VERSION "FL_IC_CANFD"

NS_ :

BS_:

BU_: AVAS BBCM CMSM DVR EAMP EPC FLZCU ICC PCL PLG SBOX SCU

BO_ 1364 ICC_RISD_44: 64 ICC
 SG_ ICC_RISD_FrameCounter : 1|2@0+ (1,0) [0|3] ""  FLZCU
 SG_ ICC_RISD_RollingCounter : 3|2@0+ (1,0) [0|3] ""  FLZCU
 SG_ ICC_RISD_Pixel1_OnOff : 8|1@0+ (1,0) [0|1] ""  FLZCU
 SG_ ICC_RISD_Pixel2_OnOff : 9|1@0+ (1,0) [0|1] ""  FLZCU
 SG_ ICC_RISD_Pixel3_OnOff : 10|1@0+ (1,0) [0|1] ""  FLZCU
 SG_ ICC_RISD_Pixel4_OnOff : 11|1@0+ (1,0) [0|1] ""  FLZCU
 SG_ ICC_RISD_Pixel5_OnOff : 12|1@0+ (1,0) [0|1] ""  FLZCU
 SG_ ICC_RISD_Pixel6_OnOff : 13|1@0+ (1,0) [0|1] ""  FLZCU
 SG_ ICC_RISD_Pixel7_OnOff : 14|1@0+ (1,0) [0|1] ""  FLZCU
 SG_ ICC_RISD_Pixel8_OnOff : 15|1@0+ (1,0) [0|1] ""  FLZCU
 SG_ ICC_RISD_Pixel9_OnOff : 16|1@0+ (1,0) [0|1] ""  FLZCU
 SG_ ICC_RISD_Pixel10_OnOff : 17|1@0+ (1,0) [0|1] ""  FLZCU
 SG_ ICC_RISD_Pixel11_OnOff : 18|1@0+ (1,0) [0|1] ""  FLZCU
 SG_ ICC_RISD_Pixel12_OnOff : 19|1@0+ (1,0) [0|1] ""  FLZCU
 SG_ ICC_RISD_Pixel13_OnOff : 20|1@0+ (1,0) [0|1] ""  FLZCU
 SG_ ICC_RISD_Pixel14_OnOff : 21|1@0+ (1,0) [0|1] ""  FLZCU
 SG_ ICC_RISD_Pixel15_OnOff : 22|1@0+ (1,0) [0|1] ""  FLZCU
 SG_ ICC_RISD_Pixel16_OnOff : 23|1@0+ (1,0) [0|1] ""  FLZCU
 SG_ ICC_RISD_Pixel17_OnOff : 24|1@0+ (1,0) [0|1] ""  FLZCU
 SG_ ICC_RISD_Pixel18_OnOff : 25|1@0+ (1,0) [0|1] ""  FLZCU
 SG_ ICC_RISD_Pixel19_OnOff : 26|1@0+ (1,0) [0|1] ""  FLZCU
 SG_ ICC_RISD_Pixel20_OnOff : 27|1@0+ (1,0) [0|1] ""  FLZCU
 SG_ ICC_RISD_Pixel21_OnOff : 28|1@0+ (1,0) [0|1] ""  FLZCU
 SG_ ICC_RISD_Pixel22_OnOff : 29|1@0+ (1,0) [0|1] ""  FLZCU
 SG_ ICC_RISD_Pixel23_OnOff : 30|1@0+ (1,0) [0|1] ""  FLZCU
 SG_ ICC_RISD_Pixel24_OnOff : 31|1@0+ (1,0) [0|1] ""  FLZCU
 SG_ ICC_RISD_Pixel25_OnOff : 32|1@0+ (1,0) [0|1] ""  FLZCU
 SG_ ICC_RISD_Pixel26_OnOff : 33|1@0+ (1,0) [0|1] ""  FLZCU
 SG_ ICC_RISD_Pixel27_OnOff : 34|1@0+ (1,0) [0|1] ""  FLZCU
 SG_ ICC_RISD_Pixel28_OnOff : 35|1@0+ (1,0) [0|1] ""  FLZCU
 SG_ ICC_RISD_Pixel29_OnOff : 36|1@0+ (1,0) [0|1] ""  FLZCU
 SG_ ICC_RISD_Pixel30_OnOff : 37|1@0+ (1,0) [0|1] ""  FLZCU
 SG_ ICC_RISD_Pixel31_OnOff : 38|1@0+ (1,0) [0|1] ""  FLZCU
 SG_ ICC_RISD_Pixel32_OnOff : 39|1@0+ (1,0) [0|1] ""  FLZCU
 SG_ ICC_RISD_Pixel33_OnOff : 40|1@0+ (1,0) [0|1] ""  FLZCU
 SG_ ICC_RISD_Pixel34_OnOff : 41|1@0+ (1,0) [0|1] ""  FLZCU
 SG_ ICC_RISD_Pixel35_OnOff : 42|1@0+ (1,0) [0|1] ""  FLZCU
 SG_ ICC_RISD_Pixel36_OnOff : 43|1@0+ (1,0) [0|1] ""  FLZCU
 SG_ ICC_RISD_Pixel37_OnOff : 44|1@0+ (1,0) [0|1] ""  FLZCU
 SG_ ICC_RISD_Pixel38_OnOff : 45|1@0+ (1,0) [0|1] ""  FLZCU
 SG_ ICC_RISD_Pixel39_OnOff : 46|1@0+ (1,0) [0|1] ""  FLZCU
 SG_ ICC_RISD_Pixel40_OnOff : 47|1@0+ (1,0) [0|1] ""  FLZCU
 SG_ ICC_RISD_Pixel41_OnOff : 48|1@0+ (1,0) [0|1] ""  FLZCU
 SG_ ICC_RISD_Pixel42_OnOff : 49|1@0+ (1,0) [0|1] ""  FLZCU
 SG_ ICC_RISD_Pixel43_OnOff : 50|1@0+ (1,0) [0|1] ""  FLZCU
 SG_ ICC_RISD_Pixel44_OnOff : 51|1@0+ (1,0) [0|1] ""  FLZCU
 SG_ ICC_RISD_Pixel45_OnOff : 52|1@0+ (1,0) [0|1] ""  FLZCU
 SG_ ICC_RISD_Pixel46_OnOff : 53|1@0+ (1,0) [0|1] ""  FLZCU
 SG_ ICC_RISD_Pixel47_OnOff : 54|1@0+ (1,0) [0|1] ""  FLZCU
 SG_ ICC_RISD_Pixel48_OnOff : 55|1@0+ (1,0) [0|1] ""  FLZCU
 SG_ ICC_RISD_Pixel49_OnOff : 56|1@0+ (1,0) [0|1] ""  FLZCU
 SG_ ICC_RISD_Pixel50_OnOff : 57|1@0+ (1,0) [0|1] ""  FLZCU
 SG_ ICC_RISD_Pixel51_OnOff : 58|1@0+ (1,0) [0|1] ""  FLZCU
 SG_ ICC_RISD_Pixel52_OnOff : 59|1@0+ (1,0) [0|1] ""  FLZCU
 SG_ ICC_RISD_Pixel53_OnOff : 60|1@0+ (1,0) [0|1] ""  FLZCU
 SG_ ICC_RISD_Pixel54_OnOff : 61|1@0+ (1,0) [0|1] ""  FLZCU
 SG_ ICC_RISD_Pixel55_OnOff : 62|1@0+ (1,0) [0|1] ""  FLZCU
 SG_ ICC_RISD_Pixel56_OnOff : 63|1@0+ (1,0) [0|1] ""  FLZCU
 SG_ ICC_RISD_Pixel57_OnOff : 64|1@0+ (1,0) [0|1] ""  FLZCU
 SG_ ICC_RISD_Pixel58_OnOff : 65|1@0+ (1,0) [0|1] ""  FLZCU
 SG_ ICC_RISD_Pixel59_OnOff : 66|1@0+ (1,0) [0|1] ""  FLZCU
 SG_ ICC_RISD_Pixel60_OnOff : 67|1@0+ (1,0) [0|1] ""  FLZCU
 SG_ ICC_RISD_Pixel61_OnOff : 68|1@0+ (1,0) [0|1] ""  FLZCU
 SG_ ICC_RISD_Pixel62_OnOff : 69|1@0+ (1,0) [0|1] ""  FLZCU
 SG_ ICC_RISD_Pixel63_OnOff : 70|1@0+ (1,0) [0|1] ""  FLZCU
 SG_ ICC_RISD_Pixel64_OnOff : 71|1@0+ (1,0) [0|1] ""  FLZCU
 SG_ ICC_RISD_Pixel65_OnOff : 72|1@0+ (1,0) [0|1] ""  FLZCU
 SG_ ICC_RISD_Pixel66_OnOff : 73|1@0+ (1,0) [0|1] ""  FLZCU
 SG_ ICC_RISD_Pixel67_OnOff : 74|1@0+ (1,0) [0|1] ""  FLZCU
 SG_ ICC_RISD_Pixel68_OnOff : 75|1@0+ (1,0) [0|1] ""  FLZCU
 SG_ ICC_RISD_Pixel69_OnOff : 76|1@0+ (1,0) [0|1] ""  FLZCU
 SG_ ICC_RISD_Pixel70_OnOff : 77|1@0+ (1,0) [0|1] ""  FLZCU
 SG_ ICC_RISD_Pixel71_OnOff : 78|1@0+ (1,0) [0|1] ""  FLZCU
 SG_ ICC_RISD_Pixel72_OnOff : 79|1@0+ (1,0) [0|1] ""  FLZCU
 SG_ ICC_RISD_Pixel73_OnOff : 80|1@0+ (1,0) [0|1] ""  FLZCU
 SG_ ICC_RISD_Pixel74_OnOff : 81|1@0+ (1,0) [0|1] ""  FLZCU
 SG_ ICC_RISD_Pixel75_OnOff : 82|1@0+ (1,0) [0|1] ""  FLZCU
 SG_ ICC_RISD_Pixel76_OnOff : 83|1@0+ (1,0) [0|1] ""  FLZCU
 SG_ ICC_RISD_Pixel77_OnOff : 84|1@0+ (1,0) [0|1] ""  FLZCU
 SG_ ICC_RISD_Pixel78_OnOff : 85|1@0+ (1,0) [0|1] ""  FLZCU
 SG_ ICC_RISD_Pixel79_OnOff : 86|1@0+ (1,0) [0|1] ""  FLZCU
 SG_ ICC_RISD_Pixel80_OnOff : 87|1@0+ (1,0) [0|1] ""  FLZCU
 SG_ ICC_RISD_Pixel81_OnOff : 88|1@0+ (1,0) [0|1] ""  FLZCU
 SG_ ICC_RISD_Pixel82_OnOff : 89|1@0+ (1,0) [0|1] ""  FLZCU
 SG_ ICC_RISD_Pixel83_OnOff : 90|1@0+ (1,0) [0|1] ""  FLZCU
 SG_ ICC_RISD_Pixel84_OnOff : 91|1@0+ (1,0) [0|1] ""  FLZCU
 SG_ ICC_RISD_Pixel85_OnOff : 92|1@0+ (1,0) [0|1] ""  FLZCU
 SG_ ICC_RISD_Pixel86_OnOff : 93|1@0+ (1,0) [0|1] ""  FLZCU
 SG_ ICC_RISD_Pixel87_OnOff : 94|1@0+ (1,0) [0|1] ""  FLZCU
 SG_ ICC_RISD_Pixel88_OnOff : 95|1@0+ (1,0) [0|1] ""  FLZCU
 SG_ ICC_RISD_Pixel89_OnOff : 96|1@0+ (1,0) [0|1] ""  FLZCU
 SG_ ICC_RISD_Pixel90_OnOff : 97|1@0+ (1,0) [0|1] ""  FLZCU
 SG_ ICC_RISD_Pixel91_OnOff : 98|1@0+ (1,0) [0|1] ""  FLZCU
 SG_ ICC_RISD_Pixel92_OnOff : 99|1@0+ (1,0) [0|1] ""  FLZCU
 SG_ ICC_RISD_Pixel93_OnOff : 100|1@0+ (1,0) [0|1] ""  FLZCU
 SG_ ICC_RISD_Pixel94_OnOff : 101|1@0+ (1,0) [0|1] ""  FLZCU
 SG_ ICC_RISD_Pixel95_OnOff : 102|1@0+ (1,0) [0|1] ""  FLZCU
 SG_ ICC_RISD_Pixel96_OnOff : 103|1@0+ (1,0) [0|1] ""  FLZCU
 SG_ ICC_RISD_Pixel97_OnOff : 104|1@0+ (1,0) [0|1] ""  FLZCU
 SG_ ICC_RISD_Pixel98_OnOff : 105|1@0+ (1,0) [0|1] ""  FLZCU
 SG_ ICC_RISD_Pixel99_OnOff : 106|1@0+ (1,0) [0|1] ""  FLZCU
 SG_ ICC_RISD_Pixel100_OnOff : 107|1@0+ (1,0) [0|1] ""  FLZCU
 SG_ ICC_RISD_Pixel101_OnOff : 108|1@0+ (1,0) [0|1] ""  FLZCU
 SG_ ICC_RISD_Pixel102_OnOff : 109|1@0+ (1,0) [0|1] ""  FLZCU
 SG_ ICC_RISD_Pixel103_OnOff : 110|1@0+ (1,0) [0|1] ""  FLZCU
 SG_ ICC_RISD_Pixel104_OnOff : 111|1@0+ (1,0) [0|1] ""  FLZCU
 SG_ ICC_RISD_Pixel105_OnOff : 112|1@0+ (1,0) [0|1] ""  FLZCU
 SG_ ICC_RISD_Pixel106_OnOff : 113|1@0+ (1,0) [0|1] ""  FLZCU
 SG_ ICC_RISD_Pixel107_OnOff : 114|1@0+ (1,0) [0|1] ""  FLZCU
 SG_ ICC_RISD_Pixel108_OnOff : 115|1@0+ (1,0) [0|1] ""  FLZCU
 SG_ ICC_RISD_Pixel109_OnOff : 116|1@0+ (1,0) [0|1] ""  FLZCU
 SG_ ICC_RISD_Pixel110_OnOff : 117|1@0+ (1,0) [0|1] ""  FLZCU
 SG_ ICC_RISD_Pixel111_OnOff : 118|1@0+ (1,0) [0|1] ""  FLZCU
 SG_ ICC_RISD_Pixel112_OnOff : 119|1@0+ (1,0) [0|1] ""  FLZCU
 SG_ ICC_RISD_Pixel113_OnOff : 120|1@0+ (1,0) [0|1] ""  FLZCU
 SG_ ICC_RISD_Pixel114_OnOff : 121|1@0+ (1,0) [0|1] ""  FLZCU
 SG_ ICC_RISD_Pixel115_OnOff : 122|1@0+ (1,0) [0|1] ""  FLZCU
 SG_ ICC_RISD_Pixel116_OnOff : 123|1@0+ (1,0) [0|1] ""  FLZCU
 SG_ ICC_RISD_Pixel117_OnOff : 124|1@0+ (1,0) [0|1] ""  FLZCU
 SG_ ICC_RISD_Pixel118_OnOff : 125|1@0+ (1,0) [0|1] ""  FLZCU
 SG_ ICC_RISD_Pixel119_OnOff : 126|1@0+ (1,0) [0|1] ""  FLZCU
 SG_ ICC_RISD_Pixel120_OnOff : 127|1@0+ (1,0) [0|1] ""  FLZCU
 SG_ ICC_RISD_Pixel121_OnOff : 128|1@0+ (1,0) [0|1] ""  FLZCU
 SG_ ICC_RISD_Pixel122_OnOff : 129|1@0+ (1,0) [0|1] ""  FLZCU
 SG_ ICC_RISD_Pixel123_OnOff : 130|1@0+ (1,0) [0|1] ""  FLZCU
 SG_ ICC_RISD_Pixel124_OnOff : 131|1@0+ (1,0) [0|1] ""  FLZCU
 SG_ ICC_RISD_Pixel125_OnOff : 132|1@0+ (1,0) [0|1] ""  FLZCU
 SG_ ICC_RISD_Pixel126_OnOff : 133|1@0+ (1,0) [0|1] ""  FLZCU
 SG_ ICC_RISD_Pixel127_OnOff : 134|1@0+ (1,0) [0|1] ""  FLZCU
 SG_ ICC_RISD_Pixel128_OnOff : 135|1@0+ (1,0) [0|1] ""  FLZCU
 SG_ ICC_RISD_Pixel129_OnOff : 136|1@0+ (1,0) [0|1] ""  FLZCU
 SG_ ICC_RISD_Pixel130_OnOff : 137|1@0+ (1,0) [0|1] ""  FLZCU
 SG_ ICC_RISD_Pixel131_OnOff : 138|1@0+ (1,0) [0|1] ""  FLZCU
 SG_ ICC_RISD_Pixel132_OnOff : 139|1@0+ (1,0) [0|1] ""  FLZCU
 SG_ ICC_RISD_Pixel133_OnOff : 140|1@0+ (1,0) [0|1] ""  FLZCU
 SG_ ICC_RISD_Pixel134_OnOff : 141|1@0+ (1,0) [0|1] ""  FLZCU
 SG_ ICC_RISD_Pixel135_OnOff : 142|1@0+ (1,0) [0|1] ""  FLZCU
 SG_ ICC_RISD_Pixel136_OnOff : 143|1@0+ (1,0) [0|1] ""  FLZCU
 SG_ ICC_RISD_Pixel137_OnOff : 144|1@0+ (1,0) [0|1] ""  FLZCU
 SG_ ICC_RISD_Pixel138_OnOff : 145|1@0+ (1,0) [0|1] ""  FLZCU
 SG_ ICC_RISD_Pixel139_OnOff : 146|1@0+ (1,0) [0|1] ""  FLZCU
 SG_ ICC_RISD_Pixel140_OnOff : 147|1@0+ (1,0) [0|1] ""  FLZCU
 SG_ ICC_RISD_Pixel141_OnOff : 148|1@0+ (1,0) [0|1] ""  FLZCU
 SG_ ICC_RISD_Pixel142_OnOff : 149|1@0+ (1,0) [0|1] ""  FLZCU
 SG_ ICC_RISD_Pixel143_OnOff : 150|1@0+ (1,0) [0|1] ""  FLZCU
 SG_ ICC_RISD_Pixel144_OnOff : 151|1@0+ (1,0) [0|1] ""  FLZCU
 SG_ ICC_RISD_Pixel145_OnOff : 152|1@0+ (1,0) [0|1] ""  FLZCU
 SG_ ICC_RISD_Pixel146_OnOff : 153|1@0+ (1,0) [0|1] ""  FLZCU
 SG_ ICC_RISD_Pixel147_OnOff : 154|1@0+ (1,0) [0|1] ""  FLZCU
 SG_ ICC_RISD_Pixel148_OnOff : 155|1@0+ (1,0) [0|1] ""  FLZCU
 SG_ ICC_RISD_Pixel149_OnOff : 156|1@0+ (1,0) [0|1] ""  FLZCU
 SG_ ICC_RISD_Pixel150_OnOff : 157|1@0+ (1,0) [0|1] ""  FLZCU
 SG_ ICC_RISD_Pixel151_OnOff : 158|1@0+ (1,0) [0|1] ""  FLZCU
 SG_ ICC_RISD_Pixel152_OnOff : 159|1@0+ (1,0) [0|1] ""  FLZCU
 SG_ ICC_RISD_Pixel153_OnOff : 160|1@0+ (1,0) [0|1] ""  FLZCU
 SG_ ICC_RISD_Pixel154_OnOff : 161|1@0+ (1,0) [0|1] ""  FLZCU
 SG_ ICC_RISD_Pixel155_OnOff : 162|1@0+ (1,0) [0|1] ""  FLZCU
 SG_ ICC_RISD_Pixel156_OnOff : 163|1@0+ (1,0) [0|1] ""  FLZCU
 SG_ ICC_RISD_Pixel157_OnOff : 164|1@0+ (1,0) [0|1] ""  FLZCU
 SG_ ICC_RISD_Pixel158_OnOff : 165|1@0+ (1,0) [0|1] ""  FLZCU
 SG_ ICC_RISD_Pixel159_OnOff : 166|1@0+ (1,0) [0|1] ""  FLZCU
 SG_ ICC_RISD_Pixel160_OnOff : 167|1@0+ (1,0) [0|1] ""  FLZCU
 SG_ ICC_RISD_Pixel161_OnOff : 168|1@0+ (1,0) [0|1] ""  FLZCU
 SG_ ICC_RISD_Pixel162_OnOff : 169|1@0+ (1,0) [0|1] ""  FLZCU
 SG_ ICC_RISD_Pixel163_OnOff : 170|1@0+ (1,0) [0|1] ""  FLZCU
 SG_ ICC_RISD_Pixel164_OnOff : 171|1@0+ (1,0) [0|1] ""  FLZCU
 SG_ ICC_RISD_Pixel165_OnOff : 172|1@0+ (1,0) [0|1] ""  FLZCU
 SG_ ICC_RISD_Pixel166_OnOff : 173|1@0+ (1,0) [0|1] ""  FLZCU
 SG_ ICC_RISD_Pixel167_OnOff : 174|1@0+ (1,0) [0|1] ""  FLZCU
 SG_ ICC_RISD_Pixel168_OnOff : 175|1@0+ (1,0) [0|1] ""  FLZCU
 SG_ ICC_RISD_Pixel169_OnOff : 176|1@0+ (1,0) [0|1] ""  FLZCU
 SG_ ICC_RISD_Pixel170_OnOff : 177|1@0+ (1,0) [0|1] ""  FLZCU
 SG_ ICC_RISD_Pixel171_OnOff : 178|1@0+ (1,0) [0|1] ""  FLZCU
 SG_ ICC_RISD_Pixel172_OnOff : 179|1@0+ (1,0) [0|1] ""  FLZCU
 SG_ ICC_RISD_Pixel173_OnOff : 180|1@0+ (1,0) [0|1] ""  FLZCU
 SG_ ICC_RISD_Pixel174_OnOff : 181|1@0+ (1,0) [0|1] ""  FLZCU
 SG_ ICC_RISD_Pixel175_OnOff : 182|1@0+ (1,0) [0|1] ""  FLZCU
 SG_ ICC_RISD_Pixel176_OnOff : 183|1@0+ (1,0) [0|1] ""  FLZCU
 SG_ ICC_RISD_Pixel177_OnOff : 184|1@0+ (1,0) [0|1] ""  FLZCU
 SG_ ICC_RISD_Pixel178_OnOff : 185|1@0+ (1,0) [0|1] ""  FLZCU
 SG_ ICC_RISD_Pixel179_OnOff : 186|1@0+ (1,0) [0|1] ""  FLZCU
 SG_ ICC_RISD_Pixel180_OnOff : 187|1@0+ (1,0) [0|1] ""  FLZCU
 SG_ ICC_RISD_Pixel181_OnOff : 188|1@0+ (1,0) [0|1] ""  FLZCU
 SG_ ICC_RISD_Pixel182_OnOff : 189|1@0+ (1,0) [0|1] ""  FLZCU
 SG_ ICC_RISD_Pixel183_OnOff : 190|1@0+ (1,0) [0|1] ""  FLZCU
 SG_ ICC_RISD_Pixel184_OnOff : 191|1@0+ (1,0) [0|1] ""  FLZCU
 SG_ ICC_RISD_Pixel185_OnOff : 192|1@0+ (1,0) [0|1] ""  FLZCU
 SG_ ICC_RISD_Pixel186_OnOff : 193|1@0+ (1,0) [0|1] ""  FLZCU
 SG_ ICC_RISD_Pixel187_OnOff : 194|1@0+ (1,0) [0|1] ""  FLZCU
 SG_ ICC_RISD_Pixel188_OnOff : 195|1@0+ (1,0) [0|1] ""  FLZCU
 SG_ ICC_RISD_Pixel189_OnOff : 196|1@0+ (1,0) [0|1] ""  FLZCU
 SG_ ICC_RISD_Pixel190_OnOff : 197|1@0+ (1,0) [0|1] ""  FLZCU
 SG_ ICC_RISD_Pixel191_OnOff : 198|1@0+ (1,0) [0|1] ""  FLZCU
 SG_ ICC_RISD_Pixel192_OnOff : 199|1@0+ (1,0) [0|1] ""  FLZCU
 SG_ ICC_RISD_Pixel193_OnOff : 200|1@0+ (1,0) [0|1] ""  FLZCU
 SG_ ICC_RISD_Pixel194_OnOff : 201|1@0+ (1,0) [0|1] ""  FLZCU
 SG_ ICC_RISD_Pixel195_OnOff : 202|1@0+ (1,0) [0|1] ""  FLZCU
 SG_ ICC_RISD_Pixel196_OnOff : 203|1@0+ (1,0) [0|1] ""  FLZCU
 SG_ ICC_RISD_Pixel197_OnOff : 204|1@0+ (1,0) [0|1] ""  FLZCU
 SG_ ICC_RISD_Pixel198_OnOff : 205|1@0+ (1,0) [0|1] ""  FLZCU
 SG_ ICC_RISD_Pixel199_OnOff : 206|1@0+ (1,0) [0|1] ""  FLZCU
 SG_ ICC_RISD_Pixel200_OnOff : 207|1@0+ (1,0) [0|1] ""  FLZCU
 SG_ ICC_RISD_Pixel201_OnOff : 208|1@0+ (1,0) [0|1] ""  FLZCU
 SG_ ICC_RISD_Pixel202_OnOff : 209|1@0+ (1,0) [0|1] ""  FLZCU
 SG_ ICC_RISD_Pixel203_OnOff : 210|1@0+ (1,0) [0|1] ""  FLZCU
 SG_ ICC_RISD_Pixel204_OnOff : 211|1@0+ (1,0) [0|1] ""  FLZCU
 SG_ ICC_RISD_Pixel205_OnOff : 212|1@0+ (1,0) [0|1] ""  FLZCU
 SG_ ICC_RISD_Pixel206_OnOff : 213|1@0+ (1,0) [0|1] ""  FLZCU
 SG_ ICC_RISD_Pixel207_OnOff : 214|1@0+ (1,0) [0|1] ""  FLZCU
 SG_ ICC_RISD_Pixel208_OnOff : 215|1@0+ (1,0) [0|1] ""  FLZCU
 SG_ ICC_RISD_Pixel209_OnOff : 216|1@0+ (1,0) [0|1] ""  FLZCU
 SG_ ICC_RISD_Pixel210_OnOff : 217|1@0+ (1,0) [0|1] ""  FLZCU
 SG_ ICC_RISD_Pixel211_OnOff : 218|1@0+ (1,0) [0|1] ""  FLZCU
 SG_ ICC_RISD_Pixel212_OnOff : 219|1@0+ (1,0) [0|1] ""  FLZCU
 SG_ ICC_RISD_Pixel213_OnOff : 220|1@0+ (1,0) [0|1] ""  FLZCU
 SG_ ICC_RISD_Pixel214_OnOff : 221|1@0+ (1,0) [0|1] ""  FLZCU
 SG_ ICC_RISD_Pixel215_OnOff : 222|1@0+ (1,0) [0|1] ""  FLZCU
 SG_ ICC_RISD_Pixel216_OnOff : 223|1@0+ (1,0) [0|1] ""  FLZCU
 SG_ ICC_RISD_Pixel217_OnOff : 224|1@0+ (1,0) [0|1] ""  FLZCU
 SG_ ICC_RISD_Pixel218_OnOff : 225|1@0+ (1,0) [0|1] ""  FLZCU
 SG_ ICC_RISD_Pixel219_OnOff : 226|1@0+ (1,0) [0|1] ""  FLZCU
 SG_ ICC_RISD_Pixel220_OnOff : 227|1@0+ (1,0) [0|1] ""  FLZCU
 SG_ ICC_RISD_Pixel221_OnOff : 228|1@0+ (1,0) [0|1] ""  FLZCU
 SG_ ICC_RISD_Pixel222_OnOff : 229|1@0+ (1,0) [0|1] ""  FLZCU
 SG_ ICC_RISD_Pixel223_OnOff : 230|1@0+ (1,0) [0|1] ""  FLZCU
 SG_ ICC_RISD_Pixel224_OnOff : 231|1@0+ (1,0) [0|1] ""  FLZCU
 SG_ ICC_RISD_Pixel225_OnOff : 232|1@0+ (1,0) [0|1] ""  FLZCU
 SG_ ICC_RISD_Pixel226_OnOff : 233|1@0+ (1,0) [0|1] ""  FLZCU
 SG_ ICC_RISD_Pixel227_OnOff : 234|1@0+ (1,0) [0|1] ""  FLZCU
 SG_ ICC_RISD_Pixel228_OnOff : 235|1@0+ (1,0) [0|1] ""  FLZCU
 SG_ ICC_RISD_Pixel229_OnOff : 236|1@0+ (1,0) [0|1] ""  FLZCU
 SG_ ICC_RISD_Pixel230_OnOff : 237|1@0+ (1,0) [0|1] ""  FLZCU
 SG_ ICC_RISD_Pixel231_OnOff : 238|1@0+ (1,0) [0|1] ""  FLZCU
 SG_ ICC_RISD_Pixel232_OnOff : 239|1@0+ (1,0) [0|1] ""  FLZCU
 SG_ ICC_RISD_Pixel233_OnOff : 240|1@0+ (1,0) [0|1] ""  FLZCU
 SG_ ICC_RISD_Pixel234_OnOff : 241|1@0+ (1,0) [0|1] ""  FLZCU
 SG_ ICC_RISD_Pixel235_OnOff : 242|1@0+ (1,0) [0|1] ""  FLZCU
 SG_ ICC_RISD_Pixel236_OnOff : 243|1@0+ (1,0) [0|1] ""  FLZCU
 SG_ ICC_RISD_Pixel237_OnOff : 244|1@0+ (1,0) [0|1] ""  FLZCU
 SG_ ICC_RISD_Pixel238_OnOff : 245|1@0+ (1,0) [0|1] ""  FLZCU
 SG_ ICC_RISD_Pixel239_OnOff : 246|1@0+ (1,0) [0|1] ""  FLZCU
 SG_ ICC_RISD_Pixel240_OnOff : 247|1@0+ (1,0) [0|1] ""  FLZCU
 SG_ ICC_RISD_Pixel241_OnOff : 248|1@0+ (1,0) [0|1] ""  FLZCU
 SG_ ICC_RISD_Pixel242_OnOff : 249|1@0+ (1,0) [0|1] ""  FLZCU
 SG_ ICC_RISD_Pixel243_OnOff : 250|1@0+ (1,0) [0|1] ""  FLZCU
 SG_ ICC_RISD_Pixel244_OnOff : 251|1@0+ (1,0) [0|1] ""  FLZCU
 SG_ ICC_RISD_Pixel245_OnOff : 252|1@0+ (1,0) [0|1] ""  FLZCU
 SG_ ICC_RISD_Pixel246_OnOff : 253|1@0+ (1,0) [0|1] ""  FLZCU
 SG_ ICC_RISD_Pixel247_OnOff : 254|1@0+ (1,0) [0|1] ""  FLZCU
 SG_ ICC_RISD_Pixel248_OnOff : 255|1@0+ (1,0) [0|1] ""  FLZCU
 SG_ ICC_RISD_Pixel249_OnOff : 256|1@0+ (1,0) [0|1] ""  FLZCU
 SG_ ICC_RISD_Pixel250_OnOff : 257|1@0+ (1,0) [0|1] ""  FLZCU
 SG_ ICC_RISD_Pixel251_OnOff : 258|1@0+ (1,0) [0|1] ""  FLZCU
 SG_ ICC_RISD_Pixel252_OnOff : 259|1@0+ (1,0) [0|1] ""  FLZCU
 SG_ ICC_RISD_Pixel253_OnOff : 260|1@0+ (1,0) [0|1] ""  FLZCU
 SG_ ICC_RISD_Pixel254_OnOff : 261|1@0+ (1,0) [0|1] ""  FLZCU
 SG_ ICC_RISD_Pixel255_OnOff : 262|1@0+ (1,0) [0|1] ""  FLZCU
 SG_ ICC_RISD_Pixel256_OnOff : 263|1@0+ (1,0) [0|1] ""  FLZCU
 SG_ ICC_RISD_Pixel257_OnOff : 264|1@0+ (1,0) [0|1] ""  FLZCU
 SG_ ICC_RISD_Pixel258_OnOff : 265|1@0+ (1,0) [0|1] ""  FLZCU
 SG_ ICC_RISD_Pixel259_OnOff : 266|1@0+ (1,0) [0|1] ""  FLZCU
 SG_ ICC_RISD_Pixel260_OnOff : 267|1@0+ (1,0) [0|1] ""  FLZCU
 SG_ ICC_RISD_Pixel261_OnOff : 268|1@0+ (1,0) [0|1] ""  FLZCU
 SG_ ICC_RISD_Pixel262_OnOff : 269|1@0+ (1,0) [0|1] ""  FLZCU
 SG_ ICC_RISD_Pixel263_OnOff : 270|1@0+ (1,0) [0|1] ""  FLZCU
 SG_ ICC_RISD_Pixel264_OnOff : 271|1@0+ (1,0) [0|1] ""  FLZCU
 SG_ ICC_RISD_Pixel265_OnOff : 272|1@0+ (1,0) [0|1] ""  FLZCU
 SG_ ICC_RISD_Pixel266_OnOff : 273|1@0+ (1,0) [0|1] ""  FLZCU
 SG_ ICC_RISD_Pixel267_OnOff : 274|1@0+ (1,0) [0|1] ""  FLZCU
 SG_ ICC_RISD_Pixel268_OnOff : 275|1@0+ (1,0) [0|1] ""  FLZCU
 SG_ ICC_RISD_Pixel269_OnOff : 276|1@0+ (1,0) [0|1] ""  FLZCU
 SG_ ICC_RISD_Pixel270_OnOff : 277|1@0+ (1,0) [0|1] ""  FLZCU
 SG_ ICC_RISD_Pixel271_OnOff : 278|1@0+ (1,0) [0|1] ""  FLZCU
 SG_ ICC_RISD_Pixel272_OnOff : 279|1@0+ (1,0) [0|1] ""  FLZCU
 SG_ ICC_RISD_Pixel273_OnOff : 280|1@0+ (1,0) [0|1] ""  FLZCU
 SG_ ICC_RISD_Pixel274_OnOff : 281|1@0+ (1,0) [0|1] ""  FLZCU
 SG_ ICC_RISD_Pixel275_OnOff : 282|1@0+ (1,0) [0|1] ""  FLZCU
 SG_ ICC_RISD_Pixel276_OnOff : 283|1@0+ (1,0) [0|1] ""  FLZCU
 SG_ ICC_RISD_Pixel277_OnOff : 284|1@0+ (1,0) [0|1] ""  FLZCU
 SG_ ICC_RISD_Pixel278_OnOff : 285|1@0+ (1,0) [0|1] ""  FLZCU
 SG_ ICC_RISD_Pixel279_OnOff : 286|1@0+ (1,0) [0|1] ""  FLZCU
 SG_ ICC_RISD_Pixel280_OnOff : 287|1@0+ (1,0) [0|1] ""  FLZCU
 SG_ ICC_RISD_Pixel281_OnOff : 288|1@0+ (1,0) [0|1] ""  FLZCU
 SG_ ICC_RISD_Pixel282_OnOff : 289|1@0+ (1,0) [0|1] ""  FLZCU
 SG_ ICC_RISD_Pixel283_OnOff : 290|1@0+ (1,0) [0|1] ""  FLZCU
 SG_ ICC_RISD_Pixel284_OnOff : 291|1@0+ (1,0) [0|1] ""  FLZCU
 SG_ ICC_RISD_Pixel285_OnOff : 292|1@0+ (1,0) [0|1] ""  FLZCU
 SG_ ICC_RISD_Pixel286_OnOff : 293|1@0+ (1,0) [0|1] ""  FLZCU
 SG_ ICC_RISD_Pixel287_OnOff : 294|1@0+ (1,0) [0|1] ""  FLZCU
 SG_ ICC_RISD_Pixel288_OnOff : 295|1@0+ (1,0) [0|1] ""  FLZCU
 SG_ ICC_RISD_Pixel289_OnOff : 296|1@0+ (1,0) [0|1] ""  FLZCU
 SG_ ICC_RISD_Pixel290_OnOff : 297|1@0+ (1,0) [0|1] ""  FLZCU
 SG_ ICC_RISD_Pixel291_OnOff : 298|1@0+ (1,0) [0|1] ""  FLZCU
 SG_ ICC_RISD_Pixel292_OnOff : 299|1@0+ (1,0) [0|1] ""  FLZCU
 SG_ ICC_RISD_Pixel293_OnOff : 300|1@0+ (1,0) [0|1] ""  FLZCU
 SG_ ICC_RISD_Pixel294_OnOff : 301|1@0+ (1,0) [0|1] ""  FLZCU
 SG_ ICC_RISD_Pixel295_OnOff : 302|1@0+ (1,0) [0|1] ""  FLZCU
 SG_ ICC_RISD_Pixel296_OnOff : 303|1@0+ (1,0) [0|1] ""  FLZCU
 SG_ ICC_RISD_Pixel297_OnOff : 304|1@0+ (1,0) [0|1] ""  FLZCU
 SG_ ICC_RISD_Pixel298_OnOff : 305|1@0+ (1,0) [0|1] ""  FLZCU
 SG_ ICC_RISD_Pixel299_OnOff : 306|1@0+ (1,0) [0|1] ""  FLZCU
 SG_ ICC_RISD_Pixel300_OnOff : 307|1@0+ (1,0) [0|1] ""  FLZCU
 SG_ ICC_RISD_Pixel301_OnOff : 308|1@0+ (1,0) [0|1] ""  FLZCU
 SG_ ICC_RISD_Pixel302_OnOff : 309|1@0+ (1,0) [0|1] ""  FLZCU
 SG_ ICC_RISD_Pixel303_OnOff : 310|1@0+ (1,0) [0|1] ""  FLZCU
 SG_ ICC_RISD_Pixel304_OnOff : 311|1@0+ (1,0) [0|1] ""  FLZCU
 SG_ ICC_RISD_Pixel305_OnOff : 312|1@0+ (1,0) [0|1] ""  FLZCU
 SG_ ICC_RISD_Pixel306_OnOff : 313|1@0+ (1,0) [0|1] ""  FLZCU
 SG_ ICC_RISD_Pixel307_OnOff : 314|1@0+ (1,0) [0|1] ""  FLZCU
 SG_ ICC_RISD_Pixel308_OnOff : 315|1@0+ (1,0) [0|1] ""  FLZCU
 SG_ ICC_RISD_Pixel309_OnOff : 316|1@0+ (1,0) [0|1] ""  FLZCU
 SG_ ICC_RISD_Pixel310_OnOff : 317|1@0+ (1,0) [0|1] ""  FLZCU
 SG_ ICC_RISD_Pixel311_OnOff : 318|1@0+ (1,0) [0|1] ""  FLZCU
 SG_ ICC_RISD_Pixel312_OnOff : 319|1@0+ (1,0) [0|1] ""  FLZCU
 SG_ ICC_RISD_Pixel313_OnOff : 320|1@0+ (1,0) [0|1] ""  FLZCU
 SG_ ICC_RISD_Pixel314_OnOff : 321|1@0+ (1,0) [0|1] ""  FLZCU
 SG_ ICC_RISD_Pixel315_OnOff : 322|1@0+ (1,0) [0|1] ""  FLZCU
 SG_ ICC_RISD_Pixel316_OnOff : 323|1@0+ (1,0) [0|1] ""  FLZCU
 SG_ ICC_RISD_Pixel317_OnOff : 324|1@0+ (1,0) [0|1] ""  FLZCU
 SG_ ICC_RISD_Pixel318_OnOff : 325|1@0+ (1,0) [0|1] ""  FLZCU
 SG_ ICC_RISD_Pixel319_OnOff : 326|1@0+ (1,0) [0|1] ""  FLZCU
 SG_ ICC_RISD_Pixel320_OnOff : 327|1@0+ (1,0) [0|1] ""  FLZCU
 SG_ ICC_RISD_Pixel321_OnOff : 328|1@0+ (1,0) [0|1] ""  FLZCU
 SG_ ICC_RISD_Pixel322_OnOff : 329|1@0+ (1,0) [0|1] ""  FLZCU
 SG_ ICC_RISD_Pixel323_OnOff : 330|1@0+ (1,0) [0|1] ""  FLZCU
 SG_ ICC_RISD_Pixel324_OnOff : 331|1@0+ (1,0) [0|1] ""  FLZCU
 SG_ ICC_RISD_Pixel325_OnOff : 332|1@0+ (1,0) [0|1] ""  FLZCU
 SG_ ICC_RISD_Pixel326_OnOff : 333|1@0+ (1,0) [0|1] ""  FLZCU
 SG_ ICC_RISD_Pixel327_OnOff : 334|1@0+ (1,0) [0|1] ""  FLZCU
 SG_ ICC_RISD_Pixel328_OnOff : 335|1@0+ (1,0) [0|1] ""  FLZCU
 SG_ ICC_RISD_Pixel329_OnOff : 336|1@0+ (1,0) [0|1] ""  FLZCU
 SG_ ICC_RISD_Pixel330_OnOff : 337|1@0+ (1,0) [0|1] ""  FLZCU
 SG_ ICC_RISD_Pixel331_OnOff : 338|1@0+ (1,0) [0|1] ""  FLZCU
 SG_ ICC_RISD_Pixel332_OnOff : 339|1@0+ (1,0) [0|1] ""  FLZCU
 SG_ ICC_RISD_Pixel333_OnOff : 340|1@0+ (1,0) [0|1] ""  FLZCU
 SG_ ICC_RISD_Pixel334_OnOff : 341|1@0+ (1,0) [0|1] ""  FLZCU
 SG_ ICC_RISD_Pixel335_OnOff : 342|1@0+ (1,0) [0|1] ""  FLZCU
 SG_ ICC_RISD_Pixel336_OnOff : 343|1@0+ (1,0) [0|1] ""  FLZCU
 SG_ ICC_RISD_Pixel337_OnOff : 344|1@0+ (1,0) [0|1] ""  FLZCU
 SG_ ICC_RISD_Pixel338_OnOff : 345|1@0+ (1,0) [0|1] ""  FLZCU
 SG_ ICC_RISD_Pixel339_OnOff : 346|1@0+ (1,0) [0|1] ""  FLZCU
 SG_ ICC_RISD_Pixel340_OnOff : 347|1@0+ (1,0) [0|1] ""  FLZCU
 SG_ ICC_RISD_Pixel341_OnOff : 348|1@0+ (1,0) [0|1] ""  FLZCU
 SG_ ICC_RISD_Pixel342_OnOff : 349|1@0+ (1,0) [0|1] ""  FLZCU
 SG_ ICC_RISD_Pixel343_OnOff : 350|1@0+ (1,0) [0|1] ""  FLZCU
 SG_ ICC_RISD_Pixel344_OnOff : 351|1@0+ (1,0) [0|1] ""  FLZCU
 SG_ ICC_RISD_Pixel345_OnOff : 352|1@0+ (1,0) [0|1] ""  FLZCU
 SG_ ICC_RISD_Pixel346_OnOff : 353|1@0+ (1,0) [0|1] ""  FLZCU
 SG_ ICC_RISD_Pixel347_OnOff : 354|1@0+ (1,0) [0|1] ""  FLZCU
 SG_ ICC_RISD_Pixel348_OnOff : 355|1@0+ (1,0) [0|1] ""  FLZCU
 SG_ ICC_RISD_Pixel349_OnOff : 356|1@0+ (1,0) [0|1] ""  FLZCU
 SG_ ICC_RISD_Pixel350_OnOff : 357|1@0+ (1,0) [0|1] ""  FLZCU
 SG_ ICC_RISD_Pixel351_OnOff : 358|1@0+ (1,0) [0|1] ""  FLZCU
 SG_ ICC_RISD_Pixel352_OnOff : 359|1@0+ (1,0) [0|1] ""  FLZCU
 SG_ ICC_RISD_Pixel353_OnOff : 360|1@0+ (1,0) [0|1] ""  FLZCU
 SG_ ICC_RISD_Pixel354_OnOff : 361|1@0+ (1,0) [0|1] ""  FLZCU
 SG_ ICC_RISD_Pixel355_OnOff : 362|1@0+ (1,0) [0|1] ""  FLZCU
 SG_ ICC_RISD_Pixel356_OnOff : 363|1@0+ (1,0) [0|1] ""  FLZCU
 SG_ ICC_RISD_Pixel357_OnOff : 364|1@0+ (1,0) [0|1] ""  FLZCU
 SG_ ICC_RISD_Pixel358_OnOff : 365|1@0+ (1,0) [0|1] ""  FLZCU
 SG_ ICC_RISD_Pixel359_OnOff : 366|1@0+ (1,0) [0|1] ""  FLZCU
 SG_ ICC_RISD_Pixel360_OnOff : 367|1@0+ (1,0) [0|1] ""  FLZCU
 SG_ ICC_RISD_Pixel361_OnOff : 368|1@0+ (1,0) [0|1] ""  FLZCU
 SG_ ICC_RISD_Pixel362_OnOff : 369|1@0+ (1,0) [0|1] ""  FLZCU
 SG_ ICC_RISD_Pixel363_OnOff : 370|1@0+ (1,0) [0|1] ""  FLZCU
 SG_ ICC_RISD_Pixel364_OnOff : 371|1@0+ (1,0) [0|1] ""  FLZCU
 SG_ ICC_RISD_Pixel365_OnOff : 372|1@0+ (1,0) [0|1] ""  FLZCU
 SG_ ICC_RISD_Pixel366_OnOff : 373|1@0+ (1,0) [0|1] ""  FLZCU
 SG_ ICC_RISD_Pixel367_OnOff : 374|1@0+ (1,0) [0|1] ""  FLZCU
 SG_ ICC_RISD_Pixel368_OnOff : 375|1@0+ (1,0) [0|1] ""  FLZCU
 SG_ ICC_RISD_Pixel369_OnOff : 376|1@0+ (1,0) [0|1] ""  FLZCU
 SG_ ICC_RISD_Pixel370_OnOff : 377|1@0+ (1,0) [0|1] ""  FLZCU
 SG_ ICC_RISD_Pixel371_OnOff : 378|1@0+ (1,0) [0|1] ""  FLZCU
 SG_ ICC_RISD_Pixel372_OnOff : 379|1@0+ (1,0) [0|1] ""  FLZCU
 SG_ ICC_RISD_Pixel373_OnOff : 380|1@0+ (1,0) [0|1] ""  FLZCU
 SG_ ICC_RISD_Pixel374_OnOff : 381|1@0+ (1,0) [0|1] ""  FLZCU
 SG_ ICC_RISD_Pixel375_OnOff : 382|1@0+ (1,0) [0|1] ""  FLZCU
 SG_ ICC_RISD_Pixel376_OnOff : 383|1@0+ (1,0) [0|1] ""  FLZCU
 SG_ ICC_RISD_Pixel377_OnOff : 384|1@0+ (1,0) [0|1] ""  FLZCU
 SG_ ICC_RISD_Pixel378_OnOff : 385|1@0+ (1,0) [0|1] ""  FLZCU
 SG_ ICC_RISD_Pixel379_OnOff : 386|1@0+ (1,0) [0|1] ""  FLZCU
 SG_ ICC_RISD_Pixel380_OnOff : 387|1@0+ (1,0) [0|1] ""  FLZCU
 SG_ ICC_RISD_Pixel381_OnOff : 388|1@0+ (1,0) [0|1] ""  FLZCU
 SG_ ICC_RISD_Pixel382_OnOff : 389|1@0+ (1,0) [0|1] ""  FLZCU
 SG_ ICC_RISD_Pixel383_OnOff : 390|1@0+ (1,0) [0|1] ""  FLZCU
 SG_ ICC_RISD_Pixel384_OnOff : 391|1@0+ (1,0) [0|1] ""  FLZCU
 SG_ ICC_RISD_Pixel385_OnOff : 392|1@0+ (1,0) [0|1] ""  FLZCU
 SG_ ICC_RISD_Pixel386_OnOff : 393|1@0+ (1,0) [0|1] ""  FLZCU
 SG_ ICC_RISD_Pixel387_OnOff : 394|1@0+ (1,0) [0|1] ""  FLZCU
 SG_ ICC_RISD_Pixel388_OnOff : 395|1@0+ (1,0) [0|1] ""  FLZCU
 SG_ ICC_RISD_Pixel389_OnOff : 396|1@0+ (1,0) [0|1] ""  FLZCU
 SG_ ICC_RISD_Pixel390_OnOff : 397|1@0+ (1,0) [0|1] ""  FLZCU
 SG_ ICC_RISD_Pixel391_OnOff : 398|1@0+ (1,0) [0|1] ""  FLZCU
 SG_ ICC_RISD_Pixel392_OnOff : 399|1@0+ (1,0) [0|1] ""  FLZCU
 SG_ ICC_RISD_Pixel393_OnOff : 400|1@0+ (1,0) [0|1] ""  FLZCU
 SG_ ICC_RISD_Pixel394_OnOff : 401|1@0+ (1,0) [0|1] ""  FLZCU
 SG_ ICC_RISD_Pixel395_OnOff : 402|1@0+ (1,0) [0|1] ""  FLZCU
 SG_ ICC_RISD_Pixel396_OnOff : 403|1@0+ (1,0) [0|1] ""  FLZCU
 SG_ ICC_RISD_Pixel397_OnOff : 404|1@0+ (1,0) [0|1] ""  FLZCU
 SG_ ICC_RISD_Pixel398_OnOff : 405|1@0+ (1,0) [0|1] ""  FLZCU
 SG_ ICC_RISD_Pixel399_OnOff : 406|1@0+ (1,0) [0|1] ""  FLZCU
 SG_ ICC_RISD_Pixel400_OnOff : 407|1@0+ (1,0) [0|1] ""  FLZCU
 SG_ ICC_RISD_Pixel401_OnOff : 408|1@0+ (1,0) [0|1] ""  FLZCU
 SG_ ICC_RISD_Pixel402_OnOff : 409|1@0+ (1,0) [0|1] ""  FLZCU
 SG_ ICC_RISD_Pixel403_OnOff : 410|1@0+ (1,0) [0|1] ""  FLZCU
 SG_ ICC_RISD_Pixel404_OnOff : 411|1@0+ (1,0) [0|1] ""  FLZCU
 SG_ ICC_RISD_Pixel405_OnOff : 412|1@0+ (1,0) [0|1] ""  FLZCU
 SG_ ICC_RISD_Pixel406_OnOff : 413|1@0+ (1,0) [0|1] ""  FLZCU
 SG_ ICC_RISD_Pixel407_OnOff : 414|1@0+ (1,0) [0|1] ""  FLZCU
 SG_ ICC_RISD_Pixel408_OnOff : 415|1@0+ (1,0) [0|1] ""  FLZCU
 SG_ ICC_RISD_Pixel409_OnOff : 416|1@0+ (1,0) [0|1] ""  FLZCU
 SG_ ICC_RISD_Pixel410_OnOff : 417|1@0+ (1,0) [0|1] ""  FLZCU
 SG_ ICC_RISD_Pixel411_OnOff : 418|1@0+ (1,0) [0|1] ""  FLZCU
 SG_ ICC_RISD_Pixel412_OnOff : 419|1@0+ (1,0) [0|1] ""  FLZCU
 SG_ ICC_RISD_Pixel413_OnOff : 420|1@0+ (1,0) [0|1] ""  FLZCU
 SG_ ICC_RISD_Pixel414_OnOff : 421|1@0+ (1,0) [0|1] ""  FLZCU
 SG_ ICC_RISD_Pixel415_OnOff : 422|1@0+ (1,0) [0|1] ""  FLZCU
 SG_ ICC_RISD_Pixel416_OnOff : 423|1@0+ (1,0) [0|1] ""  FLZCU
 SG_ ICC_RISD_Pixel417_OnOff : 424|1@0+ (1,0) [0|1] ""  FLZCU
 SG_ ICC_RISD_Pixel418_OnOff : 425|1@0+ (1,0) [0|1] ""  FLZCU
 SG_ ICC_RISD_Pixel419_OnOff : 426|1@0+ (1,0) [0|1] ""  FLZCU
 SG_ ICC_RISD_Pixel420_OnOff : 427|1@0+ (1,0) [0|1] ""  FLZCU
 SG_ ICC_RISD_Pixel421_OnOff : 428|1@0+ (1,0) [0|1] ""  FLZCU
 SG_ ICC_RISD_Pixel422_OnOff : 429|1@0+ (1,0) [0|1] ""  FLZCU
 SG_ ICC_RISD_Pixel423_OnOff : 430|1@0+ (1,0) [0|1] ""  FLZCU
 SG_ ICC_RISD_Pixel424_OnOff : 431|1@0+ (1,0) [0|1] ""  FLZCU
 SG_ ICC_RISD_Pixel425_OnOff : 432|1@0+ (1,0) [0|1] ""  FLZCU
 SG_ ICC_RISD_Pixel426_OnOff : 433|1@0+ (1,0) [0|1] ""  FLZCU
 SG_ ICC_RISD_Pixel427_OnOff : 434|1@0+ (1,0) [0|1] ""  FLZCU
 SG_ ICC_RISD_Pixel428_OnOff : 435|1@0+ (1,0) [0|1] ""  FLZCU
 SG_ ICC_RISD_Pixel429_OnOff : 436|1@0+ (1,0) [0|1] ""  FLZCU
 SG_ ICC_RISD_Pixel430_OnOff : 437|1@0+ (1,0) [0|1] ""  FLZCU
 SG_ ICC_RISD_Pixel431_OnOff : 438|1@0+ (1,0) [0|1] ""  FLZCU
 SG_ ICC_RISD_Pixel432_OnOff : 439|1@0+ (1,0) [0|1] ""  FLZCU
 SG_ ICC_RISD_Pixel433_OnOff : 440|1@0+ (1,0) [0|1] ""  FLZCU
 SG_ ICC_RISD_Pixel434_OnOff : 441|1@0+ (1,0) [0|1] ""  FLZCU
 SG_ ICC_RISD_Pixel435_OnOff : 442|1@0+ (1,0) [0|1] ""  FLZCU
 SG_ ICC_RISD_Pixel436_OnOff : 443|1@0+ (1,0) [0|1] ""  FLZCU
 SG_ ICC_RISD_Pixel437_OnOff : 444|1@0+ (1,0) [0|1] ""  FLZCU
 SG_ ICC_RISD_Pixel438_OnOff : 445|1@0+ (1,0) [0|1] ""  FLZCU
 SG_ ICC_RISD_Pixel439_OnOff : 446|1@0+ (1,0) [0|1] ""  FLZCU
 SG_ ICC_RISD_Pixel440_OnOff : 447|1@0+ (1,0) [0|1] ""  FLZCU
 SG_ ICC_RISD_Pixel441_OnOff : 448|1@0+ (1,0) [0|1] ""  FLZCU
 SG_ ICC_RISD_Pixel442_OnOff : 449|1@0+ (1,0) [0|1] ""  FLZCU
 SG_ ICC_RISD_Pixel443_OnOff : 450|1@0+ (1,0) [0|1] ""  FLZCU
 SG_ ICC_RISD_Pixel444_OnOff : 451|1@0+ (1,0) [0|1] ""  FLZCU
 SG_ ICC_RISD_Pixel445_OnOff : 452|1@0+ (1,0) [0|1] ""  FLZCU
 SG_ ICC_RISD_Pixel446_OnOff : 453|1@0+ (1,0) [0|1] ""  FLZCU
 SG_ ICC_RISD_Pixel447_OnOff : 454|1@0+ (1,0) [0|1] ""  FLZCU
 SG_ ICC_RISD_Pixel448_OnOff : 455|1@0+ (1,0) [0|1] ""  FLZCU
 SG_ ICC_RISD_Pixel449_OnOff : 456|1@0+ (1,0) [0|1] ""  FLZCU
 SG_ ICC_RISD_Pixel450_OnOff : 457|1@0+ (1,0) [0|1] ""  FLZCU
 SG_ ICC_RISD_Pixel451_OnOff : 458|1@0+ (1,0) [0|1] ""  FLZCU
 SG_ ICC_RISD_Pixel452_OnOff : 459|1@0+ (1,0) [0|1] ""  FLZCU
 SG_ ICC_RISD_Pixel453_OnOff : 460|1@0+ (1,0) [0|1] ""  FLZCU
 SG_ ICC_RISD_Pixel454_OnOff : 461|1@0+ (1,0) [0|1] ""  FLZCU
 SG_ ICC_RISD_Pixel455_OnOff : 462|1@0+ (1,0) [0|1] ""  FLZCU
 SG_ ICC_RISD_Pixel456_OnOff : 463|1@0+ (1,0) [0|1] ""  FLZCU
 SG_ ICC_RISD_Pixel457_OnOff : 464|1@0+ (1,0) [0|1] ""  FLZCU
 SG_ ICC_RISD_Pixel458_OnOff : 465|1@0+ (1,0) [0|1] ""  FLZCU
 SG_ ICC_RISD_Pixel459_OnOff : 466|1@0+ (1,0) [0|1] ""  FLZCU
 SG_ ICC_RISD_Pixel460_OnOff : 467|1@0+ (1,0) [0|1] ""  FLZCU
 SG_ ICC_RISD_Pixel461_OnOff : 468|1@0+ (1,0) [0|1] ""  FLZCU
 SG_ ICC_RISD_Pixel462_OnOff : 469|1@0+ (1,0) [0|1] ""  FLZCU
 SG_ ICC_RISD_Pixel463_OnOff : 470|1@0+ (1,0) [0|1] ""  FLZCU
 SG_ ICC_RISD_Pixel464_OnOff : 471|1@0+ (1,0) [0|1] ""  FLZCU
 SG_ ICC_RISD_Pixel465_OnOff : 472|1@0+ (1,0) [0|1] ""  FLZCU
 SG_ ICC_RISD_Pixel466_OnOff : 473|1@0+ (1,0) [0|1] ""  FLZCU
 SG_ ICC_RISD_Pixel467_OnOff : 474|1@0+ (1,0) [0|1] ""  FLZCU
 SG_ ICC_RISD_Pixel468_OnOff : 475|1@0+ (1,0) [0|1] ""  FLZCU
 SG_ ICC_RISD_Pixel469_OnOff : 476|1@0+ (1,0) [0|1] ""  FLZCU
 SG_ ICC_RISD_Pixel470_OnOff : 477|1@0+ (1,0) [0|1] ""  FLZCU
 SG_ ICC_RISD_Pixel471_OnOff : 478|1@0+ (1,0) [0|1] ""  FLZCU
 SG_ ICC_RISD_Pixel472_OnOff : 479|1@0+ (1,0) [0|1] ""  FLZCU
 SG_ ICC_RISD_Pixel473_OnOff : 480|1@0+ (1,0) [0|1] ""  FLZCU
 SG_ ICC_RISD_Pixel474_OnOff : 481|1@0+ (1,0) [0|1] ""  FLZCU
 SG_ ICC_RISD_Pixel475_OnOff : 482|1@0+ (1,0) [0|1] ""  FLZCU
 SG_ ICC_RISD_Pixel476_OnOff : 483|1@0+ (1,0) [0|1] ""  FLZCU
 SG_ ICC_RISD_Pixel477_OnOff : 484|1@0+ (1,0) [0|1] ""  FLZCU
 SG_ ICC_RISD_Pixel478_OnOff : 485|1@0+ (1,0) [0|1] ""  FLZCU
 SG_ ICC_RISD_Pixel479_OnOff : 486|1@0+ (1,0) [0|1] ""  FLZCU
 SG_ ICC_RISD_Pixel480_OnOff : 487|1@0+ (1,0) [0|1] ""  FLZCU
 SG_ ICC_RISD_Pixel481_OnOff : 488|1@0+ (1,0) [0|1] ""  FLZCU
 SG_ ICC_RISD_Pixel482_OnOff : 489|1@0+ (1,0) [0|1] ""  FLZCU
 SG_ ICC_RISD_Pixel483_OnOff : 490|1@0+ (1,0) [0|1] ""  FLZCU
 SG_ ICC_RISD_Pixel484_OnOff : 491|1@0+ (1,0) [0|1] ""  FLZCU
 SG_ ICC_RISD_Pixel485_OnOff : 492|1@0+ (1,0) [0|1] ""  FLZCU
 SG_ ICC_RISD_Pixel486_OnOff : 493|1@0+ (1,0) [0|1] ""  FLZCU
 SG_ ICC_RISD_Pixel487_OnOff : 494|1@0+ (1,0) [0|1] ""  FLZCU
 SG_ ICC_RISD_Pixel488_OnOff : 495|1@0+ (1,0) [0|1] ""  FLZCU
 SG_ ICC_RISD_Pixel489_OnOff : 496|1@0+ (1,0) [0|1] ""  FLZCU
 SG_ ICC_RISD_Pixel490_OnOff : 497|1@0+ (1,0) [0|1] ""  FLZCU
 SG_ ICC_RISD_Pixel491_OnOff : 498|1@0+ (1,0) [0|1] ""  FLZCU
 SG_ ICC_RISD_Pixel492_OnOff : 499|1@0+ (1,0) [0|1] ""  FLZCU
 SG_ ICC_RISD_Pixel493_OnOff : 500|1@0+ (1,0) [0|1] ""  FLZCU
 SG_ ICC_RISD_Pixel494_OnOff : 501|1@0+ (1,0) [0|1] ""  FLZCU
 SG_ ICC_RISD_Pixel495_OnOff : 502|1@0+ (1,0) [0|1] ""  FLZCU
 SG_ ICC_RISD_Pixel496_OnOff : 503|1@0+ (1,0) [0|1] ""  FLZCU
 SG_ ICC_RISD_Pixel497_OnOff : 504|1@0+ (1,0) [0|1] ""  FLZCU
 SG_ ICC_RISD_Pixel498_OnOff : 505|1@0+ (1,0) [0|1] ""  FLZCU
 SG_ ICC_RISD_Pixel499_OnOff : 506|1@0+ (1,0) [0|1] ""  FLZCU
 SG_ ICC_RISD_Pixel500_OnOff : 507|1@0+ (1,0) [0|1] ""  FLZCU
 SG_ ICC_RISD_Pixel501_OnOff : 508|1@0+ (1,0) [0|1] ""  FLZCU
 SG_ ICC_RISD_Pixel502_OnOff : 509|1@0+ (1,0) [0|1] ""  FLZCU
 SG_ ICC_RISD_Pixel503_OnOff : 510|1@0+ (1,0) [0|1] ""  FLZCU
 SG_ ICC_RISD_Pixel504_OnOff : 511|1@0+ (1,0) [0|1] ""  FLZCU

BO_ 1366 ICC_DA_45: 64 ICC
 SG_ ICC_LKSSettingModSt : 1|2@0+ (1,0) [0|3] ""  FLZCU
 SG_ ICC_LDWWarnType : 3|2@0+ (1,0) [0|3] ""  FLZCU
 SG_ ICC_LDWLDPSnvtySet : 5|2@0+ (1,0) [0|3] ""  FLZCU
 SG_ ICC_ELKSettingSt : 7|2@0+ (1,0) [0|3] ""  FLZCU
 SG_ ICC_ISLIWarnMod : 8|2@0+ (1,0) [0|3] ""  FLZCU
 SG_ ICC_AEBSettingSt : 10|2@0+ (1,0) [0|3] ""  FLZCU
 SG_ ICC_FCWSettingSt : 13|3@0+ (1,0) [0|7] ""  FLZCU
 SG_ ICC_ICAEnableBtnSts : 15|2@0+ (1,0) [0|3] ""  FLZCU
 SG_ ICC_Reset : 22|1@0+ (1,0) [0|1] ""  FLZCU
 SG_ ICC_ACC_SwrsSts : 24|1@0+ (1,0) [0|1] ""  FLZCU
 SG_ ICC_Customize_buttons : 27|3@0+ (1,0) [0|7] ""  FLZCU
 SG_ ICC_AVM_TouchEvt : 29|2@0+ (1,0) [0|3] ""  FLZCU
 SG_ ICC_HMAOnOffSet : 31|2@0+ (1,0) [0|3] ""  FLZCU
 SG_ ICC_AVM_BtnPressInputValueX : 39|12@0+ (1,0) [0|4095] "Pixel"  FLZCU
 SG_ ICC_AVM_BtnPressInputValueY : 43|12@0+ (1,0) [0|4095] "Pixel"  FLZCU
 SG_ ICC_OtaDwnLoad_556h : 57|2@0+ (1,0) [0|3] ""  FLZCU
 SG_ ICC_NaviBtnPressInputValX_556h : 87|16@0+ (1,0) [0|65535] ""  FLZCU
 SG_ ICC_NaviBtnPressInputValY_556h : 103|16@0+ (1,0) [0|65535] ""  FLZCU
 SG_ ICC_RRMDisplay_AVM_APA_556h : 114|3@0+ (1,0) [0|7] ""  FLZCU
 SG_ ICC_CarMdlSetColor_556h : 119|4@0+ (1,0) [0|15] ""  FLZCU
 SG_ ICC_AVMActivationSpeedSet_556h : 122|3@0+ (1,0) [0|7] ""  FLZCU
 SG_ ICC_enum_AESSettingSt_556h : 145|2@0+ (1,0) [0|3] ""  FLZCU
 SG_ ICC_enum_MAASettingSt_556h : 147|2@0+ (1,0) [0|3] ""  FLZCU
 SG_ ICC_enum_MEBSettingSt_556h : 149|2@0+ (1,0) [0|3] ""  FLZCU
 SG_ ICC_DataCollectionSwtSet_556h : 151|2@0+ (1,0) [0|3] ""  FLZCU
 SG_ ICC_ADS_DAISwtSet_556h : 153|2@0+ (1,0) [0|3] ""  FLZCU
 SG_ ICC_VoiceplayModeSwtSet_556h : 155|2@0+ (1,0) [0|3] ""  FLZCU
 SG_ ICC_NOPEnableBtnSts_556h : 157|2@0+ (1,0) [0|3] ""  FLZCU
 SG_ ICC_ParkFuncUserLearnSts_556h : 159|2@0+ (1,0) [0|3] ""  FLZCU
 SG_ TimeToStopSentinelMinutSet_556h : 293|6@0+ (1,0) [0|63] "分钟"  FLZCU
 SG_ ReservationSentinelReq_556h : 295|2@0+ (1,0) [0|3] ""  FLZCU
 SG_ TimeToStopSentinelHourSet_556h : 300|5@0+ (1,0) [0|31] "小时"  FLZCU
 SG_ SentinelMode_SensitivityReq_556h : 302|2@0+ (1,0) [0|3] ""  FLZCU
 SG_ TimeToStartSentinelHourSet_556h : 308|5@0+ (1,0) [0|31] "小时"  FLZCU
 SG_ TimeToStartSentinelDaySet_556h : 310|2@0+ (1,0) [0|3] "日"  FLZCU
 SG_ TimeToStartSentinelMinutSet_556h : 317|6@0+ (1,0) [0|63] "分钟"  FLZCU
 SG_ SentinelModeSwitchReq_556h : 319|2@0+ (1,0) [0|3] ""  FLZCU

BO_ 1380 ICC_BD_50: 32 ICC
 SG_ ICC_DrvSeatHeatLvlCmd2_564h : 19|4@0+ (1,0) [0|15] ""  FLZCU
 SG_ ICC_DrvSecSeatHeatLvlCmd2_564h : 23|4@0+ (1,0) [0|15] ""  FLZCU
 SG_ ICC_DrvSeatVentLvlCmd2_564h : 27|4@0+ (1,0) [0|15] ""  FLZCU
 SG_ ICC_DrvSecSeatVentLvlCmd2_564h : 31|4@0+ (1,0) [0|15] ""  FLZCU
 SG_ ICC_FRSeatHeatLvlCmd2 : 35|4@0+ (1,0) [0|15] ""  FLZCU
 SG_ ICC_RRSeatHeatLvlCmd2 : 39|4@0+ (1,0) [0|15] ""  FLZCU
 SG_ ICC_FRSeatVentLvlCmd2 : 43|4@0+ (1,0) [0|15] ""  FLZCU
 SG_ ICC_RRSeatVentLvlCmd2 : 47|4@0+ (1,0) [0|15] ""  FLZCU
 SG_ ICC_FRSeatliedownCmd2 : 49|2@0+ (1,0) [0|3] ""  FLZCU
 SG_ ICC_2nd_FREnjoyableSeatSwitch : 51|2@0+ (1,0) [0|3] ""  BBCM,FLZCU
 SG_ ICC_3rd_FLEnjoyableSeatSwitch : 53|2@0+ (1,0) [0|3] ""  BBCM,FLZCU
 SG_ ICC_3rd_FLFrontFlipSwitch : 55|2@0+ (1,0) [0|3] ""  BBCM,FLZCU
 SG_ ICC_3rd_FREnjoyableSeatSwitch : 57|2@0+ (1,0) [0|3] ""  BBCM,FLZCU
 SG_ ICC_3rd_FRFrontFlipSwitch : 59|2@0+ (1,0) [0|3] ""  BBCM,FLZCU
 SG_ ICC_QueenSeatSwitch : 61|2@0+ (1,0) [0|3] ""  BBCM,FLZCU
 SG_ ICC_2nd_FLSeatLvltargetCmd : 86|7@0+ (1,-1) [-1|100] "%"  BBCM,FLZCU
 SG_ ICC_2nd_FLSeatBackAgtargetCmd : 94|7@0+ (1,-1) [-1|100] "%"  BBCM,FLZCU
 SG_ ICC_2nd_FRSeatLvltargetCmd : 102|7@0+ (1,-1) [-1|100] "%"  BBCM,FLZCU
 SG_ ICC_2nd_FRSeatBackAgtargetCmd : 110|7@0+ (1,-1) [-1|100] "%"  BBCM,FLZCU
 SG_ ICC_2nd_FRSeatLegSpprttargetCmd : 118|7@0+ (1,-1) [-1|100] "%"  BBCM,FLZCU
 SG_ ICC_3rd_FLSeatBackAgtargetCmd : 150|7@0+ (1,-1) [-1|100] "%"  BBCM,FLZCU
 SG_ ICC_3rd_FRSeatBackAgtargetCmd : 158|7@0+ (1,-1) [-1|100] "%"  BBCM,FLZCU
 SG_ ICC_SetAVASFuntion_564h : 161|2@0+ (1,0) [0|3] ""  AVAS,FLZCU
 SG_ ICC_AutoSeatHeatLevelCmd_564h : 163|2@0+ (1,0) [0|3] ""  FLZCU
 SG_ ICC_AutoSteerWhlHeatCmd_564h : 165|2@0+ (1,0) [0|3] ""  FLZCU
 SG_ ICC_AutoSeatVentLevelCmd_564h : 167|2@0+ (1,0) [0|3] ""  FLZCU

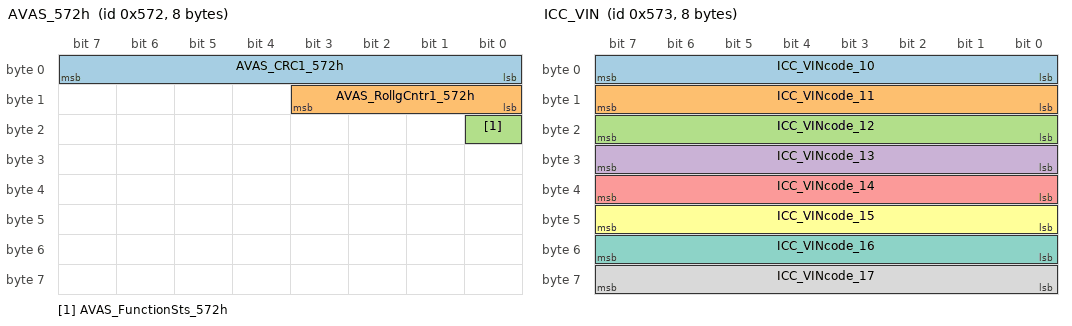
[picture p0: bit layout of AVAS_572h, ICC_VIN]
BO_ 1394 AVAS_572h: 8 AVAS
 SG_ AVAS_CRC1_572h : 7|8@0+ (1,0) [0|255] ""  ICC
 SG_ AVAS_RollgCntr1_572h : 11|4@0+ (1,0) [0|14] ""  ICC
 SG_ AVAS_FunctionSts_572h : 16|1@0+ (1,0) [0|1] ""  ICC

BO_ 1395 ICC_VIN: 8 ICC
 SG_ ICC_VINcode_10 : 7|8@0+ (1,0) [0|127] ""  FLZCU
 SG_ ICC_VINcode_11 : 15|8@0+ (1,0) [0|127] ""  FLZCU
 SG_ ICC_VINcode_12 : 23|8@0+ (1,0) [0|127] ""  FLZCU
 SG_ ICC_VINcode_13 : 31|8@0+ (1,0) [0|127] ""  FLZCU
 SG_ ICC_VINcode_14 : 39|8@0+ (1,0) [0|127] ""  FLZCU
 SG_ ICC_VINcode_15 : 47|8@0+ (1,0) [0|127] ""  FLZCU
 SG_ ICC_VINcode_16 : 55|8@0+ (1,0) [0|127] ""  FLZCU
 SG_ ICC_VINcode_17 : 63|8@0+ (1,0) [0|127] ""  FLZCU

BO_ 1399 ICC_TBOX_31: 32 ICC
 SG_ ICC_CLTC_RangeAval : 1|10@0+ (1,0) [0|1022] "KM"  FLZCU
 SG_ ICC_DynamicRangeAval : 17|10@0+ (1,0) [0|1022] "KM"  FLZCU
 SG_ ICC_WLTC_RangeAval : 33|10@0+ (1,0) [0|1022] "KM"  FLZCU
 SG_ ICC_CLTC_RangeAvalFuel : 51|12@0+ (1,0) [0|2000] "KM"  FLZCU
 SG_ ICC_WLTC_RangeAvalFuel : 67|12@0+ (1,0) [0|2000] "KM"  FLZCU
 SG_ ICC_DynamicRangeAvalFuel : 83|12@0+ (1,0) [0|2000] "KM"  FLZCU
 SG_ ICC_CLTC_RangeAvalComp : 99|12@0+ (1,0) [0|2000] "KM"  FLZCU
 SG_ ICC_WLTC_RangeAvalComp : 115|12@0+ (1,0) [0|2000] "KM"  FLZCU
 SG_ ICC_DynamicRangeAvalComp : 131|12@0+ (1,0) [0|2000] "KM"  FLZCU
 SG_ ICC_Conditiontype : 151|2@0+ (1,0) [0|3] ""  FLZCU
 SG_ SailOdoMeter_577h : 167|8@0+ (0.1,0) [0|25.5] "KM"  FLZCU
 SG_ TotalSailOdoMeterBackUp_577h : 183|16@0+ (0.1,0) [0|6553.5] "KM"  FLZCU
 SG_ ICC_SailremainingTime_577h : 223|8@0+ (1,0) [0|255] "min"  FLZCU
 SG_ MaintenanceOdometer_Valid_577h : 224|1@0+ (1,0) [0|1] ""  FLZCU
 SG_ MaintenanceOdometer_BkpEn_577h : 226|2@0+ (1,0) [0|3] ""  FLZCU
 SG_ MaintenanceOdometer_577h : 239|24@0+ (0.1,0) [0|999999.9] "KM"  FLZCU

BO_ 1403 RMCU_1_G: 8 FLZCU
 SG_ RMCU_ErrLvlDis : 19|3@0+ (1,0) [0|7] ""  ICC
 SG_ RMCU_Speed_EDR : 39|16@0+ (1,-32767) [-32767|32766] "rpm"  ICC

BO_ 1409 FLZCU_25: 8 FLZCU
 SG_ FLZCU_Totalodometerbackup : 23|24@0+ (0.1,0) [0|999999.9] "km"  ICC
 SG_ FLZCU_EVodometerbackup : 47|24@0+ (0.1,0) [0|999999.9] "km"  ICC

BO_ 1417 HCU_589h: 64 FLZCU
 SG_ HCU_RangCnsDispThisTrip_589h : 23|11@0+ (1,0) [0|2047] "km"  ICC
 SG_ HCU_ElecCnsAvgThisTrip_589h : 33|12@0+ (0.1,-100) [-100|100] "kwh/km"  ICC
 SG_ HCU_ACRangCnsThisTrip_589h : 103|11@0+ (1,-2047) [-2047|0] "km"  ICC
 SG_ HCU_AuxRangCnsThisTrip_589h : 108|11@0+ (1,-2047) [-2047|0] "km"  ICC
 SG_ HCU_RgnRangBiasThisTrip_589h : 151|11@0+ (1,-1000) [-1000|1000] "km"  ICC
 SG_ HCU_RangCnsDispAfChrg_589h : 156|11@0+ (1,0) [0|2047] "km"  ICC
 SG_ HCU_ACRangCnsAfChrg_589h : 235|11@0+ (1,-2047) [-2047|0] "km"  ICC
 SG_ HCU_AuxRangCnsAfChrg_589h : 279|11@0+ (1,-2047) [-2047|0] "km"  ICC
 SG_ HCU_RgnRangBiasAfChrg_589h : 284|11@0+ (1,-1000) [-1000|1032] "km"  ICC
 SG_ HCU_RangCnsDispAfRst_589h : 289|11@0+ (1,0) [0|2047] "km"  ICC
 SG_ HCU_ACRangCnsAfRst_589h : 363|11@0+ (1,-2047) [-2047|0] "km"  ICC
 SG_ HCU_AuxRangCnsAfRst_589h : 407|11@0+ (1,-2047) [-2047|0] "km"  ICC
 SG_ HCU_RgnRangBiasAfRst_589h : 412|11@0+ (1,-1000) [-1000|1032] "km"  ICC
 SG_ HCU_stCleverDisReason_589h : 417|4@0+ (1,0) [0|15] ""  ICC

BO_ 1419 ICC_58Bh: 32 ICC
 SG_ ICM_AverageFuelConsume_A_58Bh : 16|9@0+ (0.1,0) [0|20] "L/100Km"  FLZCU
 SG_ ICM_EngineOil_LiquidLow_58Bh : 23|2@0+ (1,0) [0|3] ""  FLZCU
 SG_ ICM_AverageFuelConsume_B_58Bh : 32|9@0+ (0.1,0) [0|20] "L/100Km"  FLZCU
 SG_ ICM_BrakeFluidSts_58Bh : 39|2@0+ (1,0) [0|3] ""  FLZCU
 SG_ ICM_AverageVehicleSpeed_A_58Bh : 48|9@0+ (1,0) [0|510] "Km/h"  FLZCU
 SG_ ICM_Maintenance_tips_58Bh : 86|15@0+ (1,0) [0|20000] "km"  FLZCU
 SG_ ICM_DrivingTime_A_58Bh : 101|14@0+ (1,0) [0|16382] "min"  FLZCU
 SG_ ICM_DrivingTime_B_58Bh : 117|14@0+ (1,0) [0|16382] "min"  FLZCU
 SG_ TotalOdometer_km_TRIPOBD_58Bh : 151|24@0+ (0.1,0) [0|999999.9] "km"  FLZCU

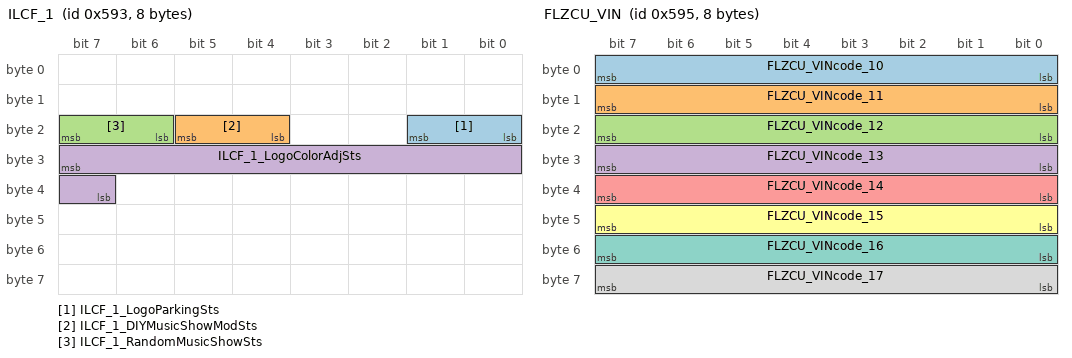
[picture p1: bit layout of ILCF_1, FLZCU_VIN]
BO_ 1427 ILCF_1: 8 FLZCU
 SG_ ILCF_1_LogoParkingSts : 17|2@0+ (1,0) [0|3] ""  ICC
 SG_ ILCF_1_DIYMusicShowModSts : 21|2@0+ (1,0) [0|3] ""  ICC
 SG_ ILCF_1_RandomMusicShowSts : 23|2@0+ (1,0) [0|3] ""  ICC
 SG_ ILCF_1_LogoColorAdjSts : 31|9@0+ (1,0) [0|511] ""  ICC

BO_ 1429 FLZCU_VIN: 8 FLZCU
 SG_ FLZCU_VINcode_10 : 7|8@0+ (1,0) [0|127] ""  ICC
 SG_ FLZCU_VINcode_11 : 15|8@0+ (1,0) [0|127] ""  ICC
 SG_ FLZCU_VINcode_12 : 23|8@0+ (1,0) [0|127] ""  ICC
 SG_ FLZCU_VINcode_13 : 31|8@0+ (1,0) [0|127] ""  ICC
 SG_ FLZCU_VINcode_14 : 39|8@0+ (1,0) [0|127] ""  ICC
 SG_ FLZCU_VINcode_15 : 47|8@0+ (1,0) [0|127] ""  ICC
 SG_ FLZCU_VINcode_16 : 55|8@0+ (1,0) [0|127] ""  ICC
 SG_ FLZCU_VINcode_17 : 63|8@0+ (1,0) [0|127] ""  ICC

BO_ 1445 HCU_5A5h: 64 FLZCU
 SG_ HCU_SumFuCnsThisTrip : 23|9@0+ (0.1,0) [0|50] "L/100km"  ICC
 SG_ HCU_SumElecCnsThisTrip : 30|12@0+ (0.1,-100) [-100|100] "kwh/100km"  ICC
 SG_ HCU_SumEgyCnsThisTrip : 34|9@0+ (0.1,0) [0|50] "L/100km"  ICC

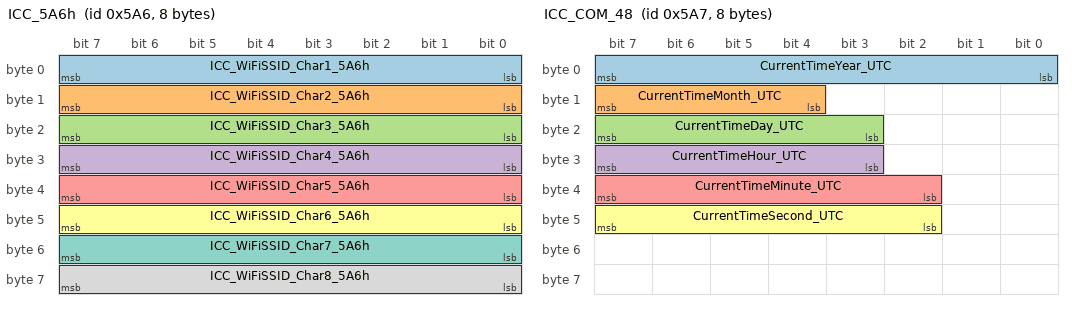
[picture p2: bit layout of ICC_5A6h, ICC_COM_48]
BO_ 1446 ICC_5A6h: 8 ICC
 SG_ ICC_WiFiSSID_Char1_5A6h : 7|8@0+ (1,0) [0|255] ""  DVR
 SG_ ICC_WiFiSSID_Char2_5A6h : 15|8@0+ (1,0) [0|255] ""  DVR
 SG_ ICC_WiFiSSID_Char3_5A6h : 23|8@0+ (1,0) [0|255] ""  DVR
 SG_ ICC_WiFiSSID_Char4_5A6h : 31|8@0+ (1,0) [0|255] ""  DVR
 SG_ ICC_WiFiSSID_Char5_5A6h : 39|8@0+ (1,0) [0|255] ""  DVR
 SG_ ICC_WiFiSSID_Char6_5A6h : 47|8@0+ (1,0) [0|255] ""  DVR
 SG_ ICC_WiFiSSID_Char7_5A6h : 55|8@0+ (1,0) [0|255] ""  DVR
 SG_ ICC_WiFiSSID_Char8_5A6h : 63|8@0+ (1,0) [0|255] ""  DVR

BO_ 1447 ICC_COM_48: 8 ICC
 SG_ CurrentTimeYear_UTC : 7|8@0+ (1,2000) [2000|2255] ""  FLZCU
 SG_ CurrentTimeMonth_UTC : 15|4@0+ (1,0) [1|12] ""  FLZCU
 SG_ CurrentTimeDay_UTC : 23|5@0+ (1,0) [1|31] ""  FLZCU
 SG_ CurrentTimeHour_UTC : 31|5@0+ (1,0) [0|23] ""  FLZCU
 SG_ CurrentTimeMinute_UTC : 39|6@0+ (1,0) [0|59] ""  FLZCU
 SG_ CurrentTimeSecond_UTC : 47|6@0+ (1,0) [0|59] ""  FLZCU

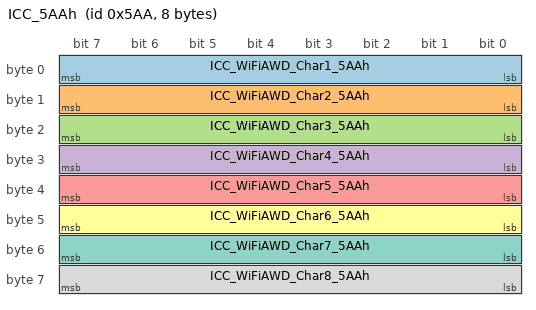
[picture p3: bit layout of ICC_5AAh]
BO_ 1450 ICC_5AAh: 8 ICC
 SG_ ICC_WiFiAWD_Char1_5AAh : 7|8@0+ (1,0) [0|255] ""  DVR
 SG_ ICC_WiFiAWD_Char2_5AAh : 15|8@0+ (1,0) [0|255] ""  DVR
 SG_ ICC_WiFiAWD_Char3_5AAh : 23|8@0+ (1,0) [0|255] ""  DVR
 SG_ ICC_WiFiAWD_Char4_5AAh : 31|8@0+ (1,0) [0|255] ""  DVR
 SG_ ICC_WiFiAWD_Char5_5AAh : 39|8@0+ (1,0) [0|255] ""  DVR
 SG_ ICC_WiFiAWD_Char6_5AAh : 47|8@0+ (1,0) [0|255] ""  DVR
 SG_ ICC_WiFiAWD_Char7_5AAh : 55|8@0+ (1,0) [0|255] ""  DVR
 SG_ ICC_WiFiAWD_Char8_5AAh : 63|8@0+ (1,0) [0|255] ""  DVR

BO_ 1451 SBOX_STATE_2: 32 SBOX
 SG_ SBOX_GNSS_ANT_State : 1|2@0+ (1,0) [0|3] ""  ICC
 SG_ SBOX_SIM_State : 3|2@0+ (1,0) [0|3] ""  ICC
 SG_ SBOX_BT_State : 5|2@0+ (1,0) [0|3] ""  ICC
 SG_ SBOX_TT_State : 7|2@0+ (1,0) [0|3] ""  ICC
 SG_ SBOX_TT_ANT_State : 9|2@0+ (1,0) [0|3] ""  ICC
 SG_ SBOX_BatterState : 11|2@0+ (1,0) [0|3] ""  ICC
 SG_ SBOX_PowerState : 13|2@0+ (1,0) [0|3] ""  ICC
 SG_ SBOX_SimActivation : 14|1@0+ (1,0) [0|1] ""  ICC
 SG_ SBOX_TspActivation : 15|1@0+ (1,0) [0|1] ""  ICC
 SG_ SBOX_SatelliteStatus : 19|4@0+ (1,0) [0|15] ""  ICC
 SG_ SBOX_BtConState : 21|2@0+ (1,0) [0|3] ""  ICC
 SG_ SBOX_SelfCheck : 23|2@0+ (1,0) [0|3] ""  ICC
 SG_ SBOX_SatelliteSignalValue : 31|8@0+ (1,0) [0|255] ""  ICC
 SG_ SBOX_BatTemp : 39|8@0+ (1,-40) [-40|100] "℃"  ICC
 SG_ SBOX_TimeSpentOnline : 47|16@0+ (1,0) [0|65535] "sec"  ICC
 SG_ SBOX_RunTime : 63|16@0+ (1,0) [0|65535] "min"  ICC
 SG_ SBOX_EcallState : 79|2@0+ (1,0) [0|3] ""  ICC

BO_ 1453 ICC_BD_49: 48 ICC
 SG_ ICC_MemAttributeFR : 20|3@0+ (1,0) [0|7] ""  FLZCU
 SG_ ICC_MemAttributeFL : 23|3@0+ (1,0) [0|7] ""  FLZCU
 SG_ ICC_MemAttributeRR : 28|3@0+ (1,0) [0|7] ""  FLZCU
 SG_ ICC_MemAttributeRL : 31|3@0+ (1,0) [0|7] ""  FLZCU
 SG_ ICC_CrossBorderMode : 33|2@0+ (1,0) [0|3] ""  FLZCU
 SG_ ICC_BedStatus : 39|3@0+ (1,0) [0|7] ""  FLZCU

BO_ 1531 BMS_9: 32 FLZCU
 SG_ BMS_HvBattSoeActDisChaCyc : 23|16@0+ (0.1,0) [0|999.9] "kWh"  ICC
 SG_ BMS_HvBattSoeActReChaCyc : 39|16@0+ (0.1,0) [0|999.9] "kWh"  ICC
 SG_ BMS_HvBattRatedEnergy : 55|14@0+ (0.1,0) [0|999.9] "KW/h"  ICC
 SG_ BMS_HvBattRatedU : 71|14@0+ (0.1,0) [0|999.9] "V"  ICC
 SG_ BMS_HvBattTypeCode : 87|8@0+ (1,0) [0|255] ""  ICC
 SG_ BMS_HvBattManufcCode : 95|32@0+ (1,0) [0|4294967295] ""  ICC
 SG_ BMS_HvBattTempSensorTotalNum : 127|16@0+ (1,0) [0|65534] ""  ICC
 SG_ BMS_HvBattTempSensorTempMaxNum : 143|8@0+ (1,0) [1|250] ""  ICC
 SG_ BMS_HvBattTempSensorTempMinNum : 151|8@0+ (1,0) [1|250] ""  ICC
 SG_ BMS_HvBattTempMaxNum : 159|8@0+ (1,0) [1|250] ""  ICC
 SG_ BMS_HvBattTempMinNum : 167|8@0+ (1,0) [1|250] ""  ICC
 SG_ BMS_BattCellTotalNum : 175|16@0+ (1,0) [0|65531] ""  ICC
 SG_ BMS_HvBattVoltMaxNum : 191|8@0+ (1,0) [1|250] ""  ICC
 SG_ BMS_HvBattVoltMinNum : 199|8@0+ (1,0) [1|250] ""  ICC
 SG_ BMS_ActualSOCMin : 207|12@0+ (0.025,0) [0|100] "%"  ICC
 SG_ BMS_ActualSOCMax : 211|12@0+ (0.025,0) [0|100] "%"  ICC

BO_ 1560 NMm_ICC: 8 ICC
 SG_ srcNodeID_ICC : 7|8@0+ (1,0) [0|255] "" Vector__XXX
 SG_ RMR_ICC : 8|1@0+ (1,0) [0|1] "" Vector__XXX
 SG_ NMm_ICC_Reserved1 : 15|7@0+ (1,0) [0|127] "" Vector__XXX
 SG_ ICC_Wakeup_Poweron : 16|1@0+ (1,0) [0|1] "" Vector__XXX
 SG_ ICC_Wakeup_NM : 17|1@0+ (1,0) [0|1] "" Vector__XXX
 SG_ ICC_Wakeup_Diag : 18|1@0+ (1,0) [0|1] "" Vector__XXX
 SG_ ICC_Wakeup_PowerComfortable : 20|1@0+ (1,0) [0|1] "" Vector__XXX
 SG_ ICC_Wakeup_HUD : 23|1@0+ (1,0) [0|1] "" Vector__XXX
 SG_ ICC_Wakeup_EAMP : 24|1@0+ (1,0) [0|1] "" Vector__XXX
 SG_ ICC_Awake_Poweron : 40|1@0+ (1,0) [0|1] "" Vector__XXX
 SG_ ICC_Awake_NM : 41|1@0+ (1,0) [0|1] "" Vector__XXX
 SG_ ICC_Awake_Diag : 42|1@0+ (1,0) [0|1] "" Vector__XXX
 SG_ ICC_Awake_PowerComfortable : 45|1@0+ (1,0) [0|1] "" Vector__XXX
 SG_ ICC_Awake_SentinelMode : 46|1@0+ (1,0) [0|1] "" Vector__XXX
 SG_ ICC_Awake_PetMode : 47|1@0+ (1,0) [0|1] "" Vector__XXX
 SG_ ICC_Awake_HUD : 48|1@0+ (1,0) [0|1] "" Vector__XXX
 SG_ ICC_Awake_EAMP : 49|1@0+ (1,0) [0|1] "" Vector__XXX
 SG_ ICC_Awake_FreezerFunction : 50|1@0+ (1,0) [0|1] "" Vector__XXX
 SG_ ICC_Awake_PowerOffDelay : 51|1@0+ (1,0) [0|1] "" Vector__XXX
 SG_ ICC_Awake_VehLockDwnLoad_618h : 52|1@0+ (1,0) [0|1] "" Vector__XXX

CM_ BO_ 1364 "新增";
CM_ SG_ 1364 ICC_RISD_RollingCounter "顺序计数器，确保图片数据按预期顺序发送、接收。";
CM_ SG_ 1364 ICC_RISD_Pixel1_OnOff "对应像素点的亮灭";
CM_ SG_ 1364 ICC_RISD_Pixel2_OnOff "对应像素点的亮灭";
CM_ SG_ 1364 ICC_RISD_Pixel3_OnOff "对应像素点的亮灭";
CM_ SG_ 1364 ICC_RISD_Pixel4_OnOff "对应像素点的亮灭";
CM_ SG_ 1364 ICC_RISD_Pixel5_OnOff "对应像素点的亮灭";
CM_ SG_ 1364 ICC_RISD_Pixel6_OnOff "对应像素点的亮灭";
CM_ SG_ 1364 ICC_RISD_Pixel7_OnOff "对应像素点的亮灭";
CM_ SG_ 1364 ICC_RISD_Pixel8_OnOff "对应像素点的亮灭";
CM_ SG_ 1364 ICC_RISD_Pixel9_OnOff "对应像素点的亮灭";
CM_ SG_ 1364 ICC_RISD_Pixel10_OnOff "对应像素点的亮灭";
CM_ SG_ 1364 ICC_RISD_Pixel11_OnOff "对应像素点的亮灭";
CM_ SG_ 1364 ICC_RISD_Pixel12_OnOff "对应像素点的亮灭";
CM_ SG_ 1364 ICC_RISD_Pixel13_OnOff "对应像素点的亮灭";
CM_ SG_ 1364 ICC_RISD_Pixel14_OnOff "对应像素点的亮灭";
CM_ SG_ 1364 ICC_RISD_Pixel15_OnOff "对应像素点的亮灭";
CM_ SG_ 1364 ICC_RISD_Pixel16_OnOff "对应像素点的亮灭";
CM_ SG_ 1364 ICC_RISD_Pixel17_OnOff "对应像素点的亮灭";
CM_ SG_ 1364 ICC_RISD_Pixel18_OnOff "对应像素点的亮灭";
CM_ SG_ 1364 ICC_RISD_Pixel19_OnOff "对应像素点的亮灭";
CM_ SG_ 1364 ICC_RISD_Pixel20_OnOff "对应像素点的亮灭";
CM_ SG_ 1364 ICC_RISD_Pixel21_OnOff "对应像素点的亮灭";
CM_ SG_ 1364 ICC_RISD_Pixel22_OnOff "对应像素点的亮灭";
CM_ SG_ 1364 ICC_RISD_Pixel23_OnOff "对应像素点的亮灭";
CM_ SG_ 1364 ICC_RISD_Pixel24_OnOff "对应像素点的亮灭";
CM_ SG_ 1364 ICC_RISD_Pixel25_OnOff "对应像素点的亮灭";
CM_ SG_ 1364 ICC_RISD_Pixel26_OnOff "对应像素点的亮灭";
CM_ SG_ 1364 ICC_RISD_Pixel27_OnOff "对应像素点的亮灭";
CM_ SG_ 1364 ICC_RISD_Pixel28_OnOff "对应像素点的亮灭";
CM_ SG_ 1364 ICC_RISD_Pixel29_OnOff "对应像素点的亮灭";
CM_ SG_ 1364 ICC_RISD_Pixel30_OnOff "对应像素点的亮灭";
CM_ SG_ 1364 ICC_RISD_Pixel31_OnOff "对应像素点的亮灭";
CM_ SG_ 1364 ICC_RISD_Pixel32_OnOff "对应像素点的亮灭";
CM_ SG_ 1364 ICC_RISD_Pixel33_OnOff "对应像素点的亮灭";
CM_ SG_ 1364 ICC_RISD_Pixel34_OnOff "对应像素点的亮灭";
CM_ SG_ 1364 ICC_RISD_Pixel35_OnOff "对应像素点的亮灭";
CM_ SG_ 1364 ICC_RISD_Pixel36_OnOff "对应像素点的亮灭";
CM_ SG_ 1364 ICC_RISD_Pixel37_OnOff "对应像素点的亮灭";
CM_ SG_ 1364 ICC_RISD_Pixel38_OnOff "对应像素点的亮灭";
CM_ SG_ 1364 ICC_RISD_Pixel39_OnOff "对应像素点的亮灭";
CM_ SG_ 1364 ICC_RISD_Pixel40_OnOff "对应像素点的亮灭";
CM_ SG_ 1364 ICC_RISD_Pixel41_OnOff "对应像素点的亮灭";
CM_ SG_ 1364 ICC_RISD_Pixel42_OnOff "对应像素点的亮灭";
CM_ SG_ 1364 ICC_RISD_Pixel43_OnOff "对应像素点的亮灭";
CM_ SG_ 1364 ICC_RISD_Pixel44_OnOff "对应像素点的亮灭";
CM_ SG_ 1364 ICC_RISD_Pixel45_OnOff "对应像素点的亮灭";
CM_ SG_ 1364 ICC_RISD_Pixel46_OnOff "对应像素点的亮灭";
CM_ SG_ 1364 ICC_RISD_Pixel47_OnOff "对应像素点的亮灭";
CM_ SG_ 1364 ICC_RISD_Pixel48_OnOff "对应像素点的亮灭";
CM_ SG_ 1364 ICC_RISD_Pixel49_OnOff "对应像素点的亮灭";
CM_ SG_ 1364 ICC_RISD_Pixel50_OnOff "对应像素点的亮灭";
CM_ SG_ 1364 ICC_RISD_Pixel51_OnOff "对应像素点的亮灭";
CM_ SG_ 1364 ICC_RISD_Pixel52_OnOff "对应像素点的亮灭";
CM_ SG_ 1364 ICC_RISD_Pixel53_OnOff "对应像素点的亮灭";
CM_ SG_ 1364 ICC_RISD_Pixel54_OnOff "对应像素点的亮灭";
CM_ SG_ 1364 ICC_RISD_Pixel55_OnOff "对应像素点的亮灭";
CM_ SG_ 1364 ICC_RISD_Pixel56_OnOff "对应像素点的亮灭";
CM_ SG_ 1364 ICC_RISD_Pixel57_OnOff "对应像素点的亮灭";
CM_ SG_ 1364 ICC_RISD_Pixel58_OnOff "对应像素点的亮灭";
CM_ SG_ 1364 ICC_RISD_Pixel59_OnOff "对应像素点的亮灭";
CM_ SG_ 1364 ICC_RISD_Pixel60_OnOff "对应像素点的亮灭";
CM_ SG_ 1364 ICC_RISD_Pixel61_OnOff "对应像素点的亮灭";
CM_ SG_ 1364 ICC_RISD_Pixel62_OnOff "对应像素点的亮灭";
CM_ SG_ 1364 ICC_RISD_Pixel63_OnOff "对应像素点的亮灭";
CM_ SG_ 1364 ICC_RISD_Pixel64_OnOff "对应像素点的亮灭";
CM_ SG_ 1364 ICC_RISD_Pixel65_OnOff "对应像素点的亮灭";
CM_ SG_ 1364 ICC_RISD_Pixel66_OnOff "对应像素点的亮灭";
CM_ SG_ 1364 ICC_RISD_Pixel67_OnOff "对应像素点的亮灭";
CM_ SG_ 1364 ICC_RISD_Pixel68_OnOff "对应像素点的亮灭";
CM_ SG_ 1364 ICC_RISD_Pixel69_OnOff "对应像素点的亮灭";
CM_ SG_ 1364 ICC_RISD_Pixel70_OnOff "对应像素点的亮灭";
CM_ SG_ 1364 ICC_RISD_Pixel71_OnOff "对应像素点的亮灭";
CM_ SG_ 1364 ICC_RISD_Pixel72_OnOff "对应像素点的亮灭";
CM_ SG_ 1364 ICC_RISD_Pixel73_OnOff "对应像素点的亮灭";
CM_ SG_ 1364 ICC_RISD_Pixel74_OnOff "对应像素点的亮灭";
CM_ SG_ 1364 ICC_RISD_Pixel75_OnOff "对应像素点的亮灭";
CM_ SG_ 1364 ICC_RISD_Pixel76_OnOff "对应像素点的亮灭";
CM_ SG_ 1364 ICC_RISD_Pixel77_OnOff "对应像素点的亮灭";
CM_ SG_ 1364 ICC_RISD_Pixel78_OnOff "对应像素点的亮灭";
CM_ SG_ 1364 ICC_RISD_Pixel79_OnOff "对应像素点的亮灭";
CM_ SG_ 1364 ICC_RISD_Pixel80_OnOff "对应像素点的亮灭";
CM_ SG_ 1364 ICC_RISD_Pixel81_OnOff "对应像素点的亮灭";
CM_ SG_ 1364 ICC_RISD_Pixel82_OnOff "对应像素点的亮灭";
CM_ SG_ 1364 ICC_RISD_Pixel83_OnOff "对应像素点的亮灭";
CM_ SG_ 1364 ICC_RISD_Pixel84_OnOff "对应像素点的亮灭";
CM_ SG_ 1364 ICC_RISD_Pixel85_OnOff "对应像素点的亮灭";
CM_ SG_ 1364 ICC_RISD_Pixel86_OnOff "对应像素点的亮灭";
CM_ SG_ 1364 ICC_RISD_Pixel87_OnOff "对应像素点的亮灭";
CM_ SG_ 1364 ICC_RISD_Pixel88_OnOff "对应像素点的亮灭";
CM_ SG_ 1364 ICC_RISD_Pixel89_OnOff "对应像素点的亮灭";
CM_ SG_ 1364 ICC_RISD_Pixel90_OnOff "对应像素点的亮灭";
CM_ SG_ 1364 ICC_RISD_Pixel91_OnOff "对应像素点的亮灭";
CM_ SG_ 1364 ICC_RISD_Pixel92_OnOff "对应像素点的亮灭";
CM_ SG_ 1364 ICC_RISD_Pixel93_OnOff "对应像素点的亮灭";
CM_ SG_ 1364 ICC_RISD_Pixel94_OnOff "对应像素点的亮灭";
CM_ SG_ 1364 ICC_RISD_Pixel95_OnOff "对应像素点的亮灭";
CM_ SG_ 1364 ICC_RISD_Pixel96_OnOff "对应像素点的亮灭";
CM_ SG_ 1364 ICC_RISD_Pixel97_OnOff "对应像素点的亮灭";
CM_ SG_ 1364 ICC_RISD_Pixel98_OnOff "对应像素点的亮灭";
CM_ SG_ 1364 ICC_RISD_Pixel99_OnOff "对应像素点的亮灭";
CM_ SG_ 1364 ICC_RISD_Pixel100_OnOff "对应像素点的亮灭";
CM_ SG_ 1364 ICC_RISD_Pixel101_OnOff "对应像素点的亮灭";
CM_ SG_ 1364 ICC_RISD_Pixel102_OnOff "对应像素点的亮灭";
CM_ SG_ 1364 ICC_RISD_Pixel103_OnOff "对应像素点的亮灭";
CM_ SG_ 1364 ICC_RISD_Pixel104_OnOff "对应像素点的亮灭";
CM_ SG_ 1364 ICC_RISD_Pixel105_OnOff "对应像素点的亮灭";
CM_ SG_ 1364 ICC_RISD_Pixel106_OnOff "对应像素点的亮灭";
CM_ SG_ 1364 ICC_RISD_Pixel107_OnOff "对应像素点的亮灭";
CM_ SG_ 1364 ICC_RISD_Pixel108_OnOff "对应像素点的亮灭";
CM_ SG_ 1364 ICC_RISD_Pixel109_OnOff "对应像素点的亮灭";
CM_ SG_ 1364 ICC_RISD_Pixel110_OnOff "对应像素点的亮灭";
CM_ SG_ 1364 ICC_RISD_Pixel111_OnOff "对应像素点的亮灭";
CM_ SG_ 1364 ICC_RISD_Pixel112_OnOff "对应像素点的亮灭";
CM_ SG_ 1364 ICC_RISD_Pixel113_OnOff "对应像素点的亮灭";
CM_ SG_ 1364 ICC_RISD_Pixel114_OnOff "对应像素点的亮灭";
CM_ SG_ 1364 ICC_RISD_Pixel115_OnOff "对应像素点的亮灭";
CM_ SG_ 1364 ICC_RISD_Pixel116_OnOff "对应像素点的亮灭";
CM_ SG_ 1364 ICC_RISD_Pixel117_OnOff "对应像素点的亮灭";
CM_ SG_ 1364 ICC_RISD_Pixel118_OnOff "对应像素点的亮灭";
CM_ SG_ 1364 ICC_RISD_Pixel119_OnOff "对应像素点的亮灭";
CM_ SG_ 1364 ICC_RISD_Pixel120_OnOff "对应像素点的亮灭";
CM_ SG_ 1364 ICC_RISD_Pixel121_OnOff "对应像素点的亮灭";
CM_ SG_ 1364 ICC_RISD_Pixel122_OnOff "对应像素点的亮灭";
CM_ SG_ 1364 ICC_RISD_Pixel123_OnOff "对应像素点的亮灭";
CM_ SG_ 1364 ICC_RISD_Pixel124_OnOff "对应像素点的亮灭";
CM_ SG_ 1364 ICC_RISD_Pixel125_OnOff "对应像素点的亮灭";
CM_ SG_ 1364 ICC_RISD_Pixel126_OnOff "对应像素点的亮灭";
CM_ SG_ 1364 ICC_RISD_Pixel127_OnOff "对应像素点的亮灭";
CM_ SG_ 1364 ICC_RISD_Pixel128_OnOff "对应像素点的亮灭";
CM_ SG_ 1364 ICC_RISD_Pixel129_OnOff "对应像素点的亮灭";
CM_ SG_ 1364 ICC_RISD_Pixel130_OnOff "对应像素点的亮灭";
CM_ SG_ 1364 ICC_RISD_Pixel131_OnOff "对应像素点的亮灭";
CM_ SG_ 1364 ICC_RISD_Pixel132_OnOff "对应像素点的亮灭";
CM_ SG_ 1364 ICC_RISD_Pixel133_OnOff "对应像素点的亮灭";
CM_ SG_ 1364 ICC_RISD_Pixel134_OnOff "对应像素点的亮灭";
CM_ SG_ 1364 ICC_RISD_Pixel135_OnOff "对应像素点的亮灭";
CM_ SG_ 1364 ICC_RISD_Pixel136_OnOff "对应像素点的亮灭";
CM_ SG_ 1364 ICC_RISD_Pixel137_OnOff "对应像素点的亮灭";
CM_ SG_ 1364 ICC_RISD_Pixel138_OnOff "对应像素点的亮灭";
CM_ SG_ 1364 ICC_RISD_Pixel139_OnOff "对应像素点的亮灭";
CM_ SG_ 1364 ICC_RISD_Pixel140_OnOff "对应像素点的亮灭";
CM_ SG_ 1364 ICC_RISD_Pixel141_OnOff "对应像素点的亮灭";
CM_ SG_ 1364 ICC_RISD_Pixel142_OnOff "对应像素点的亮灭";
CM_ SG_ 1364 ICC_RISD_Pixel143_OnOff "对应像素点的亮灭";
CM_ SG_ 1364 ICC_RISD_Pixel144_OnOff "对应像素点的亮灭";
CM_ SG_ 1364 ICC_RISD_Pixel145_OnOff "对应像素点的亮灭";
CM_ SG_ 1364 ICC_RISD_Pixel146_OnOff "对应像素点的亮灭";
CM_ SG_ 1364 ICC_RISD_Pixel147_OnOff "对应像素点的亮灭";
CM_ SG_ 1364 ICC_RISD_Pixel148_OnOff "对应像素点的亮灭";
CM_ SG_ 1364 ICC_RISD_Pixel149_OnOff "对应像素点的亮灭";
CM_ SG_ 1364 ICC_RISD_Pixel150_OnOff "对应像素点的亮灭";
CM_ SG_ 1364 ICC_RISD_Pixel151_OnOff "对应像素点的亮灭";
CM_ SG_ 1364 ICC_RISD_Pixel152_OnOff "对应像素点的亮灭";
CM_ SG_ 1364 ICC_RISD_Pixel153_OnOff "对应像素点的亮灭";
CM_ SG_ 1364 ICC_RISD_Pixel154_OnOff "对应像素点的亮灭";
CM_ SG_ 1364 ICC_RISD_Pixel155_OnOff "对应像素点的亮灭";
CM_ SG_ 1364 ICC_RISD_Pixel156_OnOff "对应像素点的亮灭";
CM_ SG_ 1364 ICC_RISD_Pixel157_OnOff "对应像素点的亮灭";
CM_ SG_ 1364 ICC_RISD_Pixel158_OnOff "对应像素点的亮灭";
CM_ SG_ 1364 ICC_RISD_Pixel159_OnOff "对应像素点的亮灭";
CM_ SG_ 1364 ICC_RISD_Pixel160_OnOff "对应像素点的亮灭";
CM_ SG_ 1364 ICC_RISD_Pixel161_OnOff "对应像素点的亮灭";
CM_ SG_ 1364 ICC_RISD_Pixel162_OnOff "对应像素点的亮灭";
CM_ SG_ 1364 ICC_RISD_Pixel163_OnOff "对应像素点的亮灭";
CM_ SG_ 1364 ICC_RISD_Pixel164_OnOff "对应像素点的亮灭";
CM_ SG_ 1364 ICC_RISD_Pixel165_OnOff "对应像素点的亮灭";
CM_ SG_ 1364 ICC_RISD_Pixel166_OnOff "对应像素点的亮灭";
CM_ SG_ 1364 ICC_RISD_Pixel167_OnOff "对应像素点的亮灭";
CM_ SG_ 1364 ICC_RISD_Pixel168_OnOff "对应像素点的亮灭";
CM_ SG_ 1364 ICC_RISD_Pixel169_OnOff "对应像素点的亮灭";
CM_ SG_ 1364 ICC_RISD_Pixel170_OnOff "对应像素点的亮灭";
CM_ SG_ 1364 ICC_RISD_Pixel171_OnOff "对应像素点的亮灭";
CM_ SG_ 1364 ICC_RISD_Pixel172_OnOff "对应像素点的亮灭";
CM_ SG_ 1364 ICC_RISD_Pixel173_OnOff "对应像素点的亮灭";
CM_ SG_ 1364 ICC_RISD_Pixel174_OnOff "对应像素点的亮灭";
CM_ SG_ 1364 ICC_RISD_Pixel175_OnOff "对应像素点的亮灭";
CM_ SG_ 1364 ICC_RISD_Pixel176_OnOff "对应像素点的亮灭";
CM_ SG_ 1364 ICC_RISD_Pixel177_OnOff "对应像素点的亮灭";
CM_ SG_ 1364 ICC_RISD_Pixel178_OnOff "对应像素点的亮灭";
CM_ SG_ 1364 ICC_RISD_Pixel179_OnOff "对应像素点的亮灭";
CM_ SG_ 1364 ICC_RISD_Pixel180_OnOff "对应像素点的亮灭";
CM_ SG_ 1364 ICC_RISD_Pixel181_OnOff "对应像素点的亮灭";
CM_ SG_ 1364 ICC_RISD_Pixel182_OnOff "对应像素点的亮灭";
CM_ SG_ 1364 ICC_RISD_Pixel183_OnOff "对应像素点的亮灭";
CM_ SG_ 1364 ICC_RISD_Pixel184_OnOff "对应像素点的亮灭";
CM_ SG_ 1364 ICC_RISD_Pixel185_OnOff "对应像素点的亮灭";
CM_ SG_ 1364 ICC_RISD_Pixel186_OnOff "对应像素点的亮灭";
CM_ SG_ 1364 ICC_RISD_Pixel187_OnOff "对应像素点的亮灭";
CM_ SG_ 1364 ICC_RISD_Pixel188_OnOff "对应像素点的亮灭";
CM_ SG_ 1364 ICC_RISD_Pixel189_OnOff "对应像素点的亮灭";
CM_ SG_ 1364 ICC_RISD_Pixel190_OnOff "对应像素点的亮灭";
CM_ SG_ 1364 ICC_RISD_Pixel191_OnOff "对应像素点的亮灭";
CM_ SG_ 1364 ICC_RISD_Pixel192_OnOff "对应像素点的亮灭";
CM_ SG_ 1364 ICC_RISD_Pixel193_OnOff "对应像素点的亮灭";
CM_ SG_ 1364 ICC_RISD_Pixel194_OnOff "对应像素点的亮灭";
CM_ SG_ 1364 ICC_RISD_Pixel195_OnOff "对应像素点的亮灭";
CM_ SG_ 1364 ICC_RISD_Pixel196_OnOff "对应像素点的亮灭";
CM_ SG_ 1364 ICC_RISD_Pixel197_OnOff "对应像素点的亮灭";
CM_ SG_ 1364 ICC_RISD_Pixel198_OnOff "对应像素点的亮灭";
CM_ SG_ 1364 ICC_RISD_Pixel199_OnOff "对应像素点的亮灭";
CM_ SG_ 1364 ICC_RISD_Pixel200_OnOff "对应像素点的亮灭";
CM_ SG_ 1364 ICC_RISD_Pixel201_OnOff "对应像素点的亮灭";
CM_ SG_ 1364 ICC_RISD_Pixel202_OnOff "对应像素点的亮灭";
CM_ SG_ 1364 ICC_RISD_Pixel203_OnOff "对应像素点的亮灭";
CM_ SG_ 1364 ICC_RISD_Pixel204_OnOff "对应像素点的亮灭";
CM_ SG_ 1364 ICC_RISD_Pixel205_OnOff "对应像素点的亮灭";
CM_ SG_ 1364 ICC_RISD_Pixel206_OnOff "对应像素点的亮灭";
CM_ SG_ 1364 ICC_RISD_Pixel207_OnOff "对应像素点的亮灭";
CM_ SG_ 1364 ICC_RISD_Pixel208_OnOff "对应像素点的亮灭";
CM_ SG_ 1364 ICC_RISD_Pixel209_OnOff "对应像素点的亮灭";
CM_ SG_ 1364 ICC_RISD_Pixel210_OnOff "对应像素点的亮灭";
CM_ SG_ 1364 ICC_RISD_Pixel211_OnOff "对应像素点的亮灭";
CM_ SG_ 1364 ICC_RISD_Pixel212_OnOff "对应像素点的亮灭";
CM_ SG_ 1364 ICC_RISD_Pixel213_OnOff "对应像素点的亮灭";
CM_ SG_ 1364 ICC_RISD_Pixel214_OnOff "对应像素点的亮灭";
CM_ SG_ 1364 ICC_RISD_Pixel215_OnOff "对应像素点的亮灭";
CM_ SG_ 1364 ICC_RISD_Pixel216_OnOff "对应像素点的亮灭";
CM_ SG_ 1364 ICC_RISD_Pixel217_OnOff "对应像素点的亮灭";
CM_ SG_ 1364 ICC_RISD_Pixel218_OnOff "对应像素点的亮灭";
CM_ SG_ 1364 ICC_RISD_Pixel219_OnOff "对应像素点的亮灭";
CM_ SG_ 1364 ICC_RISD_Pixel220_OnOff "对应像素点的亮灭";
CM_ SG_ 1364 ICC_RISD_Pixel221_OnOff "对应像素点的亮灭";
CM_ SG_ 1364 ICC_RISD_Pixel222_OnOff "对应像素点的亮灭";
CM_ SG_ 1364 ICC_RISD_Pixel223_OnOff "对应像素点的亮灭";
CM_ SG_ 1364 ICC_RISD_Pixel224_OnOff "对应像素点的亮灭";
CM_ SG_ 1364 ICC_RISD_Pixel225_OnOff "对应像素点的亮灭";
CM_ SG_ 1364 ICC_RISD_Pixel226_OnOff "对应像素点的亮灭";
CM_ SG_ 1364 ICC_RISD_Pixel227_OnOff "对应像素点的亮灭";
CM_ SG_ 1364 ICC_RISD_Pixel228_OnOff "对应像素点的亮灭";
CM_ SG_ 1364 ICC_RISD_Pixel229_OnOff "对应像素点的亮灭";
CM_ SG_ 1364 ICC_RISD_Pixel230_OnOff "对应像素点的亮灭";
CM_ SG_ 1364 ICC_RISD_Pixel231_OnOff "对应像素点的亮灭";
CM_ SG_ 1364 ICC_RISD_Pixel232_OnOff "对应像素点的亮灭";
CM_ SG_ 1364 ICC_RISD_Pixel233_OnOff "对应像素点的亮灭";
CM_ SG_ 1364 ICC_RISD_Pixel234_OnOff "对应像素点的亮灭";
CM_ SG_ 1364 ICC_RISD_Pixel235_OnOff "对应像素点的亮灭";
CM_ SG_ 1364 ICC_RISD_Pixel236_OnOff "对应像素点的亮灭";
CM_ SG_ 1364 ICC_RISD_Pixel237_OnOff "对应像素点的亮灭";
CM_ SG_ 1364 ICC_RISD_Pixel238_OnOff "对应像素点的亮灭";
CM_ SG_ 1364 ICC_RISD_Pixel239_OnOff "对应像素点的亮灭";
CM_ SG_ 1364 ICC_RISD_Pixel240_OnOff "对应像素点的亮灭";
CM_ SG_ 1364 ICC_RISD_Pixel241_OnOff "对应像素点的亮灭";
CM_ SG_ 1364 ICC_RISD_Pixel242_OnOff "对应像素点的亮灭";
CM_ SG_ 1364 ICC_RISD_Pixel243_OnOff "对应像素点的亮灭";
CM_ SG_ 1364 ICC_RISD_Pixel244_OnOff "对应像素点的亮灭";
CM_ SG_ 1364 ICC_RISD_Pixel245_OnOff "对应像素点的亮灭";
CM_ SG_ 1364 ICC_RISD_Pixel246_OnOff "对应像素点的亮灭";
CM_ SG_ 1364 ICC_RISD_Pixel247_OnOff "对应像素点的亮灭";
CM_ SG_ 1364 ICC_RISD_Pixel248_OnOff "对应像素点的亮灭";
CM_ SG_ 1364 ICC_RISD_Pixel249_OnOff "对应像素点的亮灭";
CM_ SG_ 1364 ICC_RISD_Pixel250_OnOff "对应像素点的亮灭";
CM_ SG_ 1364 ICC_RISD_Pixel251_OnOff "对应像素点的亮灭";
CM_ SG_ 1364 ICC_RISD_Pixel252_OnOff "对应像素点的亮灭";
CM_ SG_ 1364 ICC_RISD_Pixel253_OnOff "对应像素点的亮灭";
CM_ SG_ 1364 ICC_RISD_Pixel254_OnOff "对应像素点的亮灭";
CM_ SG_ 1364 ICC_RISD_Pixel255_OnOff "对应像素点的亮灭";
CM_ SG_ 1364 ICC_RISD_Pixel256_OnOff "对应像素点的亮灭";
CM_ SG_ 1364 ICC_RISD_Pixel257_OnOff "对应像素点的亮灭";
CM_ SG_ 1364 ICC_RISD_Pixel258_OnOff "对应像素点的亮灭";
CM_ SG_ 1364 ICC_RISD_Pixel259_OnOff "对应像素点的亮灭";
CM_ SG_ 1364 ICC_RISD_Pixel260_OnOff "对应像素点的亮灭";
CM_ SG_ 1364 ICC_RISD_Pixel261_OnOff "对应像素点的亮灭";
CM_ SG_ 1364 ICC_RISD_Pixel262_OnOff "对应像素点的亮灭";
CM_ SG_ 1364 ICC_RISD_Pixel263_OnOff "对应像素点的亮灭";
CM_ SG_ 1364 ICC_RISD_Pixel264_OnOff "对应像素点的亮灭";
CM_ SG_ 1364 ICC_RISD_Pixel265_OnOff "对应像素点的亮灭";
CM_ SG_ 1364 ICC_RISD_Pixel266_OnOff "对应像素点的亮灭";
CM_ SG_ 1364 ICC_RISD_Pixel267_OnOff "对应像素点的亮灭";
CM_ SG_ 1364 ICC_RISD_Pixel268_OnOff "对应像素点的亮灭";
CM_ SG_ 1364 ICC_RISD_Pixel269_OnOff "对应像素点的亮灭";
CM_ SG_ 1364 ICC_RISD_Pixel270_OnOff "对应像素点的亮灭";
CM_ SG_ 1364 ICC_RISD_Pixel271_OnOff "对应像素点的亮灭";
CM_ SG_ 1364 ICC_RISD_Pixel272_OnOff "对应像素点的亮灭";
CM_ SG_ 1364 ICC_RISD_Pixel273_OnOff "对应像素点的亮灭";
CM_ SG_ 1364 ICC_RISD_Pixel274_OnOff "对应像素点的亮灭";
CM_ SG_ 1364 ICC_RISD_Pixel275_OnOff "对应像素点的亮灭";
CM_ SG_ 1364 ICC_RISD_Pixel276_OnOff "对应像素点的亮灭";
CM_ SG_ 1364 ICC_RISD_Pixel277_OnOff "对应像素点的亮灭";
CM_ SG_ 1364 ICC_RISD_Pixel278_OnOff "对应像素点的亮灭";
CM_ SG_ 1364 ICC_RISD_Pixel279_OnOff "对应像素点的亮灭";
CM_ SG_ 1364 ICC_RISD_Pixel280_OnOff "对应像素点的亮灭";
CM_ SG_ 1364 ICC_RISD_Pixel281_OnOff "对应像素点的亮灭";
CM_ SG_ 1364 ICC_RISD_Pixel282_OnOff "对应像素点的亮灭";
CM_ SG_ 1364 ICC_RISD_Pixel283_OnOff "对应像素点的亮灭";
CM_ SG_ 1364 ICC_RISD_Pixel284_OnOff "对应像素点的亮灭";
CM_ SG_ 1364 ICC_RISD_Pixel285_OnOff "对应像素点的亮灭";
CM_ SG_ 1364 ICC_RISD_Pixel286_OnOff "对应像素点的亮灭";
CM_ SG_ 1364 ICC_RISD_Pixel287_OnOff "对应像素点的亮灭";
CM_ SG_ 1364 ICC_RISD_Pixel288_OnOff "对应像素点的亮灭";
CM_ SG_ 1364 ICC_RISD_Pixel289_OnOff "对应像素点的亮灭";
CM_ SG_ 1364 ICC_RISD_Pixel290_OnOff "对应像素点的亮灭";
CM_ SG_ 1364 ICC_RISD_Pixel291_OnOff "对应像素点的亮灭";
CM_ SG_ 1364 ICC_RISD_Pixel292_OnOff "对应像素点的亮灭";
CM_ SG_ 1364 ICC_RISD_Pixel293_OnOff "对应像素点的亮灭";
CM_ SG_ 1364 ICC_RISD_Pixel294_OnOff "对应像素点的亮灭";
CM_ SG_ 1364 ICC_RISD_Pixel295_OnOff "对应像素点的亮灭";
CM_ SG_ 1364 ICC_RISD_Pixel296_OnOff "对应像素点的亮灭";
CM_ SG_ 1364 ICC_RISD_Pixel297_OnOff "对应像素点的亮灭";
CM_ SG_ 1364 ICC_RISD_Pixel298_OnOff "对应像素点的亮灭";
CM_ SG_ 1364 ICC_RISD_Pixel299_OnOff "对应像素点的亮灭";
CM_ SG_ 1364 ICC_RISD_Pixel300_OnOff "对应像素点的亮灭";
CM_ SG_ 1364 ICC_RISD_Pixel301_OnOff "对应像素点的亮灭";
CM_ SG_ 1364 ICC_RISD_Pixel302_OnOff "对应像素点的亮灭";
CM_ SG_ 1364 ICC_RISD_Pixel303_OnOff "对应像素点的亮灭";
CM_ SG_ 1364 ICC_RISD_Pixel304_OnOff "对应像素点的亮灭";
CM_ SG_ 1364 ICC_RISD_Pixel305_OnOff "对应像素点的亮灭";
CM_ SG_ 1364 ICC_RISD_Pixel306_OnOff "对应像素点的亮灭";
CM_ SG_ 1364 ICC_RISD_Pixel307_OnOff "对应像素点的亮灭";
CM_ SG_ 1364 ICC_RISD_Pixel308_OnOff "对应像素点的亮灭";
CM_ SG_ 1364 ICC_RISD_Pixel309_OnOff "对应像素点的亮灭";
CM_ SG_ 1364 ICC_RISD_Pixel310_OnOff "对应像素点的亮灭";
CM_ SG_ 1364 ICC_RISD_Pixel311_OnOff "对应像素点的亮灭";
CM_ SG_ 1364 ICC_RISD_Pixel312_OnOff "对应像素点的亮灭";
CM_ SG_ 1364 ICC_RISD_Pixel313_OnOff "对应像素点的亮灭";
CM_ SG_ 1364 ICC_RISD_Pixel314_OnOff "对应像素点的亮灭";
CM_ SG_ 1364 ICC_RISD_Pixel315_OnOff "对应像素点的亮灭";
CM_ SG_ 1364 ICC_RISD_Pixel316_OnOff "对应像素点的亮灭";
CM_ SG_ 1364 ICC_RISD_Pixel317_OnOff "对应像素点的亮灭";
CM_ SG_ 1364 ICC_RISD_Pixel318_OnOff "对应像素点的亮灭";
CM_ SG_ 1364 ICC_RISD_Pixel319_OnOff "对应像素点的亮灭";
CM_ SG_ 1364 ICC_RISD_Pixel320_OnOff "对应像素点的亮灭";
CM_ SG_ 1364 ICC_RISD_Pixel321_OnOff "对应像素点的亮灭";
CM_ SG_ 1364 ICC_RISD_Pixel322_OnOff "对应像素点的亮灭";
CM_ SG_ 1364 ICC_RISD_Pixel323_OnOff "对应像素点的亮灭";
CM_ SG_ 1364 ICC_RISD_Pixel324_OnOff "对应像素点的亮灭";
CM_ SG_ 1364 ICC_RISD_Pixel325_OnOff "对应像素点的亮灭";
CM_ SG_ 1364 ICC_RISD_Pixel326_OnOff "对应像素点的亮灭";
CM_ SG_ 1364 ICC_RISD_Pixel327_OnOff "对应像素点的亮灭";
CM_ SG_ 1364 ICC_RISD_Pixel328_OnOff "对应像素点的亮灭";
CM_ SG_ 1364 ICC_RISD_Pixel329_OnOff "对应像素点的亮灭";
CM_ SG_ 1364 ICC_RISD_Pixel330_OnOff "对应像素点的亮灭";
CM_ SG_ 1364 ICC_RISD_Pixel331_OnOff "对应像素点的亮灭";
CM_ SG_ 1364 ICC_RISD_Pixel332_OnOff "对应像素点的亮灭";
CM_ SG_ 1364 ICC_RISD_Pixel333_OnOff "对应像素点的亮灭";
CM_ SG_ 1364 ICC_RISD_Pixel334_OnOff "对应像素点的亮灭";
CM_ SG_ 1364 ICC_RISD_Pixel335_OnOff "对应像素点的亮灭";
CM_ SG_ 1364 ICC_RISD_Pixel336_OnOff "对应像素点的亮灭";
CM_ SG_ 1364 ICC_RISD_Pixel337_OnOff "对应像素点的亮灭";
CM_ SG_ 1364 ICC_RISD_Pixel338_OnOff "对应像素点的亮灭";
CM_ SG_ 1364 ICC_RISD_Pixel339_OnOff "对应像素点的亮灭";
CM_ SG_ 1364 ICC_RISD_Pixel340_OnOff "对应像素点的亮灭";
CM_ SG_ 1364 ICC_RISD_Pixel341_OnOff "对应像素点的亮灭";
CM_ SG_ 1364 ICC_RISD_Pixel342_OnOff "对应像素点的亮灭";
CM_ SG_ 1364 ICC_RISD_Pixel343_OnOff "对应像素点的亮灭";
CM_ SG_ 1364 ICC_RISD_Pixel344_OnOff "对应像素点的亮灭";
CM_ SG_ 1364 ICC_RISD_Pixel345_OnOff "对应像素点的亮灭";
CM_ SG_ 1364 ICC_RISD_Pixel346_OnOff "对应像素点的亮灭";
CM_ SG_ 1364 ICC_RISD_Pixel347_OnOff "对应像素点的亮灭";
CM_ SG_ 1364 ICC_RISD_Pixel348_OnOff "对应像素点的亮灭";
CM_ SG_ 1364 ICC_RISD_Pixel349_OnOff "对应像素点的亮灭";
CM_ SG_ 1364 ICC_RISD_Pixel350_OnOff "对应像素点的亮灭";
CM_ SG_ 1364 ICC_RISD_Pixel351_OnOff "对应像素点的亮灭";
CM_ SG_ 1364 ICC_RISD_Pixel352_OnOff "对应像素点的亮灭";
CM_ SG_ 1364 ICC_RISD_Pixel353_OnOff "对应像素点的亮灭";
CM_ SG_ 1364 ICC_RISD_Pixel354_OnOff "对应像素点的亮灭";
CM_ SG_ 1364 ICC_RISD_Pixel355_OnOff "对应像素点的亮灭";
CM_ SG_ 1364 ICC_RISD_Pixel356_OnOff "对应像素点的亮灭";
CM_ SG_ 1364 ICC_RISD_Pixel357_OnOff "对应像素点的亮灭";
CM_ SG_ 1364 ICC_RISD_Pixel358_OnOff "对应像素点的亮灭";
CM_ SG_ 1364 ICC_RISD_Pixel359_OnOff "对应像素点的亮灭";
CM_ SG_ 1364 ICC_RISD_Pixel360_OnOff "对应像素点的亮灭";
CM_ SG_ 1364 ICC_RISD_Pixel361_OnOff "对应像素点的亮灭";
CM_ SG_ 1364 ICC_RISD_Pixel362_OnOff "对应像素点的亮灭";
CM_ SG_ 1364 ICC_RISD_Pixel363_OnOff "对应像素点的亮灭";
CM_ SG_ 1364 ICC_RISD_Pixel364_OnOff "对应像素点的亮灭";
CM_ SG_ 1364 ICC_RISD_Pixel365_OnOff "对应像素点的亮灭";
CM_ SG_ 1364 ICC_RISD_Pixel366_OnOff "对应像素点的亮灭";
CM_ SG_ 1364 ICC_RISD_Pixel367_OnOff "对应像素点的亮灭";
CM_ SG_ 1364 ICC_RISD_Pixel368_OnOff "对应像素点的亮灭";
CM_ SG_ 1364 ICC_RISD_Pixel369_OnOff "对应像素点的亮灭";
CM_ SG_ 1364 ICC_RISD_Pixel370_OnOff "对应像素点的亮灭";
CM_ SG_ 1364 ICC_RISD_Pixel371_OnOff "对应像素点的亮灭";
CM_ SG_ 1364 ICC_RISD_Pixel372_OnOff "对应像素点的亮灭";
CM_ SG_ 1364 ICC_RISD_Pixel373_OnOff "对应像素点的亮灭";
CM_ SG_ 1364 ICC_RISD_Pixel374_OnOff "对应像素点的亮灭";
CM_ SG_ 1364 ICC_RISD_Pixel375_OnOff "对应像素点的亮灭";
CM_ SG_ 1364 ICC_RISD_Pixel376_OnOff "对应像素点的亮灭";
CM_ SG_ 1364 ICC_RISD_Pixel377_OnOff "对应像素点的亮灭";
CM_ SG_ 1364 ICC_RISD_Pixel378_OnOff "对应像素点的亮灭";
CM_ SG_ 1364 ICC_RISD_Pixel379_OnOff "对应像素点的亮灭";
CM_ SG_ 1364 ICC_RISD_Pixel380_OnOff "对应像素点的亮灭";
CM_ SG_ 1364 ICC_RISD_Pixel381_OnOff "对应像素点的亮灭";
CM_ SG_ 1364 ICC_RISD_Pixel382_OnOff "对应像素点的亮灭";
CM_ SG_ 1364 ICC_RISD_Pixel383_OnOff "对应像素点的亮灭";
CM_ SG_ 1364 ICC_RISD_Pixel384_OnOff "对应像素点的亮灭";
CM_ SG_ 1364 ICC_RISD_Pixel385_OnOff "对应像素点的亮灭";
CM_ SG_ 1364 ICC_RISD_Pixel386_OnOff "对应像素点的亮灭";
CM_ SG_ 1364 ICC_RISD_Pixel387_OnOff "对应像素点的亮灭";
CM_ SG_ 1364 ICC_RISD_Pixel388_OnOff "对应像素点的亮灭";
CM_ SG_ 1364 ICC_RISD_Pixel389_OnOff "对应像素点的亮灭";
CM_ SG_ 1364 ICC_RISD_Pixel390_OnOff "对应像素点的亮灭";
CM_ SG_ 1364 ICC_RISD_Pixel391_OnOff "对应像素点的亮灭";
CM_ SG_ 1364 ICC_RISD_Pixel392_OnOff "对应像素点的亮灭";
CM_ SG_ 1364 ICC_RISD_Pixel393_OnOff "对应像素点的亮灭";
CM_ SG_ 1364 ICC_RISD_Pixel394_OnOff "对应像素点的亮灭";
CM_ SG_ 1364 ICC_RISD_Pixel395_OnOff "对应像素点的亮灭";
CM_ SG_ 1364 ICC_RISD_Pixel396_OnOff "对应像素点的亮灭";
CM_ SG_ 1364 ICC_RISD_Pixel397_OnOff "对应像素点的亮灭";
CM_ SG_ 1364 ICC_RISD_Pixel398_OnOff "对应像素点的亮灭";
CM_ SG_ 1364 ICC_RISD_Pixel399_OnOff "对应像素点的亮灭";
CM_ SG_ 1364 ICC_RISD_Pixel400_OnOff "对应像素点的亮灭";
CM_ SG_ 1364 ICC_RISD_Pixel401_OnOff "对应像素点的亮灭";
CM_ SG_ 1364 ICC_RISD_Pixel402_OnOff "对应像素点的亮灭";
CM_ SG_ 1364 ICC_RISD_Pixel403_OnOff "对应像素点的亮灭";
CM_ SG_ 1364 ICC_RISD_Pixel404_OnOff "对应像素点的亮灭";
CM_ SG_ 1364 ICC_RISD_Pixel405_OnOff "对应像素点的亮灭";
CM_ SG_ 1364 ICC_RISD_Pixel406_OnOff "对应像素点的亮灭";
CM_ SG_ 1364 ICC_RISD_Pixel407_OnOff "对应像素点的亮灭";
CM_ SG_ 1364 ICC_RISD_Pixel408_OnOff "对应像素点的亮灭";
CM_ SG_ 1364 ICC_RISD_Pixel409_OnOff "对应像素点的亮灭";
CM_ SG_ 1364 ICC_RISD_Pixel410_OnOff "对应像素点的亮灭";
CM_ SG_ 1364 ICC_RISD_Pixel411_OnOff "对应像素点的亮灭";
CM_ SG_ 1364 ICC_RISD_Pixel412_OnOff "对应像素点的亮灭";
CM_ SG_ 1364 ICC_RISD_Pixel413_OnOff "对应像素点的亮灭";
CM_ SG_ 1364 ICC_RISD_Pixel414_OnOff "对应像素点的亮灭";
CM_ SG_ 1364 ICC_RISD_Pixel415_OnOff "对应像素点的亮灭";
CM_ SG_ 1364 ICC_RISD_Pixel416_OnOff "对应像素点的亮灭";
CM_ SG_ 1364 ICC_RISD_Pixel417_OnOff "对应像素点的亮灭";
CM_ SG_ 1364 ICC_RISD_Pixel418_OnOff "对应像素点的亮灭";
CM_ SG_ 1364 ICC_RISD_Pixel419_OnOff "对应像素点的亮灭";
CM_ SG_ 1364 ICC_RISD_Pixel420_OnOff "对应像素点的亮灭";
CM_ SG_ 1364 ICC_RISD_Pixel421_OnOff "对应像素点的亮灭";
CM_ SG_ 1364 ICC_RISD_Pixel422_OnOff "对应像素点的亮灭";
CM_ SG_ 1364 ICC_RISD_Pixel423_OnOff "对应像素点的亮灭";
CM_ SG_ 1364 ICC_RISD_Pixel424_OnOff "对应像素点的亮灭";
CM_ SG_ 1364 ICC_RISD_Pixel425_OnOff "对应像素点的亮灭";
CM_ SG_ 1364 ICC_RISD_Pixel426_OnOff "对应像素点的亮灭";
CM_ SG_ 1364 ICC_RISD_Pixel427_OnOff "对应像素点的亮灭";
CM_ SG_ 1364 ICC_RISD_Pixel428_OnOff "对应像素点的亮灭";
CM_ SG_ 1364 ICC_RISD_Pixel429_OnOff "对应像素点的亮灭";
CM_ SG_ 1364 ICC_RISD_Pixel430_OnOff "对应像素点的亮灭";
CM_ SG_ 1364 ICC_RISD_Pixel431_OnOff "对应像素点的亮灭";
CM_ SG_ 1364 ICC_RISD_Pixel432_OnOff "对应像素点的亮灭";
CM_ SG_ 1364 ICC_RISD_Pixel433_OnOff "对应像素点的亮灭";
CM_ SG_ 1364 ICC_RISD_Pixel434_OnOff "对应像素点的亮灭";
CM_ SG_ 1364 ICC_RISD_Pixel435_OnOff "对应像素点的亮灭";
CM_ SG_ 1364 ICC_RISD_Pixel436_OnOff "对应像素点的亮灭";
CM_ SG_ 1364 ICC_RISD_Pixel437_OnOff "对应像素点的亮灭";
CM_ SG_ 1364 ICC_RISD_Pixel438_OnOff "对应像素点的亮灭";
CM_ SG_ 1364 ICC_RISD_Pixel439_OnOff "对应像素点的亮灭";
CM_ SG_ 1364 ICC_RISD_Pixel440_OnOff "对应像素点的亮灭";
CM_ SG_ 1364 ICC_RISD_Pixel441_OnOff "对应像素点的亮灭";
CM_ SG_ 1364 ICC_RISD_Pixel442_OnOff "对应像素点的亮灭";
CM_ SG_ 1364 ICC_RISD_Pixel443_OnOff "对应像素点的亮灭";
CM_ SG_ 1364 ICC_RISD_Pixel444_OnOff "对应像素点的亮灭";
CM_ SG_ 1364 ICC_RISD_Pixel445_OnOff "对应像素点的亮灭";
CM_ SG_ 1364 ICC_RISD_Pixel446_OnOff "对应像素点的亮灭";
CM_ SG_ 1364 ICC_RISD_Pixel447_OnOff "对应像素点的亮灭";
CM_ SG_ 1364 ICC_RISD_Pixel448_OnOff "对应像素点的亮灭";
CM_ SG_ 1364 ICC_RISD_Pixel449_OnOff "对应像素点的亮灭";
CM_ SG_ 1364 ICC_RISD_Pixel450_OnOff "对应像素点的亮灭";
CM_ SG_ 1364 ICC_RISD_Pixel451_OnOff "对应像素点的亮灭";
CM_ SG_ 1364 ICC_RISD_Pixel452_OnOff "对应像素点的亮灭";
CM_ SG_ 1364 ICC_RISD_Pixel453_OnOff "对应像素点的亮灭";
CM_ SG_ 1364 ICC_RISD_Pixel454_OnOff "对应像素点的亮灭";
CM_ SG_ 1364 ICC_RISD_Pixel455_OnOff "对应像素点的亮灭";
CM_ SG_ 1364 ICC_RISD_Pixel456_OnOff "对应像素点的亮灭";
CM_ SG_ 1364 ICC_RISD_Pixel457_OnOff "对应像素点的亮灭";
CM_ SG_ 1364 ICC_RISD_Pixel458_OnOff "对应像素点的亮灭";
CM_ SG_ 1364 ICC_RISD_Pixel459_OnOff "对应像素点的亮灭";
CM_ SG_ 1364 ICC_RISD_Pixel460_OnOff "对应像素点的亮灭";
CM_ SG_ 1364 ICC_RISD_Pixel461_OnOff "对应像素点的亮灭";
CM_ SG_ 1364 ICC_RISD_Pixel462_OnOff "对应像素点的亮灭";
CM_ SG_ 1364 ICC_RISD_Pixel463_OnOff "对应像素点的亮灭";
CM_ SG_ 1364 ICC_RISD_Pixel464_OnOff "对应像素点的亮灭";
CM_ SG_ 1364 ICC_RISD_Pixel465_OnOff "对应像素点的亮灭";
CM_ SG_ 1364 ICC_RISD_Pixel466_OnOff "对应像素点的亮灭";
CM_ SG_ 1364 ICC_RISD_Pixel467_OnOff "对应像素点的亮灭";
CM_ SG_ 1364 ICC_RISD_Pixel468_OnOff "对应像素点的亮灭";
CM_ SG_ 1364 ICC_RISD_Pixel469_OnOff "对应像素点的亮灭";
CM_ SG_ 1364 ICC_RISD_Pixel470_OnOff "对应像素点的亮灭";
CM_ SG_ 1364 ICC_RISD_Pixel471_OnOff "对应像素点的亮灭";
CM_ SG_ 1364 ICC_RISD_Pixel472_OnOff "对应像素点的亮灭";
CM_ SG_ 1364 ICC_RISD_Pixel473_OnOff "对应像素点的亮灭";
CM_ SG_ 1364 ICC_RISD_Pixel474_OnOff "对应像素点的亮灭";
CM_ SG_ 1364 ICC_RISD_Pixel475_OnOff "对应像素点的亮灭";
CM_ SG_ 1364 ICC_RISD_Pixel476_OnOff "对应像素点的亮灭";
CM_ SG_ 1364 ICC_RISD_Pixel477_OnOff "对应像素点的亮灭";
CM_ SG_ 1364 ICC_RISD_Pixel478_OnOff "对应像素点的亮灭";
CM_ SG_ 1364 ICC_RISD_Pixel479_OnOff "对应像素点的亮灭";
CM_ SG_ 1364 ICC_RISD_Pixel480_OnOff "对应像素点的亮灭";
CM_ SG_ 1364 ICC_RISD_Pixel481_OnOff "对应像素点的亮灭";
CM_ SG_ 1364 ICC_RISD_Pixel482_OnOff "对应像素点的亮灭";
CM_ SG_ 1364 ICC_RISD_Pixel483_OnOff "对应像素点的亮灭";
CM_ SG_ 1364 ICC_RISD_Pixel484_OnOff "对应像素点的亮灭";
CM_ SG_ 1364 ICC_RISD_Pixel485_OnOff "对应像素点的亮灭";
CM_ SG_ 1364 ICC_RISD_Pixel486_OnOff "对应像素点的亮灭";
CM_ SG_ 1364 ICC_RISD_Pixel487_OnOff "对应像素点的亮灭";
CM_ SG_ 1364 ICC_RISD_Pixel488_OnOff "对应像素点的亮灭";
CM_ SG_ 1364 ICC_RISD_Pixel489_OnOff "对应像素点的亮灭";
CM_ SG_ 1364 ICC_RISD_Pixel490_OnOff "对应像素点的亮灭";
CM_ SG_ 1364 ICC_RISD_Pixel491_OnOff "对应像素点的亮灭";
CM_ SG_ 1364 ICC_RISD_Pixel492_OnOff "对应像素点的亮灭";
CM_ SG_ 1364 ICC_RISD_Pixel493_OnOff "对应像素点的亮灭";
CM_ SG_ 1364 ICC_RISD_Pixel494_OnOff "对应像素点的亮灭";
CM_ SG_ 1364 ICC_RISD_Pixel495_OnOff "对应像素点的亮灭";
CM_ SG_ 1364 ICC_RISD_Pixel496_OnOff "对应像素点的亮灭";
CM_ SG_ 1364 ICC_RISD_Pixel497_OnOff "对应像素点的亮灭";
CM_ SG_ 1364 ICC_RISD_Pixel498_OnOff "对应像素点的亮灭";
CM_ SG_ 1364 ICC_RISD_Pixel499_OnOff "对应像素点的亮灭";
CM_ SG_ 1364 ICC_RISD_Pixel500_OnOff "对应像素点的亮灭";
CM_ SG_ 1364 ICC_RISD_Pixel501_OnOff "对应像素点的亮灭";
CM_ SG_ 1364 ICC_RISD_Pixel502_OnOff "对应像素点的亮灭";
CM_ SG_ 1364 ICC_RISD_Pixel503_OnOff "对应像素点的亮灭";
CM_ SG_ 1364 ICC_RISD_Pixel504_OnOff "对应像素点的亮灭";
CM_ BO_ 1366 "触发一次发送三帧有效+三帧 Not Active";
CM_ SG_ 1366 ICC_LKSSettingModSt "车道辅助模式";
CM_ SG_ 1366 ICC_LDWWarnType "LDW/LDP报警方式";
CM_ SG_ 1366 ICC_LDWLDPSnvtySet "车道偏离敏感度";
CM_ SG_ 1366 ICC_ELKSettingSt "ELK功能设置状态";
CM_ SG_ 1366 ICC_ISLIWarnMod "智能限速提醒方式";
CM_ SG_ 1366 ICC_AEBSettingSt "AEB功能设置状态";
CM_ SG_ 1366 ICC_FCWSettingSt "FCW功能设置状态";
CM_ SG_ 1366 ICC_ICAEnableBtnSts "ICA功能使能开关（车道居中辅助";
CM_ SG_ 1366 ICC_Reset "整车恢复出厂设置";
CM_ SG_ 1366 ICC_ACC_SwrsSts "仪表是否进入编辑态";
CM_ SG_ 1366 ICC_Customize_buttons "自定义按键大屏设置设置项
0x4:记忆泊车";
CM_ SG_ 1366 ICC_AVM_TouchEvt "触碰事件";
CM_ SG_ 1366 ICC_HMAOnOffSet "智能大灯辅助(HMA)功能开启/关闭状态信号";
CM_ SG_ 1366 ICC_AVM_BtnPressInputValueX "触碰坐标X";
CM_ SG_ 1366 ICC_AVM_BtnPressInputValueY "触碰坐标Y";
CM_ SG_ 1366 ICC_NaviBtnPressInputValX_556h "触屏X轴坐标";
CM_ SG_ 1366 ICC_NaviBtnPressInputValY_556h "触屏Y轴坐标";
CM_ SG_ 1366 ICC_RRMDisplay_AVM_APA_556h "IHU请求AVM，APA画面开，关";
CM_ SG_ 1366 ICC_CarMdlSetColor_556h "车模颜色设置";
CM_ SG_ 1366 ICC_AVMActivationSpeedSet_556h "全景影像车速开关（APA）";
CM_ SG_ 1366 ICC_enum_AESSettingSt_556h "aes开关，车机发送";
CM_ SG_ 1366 ICC_enum_MAASettingSt_556h "amap开关，车机发送";
CM_ SG_ 1366 ICC_enum_MEBSettingSt_556h "meb开关，车机发送";
CM_ SG_ 1366 ICC_DataCollectionSwtSet_556h "数据采集授权开启与关闭";
CM_ SG_ 1366 ICC_ADS_DAISwtSet_556h "驶离提醒软开关";
CM_ SG_ 1366 ICC_VoiceplayModeSwtSet_556h "辅助驾驶语音播报开关请求";
CM_ SG_ 1366 ICC_NOPEnableBtnSts_556h "智能领航辅助软开关状态";
CM_ SG_ 1366 ICC_ParkFuncUserLearnSts_556h "泊车功能用户学习状态";
CM_ SG_ 1366 TimeToStopSentinelMinutSet_556h "哨兵模式预约结束时间设置（分钟）";
CM_ SG_ 1366 ReservationSentinelReq_556h "哨兵模式预约请求
0x1:预约
0x2:取消预约";
CM_ SG_ 1366 TimeToStopSentinelHourSet_556h "哨兵模式预约结束时间设置(小时)";
CM_ SG_ 1366 SentinelMode_SensitivityReq_556h "哨兵模式灵敏度请求";
CM_ SG_ 1366 TimeToStartSentinelHourSet_556h "哨兵模式预约开始时间设置(小时)";
CM_ SG_ 1366 TimeToStartSentinelDaySet_556h "哨兵模式预约开始时间设置(日)";
CM_ SG_ 1366 TimeToStartSentinelMinutSet_556h "哨兵模式预约开始时间设置(分钟)";
CM_ SG_ 1366 SentinelModeSwitchReq_556h "哨兵模式开关请求
0x1:开
0x2:关";
CM_ BO_ 1380 "捷途V1.3新增";
CM_ SG_ 1380 ICC_DrvSeatHeatLvlCmd2_564h "一排主驾座椅加热信号-捷途使用";
CM_ SG_ 1380 ICC_DrvSecSeatHeatLvlCmd2_564h "二排主驾侧座椅加热-捷途使用";
CM_ SG_ 1380 ICC_DrvSeatVentLvlCmd2_564h "主驾座椅通风-捷途使用";
CM_ SG_ 1380 ICC_DrvSecSeatVentLvlCmd2_564h "二排副驾侧座椅通风-捷途使用";
CM_ SG_ 1380 ICC_FRSeatHeatLvlCmd2 "一排副驾座椅加热信号-捷途使用";
CM_ SG_ 1380 ICC_RRSeatHeatLvlCmd2 "二排右座椅加热-捷途使用";
CM_ SG_ 1380 ICC_FRSeatVentLvlCmd2 "副驾座椅通风-捷途使用";
CM_ SG_ 1380 ICC_RRSeatVentLvlCmd2 "二排右座椅通风-捷途使用";
CM_ SG_ 1380 ICC_FRSeatliedownCmd2 "副驾座椅一键展开/回位请求";
CM_ SG_ 1380 ICC_2nd_FREnjoyableSeatSwitch "二排右座椅一键展开和回位
0x1:展开
0x2:回位
0x3:暂停（预留）";
CM_ SG_ 1380 ICC_3rd_FLEnjoyableSeatSwitch "三排左座椅靠背一键展开和折叠
0x1:展开
0x2:折叠
0x3:暂停（预留）";
CM_ SG_ 1380 ICC_3rd_FLFrontFlipSwitch "三排左座椅一键前翻和回位
0x1:前翻
0x2:回位
0x3:暂停（预留）";
CM_ SG_ 1380 ICC_3rd_FREnjoyableSeatSwitch "三排右座椅靠背一键展开和折叠
0x1:展开
0x2:折叠
0x3:暂停（预留）";
CM_ SG_ 1380 ICC_3rd_FRFrontFlipSwitch "三排右座椅一键前翻和回位
0x1:前翻
0x2:回位
0x3:暂停（预留）";
CM_ SG_ 1380 ICC_QueenSeatSwitch "女王副驾开启
0x1:展开
0x2:回位
0x3:暂停（预留）";
CM_ SG_ 1380 ICC_2nd_FLSeatLvltargetCmd "二排左座椅水平调节目标
0x0:Not active";
CM_ SG_ 1380 ICC_2nd_FLSeatBackAgtargetCmd "二排左座椅靠背角度调节目标
0x0:Not active";
CM_ SG_ 1380 ICC_2nd_FRSeatLvltargetCmd "二排右座椅水平调节目标
0x0:Not active";
CM_ SG_ 1380 ICC_2nd_FRSeatBackAgtargetCmd "二排右座椅靠背角度调节目标
0x0:Not active";
CM_ SG_ 1380 ICC_2nd_FRSeatLegSpprttargetCmd "二排右座椅腿托调节
0x0:Not active";
CM_ SG_ 1380 ICC_3rd_FLSeatBackAgtargetCmd "三排左驾座椅靠背角度调节目标
0x0:Not active";
CM_ SG_ 1380 ICC_3rd_FRSeatBackAgtargetCmd "三排右驾座椅靠背角度调节目标
0x0:Not active";
CM_ SG_ 1380 ICC_SetAVASFuntion_564h "AVAS开关信号
";
CM_ SG_ 1380 ICC_AutoSeatHeatLevelCmd_564h "座椅自动加热请求";
CM_ SG_ 1380 ICC_AutoSteerWhlHeatCmd_564h "方向盘自动加热请求";
CM_ SG_ 1380 ICC_AutoSeatVentLevelCmd_564h "座椅自动通风请求";
CM_ SG_ 1394 AVAS_CRC1_572h "'Profile1A:E2E CRC (SAE J1850 CRC-8) for 8 Bytes
DataID:No ASIL requirements.Not configure
CRC Reserved.'";
CM_ SG_ 1394 AVAS_RollgCntr1_572h "Profile1A:E2E Rolling message counter(the maximum value of Alive counter is 14)";
CM_ SG_ 1394 AVAS_FunctionSts_572h "反馈AVAS状态";
CM_ SG_ 1399 ICC_CLTC_RangeAval "CLTC工况里程(电)";
CM_ SG_ 1399 ICC_DynamicRangeAval "动态工况里程(电)";
CM_ SG_ 1399 ICC_WLTC_RangeAval "WLTC工况里程(电)";
CM_ SG_ 1399 ICC_CLTC_RangeAvalFuel "CLTC工况里程(燃油)";
CM_ SG_ 1399 ICC_WLTC_RangeAvalFuel "WLTC工况里程(燃油)";
CM_ SG_ 1399 ICC_DynamicRangeAvalFuel "动态工况里程(燃油)";
CM_ SG_ 1399 ICC_CLTC_RangeAvalComp "CLTC工况里程(综合)";
CM_ SG_ 1399 ICC_WLTC_RangeAvalComp "WLTC工况里程(综合)";
CM_ SG_ 1399 ICC_DynamicRangeAvalComp "动态工况里程(综合)";
CM_ SG_ 1399 ICC_Conditiontype "工况类型";
CM_ SG_ 1399 SailOdoMeter_577h "单次航行里程";
CM_ SG_ 1399 TotalSailOdoMeterBackUp_577h "累计航行里程（备份）";
CM_ SG_ 1399 ICC_SailremainingTime_577h "剩余航行时间";
CM_ SG_ 1399 MaintenanceOdometer_BkpEn_577h "保养累计里程备份使能";
CM_ SG_ 1399 MaintenanceOdometer_577h "保养累计里程
0xFFFFFF:Invalid";
CM_ SG_ 1403 RMCU_ErrLvlDis "后驱动电机控制器故障等级";
CM_ SG_ 1403 RMCU_Speed_EDR "后驱动电机实际转速";
CM_ SG_ 1409 FLZCU_Totalodometerbackup "总里程备份信号";
CM_ SG_ 1409 FLZCU_EVodometerbackup "EV里程备份信号";
CM_ SG_ 1417 HCU_RangCnsDispThisTrip_589h "本次行程消耗续航";
CM_ SG_ 1417 HCU_ElecCnsAvgThisTrip_589h "本次行程平均电耗";
CM_ SG_ 1417 HCU_ACRangCnsThisTrip_589h "本次行程空调导致里程衰减";
CM_ SG_ 1417 HCU_AuxRangCnsThisTrip_589h "本次行程电器额外消耗导致里程衰减";
CM_ SG_ 1417 HCU_RgnRangBiasThisTrip_589h "本次行程里程偏差（上下坡、环境温度、驾驶风格等）";
CM_ SG_ 1417 HCU_RangCnsDispAfChrg_589h "自充电后消耗续航";
CM_ SG_ 1417 HCU_ACRangCnsAfChrg_589h "自充电后空调导致里程衰减";
CM_ SG_ 1417 HCU_AuxRangCnsAfChrg_589h "自充电后电器额外消耗导致里程衰减";
CM_ SG_ 1417 HCU_RgnRangBiasAfChrg_589h "自充电后里程偏差（上下坡、环境温度、驾驶风格等）";
CM_ SG_ 1417 HCU_RangCnsDispAfRst_589h "自小计里程重置后消耗续航";
CM_ SG_ 1417 HCU_ACRangCnsAfRst_589h "自小计里程重置后空调导致里程衰减";
CM_ SG_ 1417 HCU_AuxRangCnsAfRst_589h "自小计里程重置后电器额外消耗导致里程衰减";
CM_ SG_ 1417 HCU_RgnRangBiasAfRst_589h "自小计里程重置后里程偏差（上下坡、环境温度、驾驶风格等）";
CM_ SG_ 1417 HCU_stCleverDisReason_589h "智慧能量管理切换失败原因
0x0:No_Command
0x1:请退出越野驾驶模式
0x2:请退出cco模式
0x3:请退出ads模式
0x4:请退出节能模式
0x5:请退出晕车舒缓模式
0x6:请关闭智慧驾驶风格后重试
0x7:智慧驾驶风路已开启，驾驶模式不可调整，如需调整请关闭置灰驾驶风格。（用于用户通过旋钮调整驾驶模式）
0x8:请退出智慧能量回收模式";
CM_ SG_ 1419 ICM_AverageFuelConsume_A_58Bh "平均油耗A_单次行程平均油耗";
CM_ SG_ 1419 ICM_EngineOil_LiquidLow_58Bh "燃油车机油液位低";
CM_ SG_ 1419 ICM_AverageFuelConsume_B_58Bh "平均油耗A_单次行程平均油耗";
CM_ SG_ 1419 ICM_BrakeFluidSts_58Bh "燃油车制动液位低仪表外发";
CM_ SG_ 1419 ICM_AverageVehicleSpeed_A_58Bh "平均车速A外发_单次行程平均车速";
CM_ SG_ 1419 ICM_Maintenance_tips_58Bh "剩余保养里程外发";
CM_ SG_ 1419 ICM_DrivingTime_A_58Bh "驾驶时间A外发_单次行程驾驶时间
";
CM_ SG_ 1419 ICM_DrivingTime_B_58Bh "驾驶时间B外发_单次行程驾驶时间
";
CM_ SG_ 1419 TotalOdometer_km_TRIPOBD_58Bh "自启动后累计里程";
CM_ SG_ 1427 ILCF_1_LogoParkingSts "前LOGO驻车点亮开关状态反馈";
CM_ SG_ 1427 ILCF_1_DIYMusicShowModSts "固定灯光秀状态反馈信号";
CM_ SG_ 1427 ILCF_1_RandomMusicShowSts "随机灯光秀状态反馈信号";
CM_ SG_ 1427 ILCF_1_LogoColorAdjSts "Logo灯颜色设置反馈，1-256分别对应256种颜色";
CM_ BO_ 1429 "域控直发";
CM_ SG_ 1445 HCU_SumFuCnsThisTrip "自启动后百公里油耗显示(仅仪表使用)";
CM_ SG_ 1445 HCU_SumElecCnsThisTrip "自启动后百公里电耗显示(仅仪表使用)";
CM_ SG_ 1445 HCU_SumEgyCnsThisTrip "自启动后百公里能耗L/100km";
CM_ SG_ 1446 ICC_WiFiSSID_Char1_5A6h "第一位WiFi名称后缀信息（采用ASCII编码格式）";
CM_ SG_ 1446 ICC_WiFiSSID_Char2_5A6h "第二位WiFi名称后缀信息（采用ASCII编码格式）";
CM_ SG_ 1446 ICC_WiFiSSID_Char3_5A6h "第三位WiFi名称后缀信息（采用ASCII编码格式）";
CM_ SG_ 1446 ICC_WiFiSSID_Char4_5A6h "第四位WiFi名称后缀信息（采用ASCII编码格式）";
CM_ SG_ 1446 ICC_WiFiSSID_Char5_5A6h "第五位WiFi名称后缀信息（采用ASCII编码格式）";
CM_ SG_ 1446 ICC_WiFiSSID_Char6_5A6h "第六位WiFi名称后缀信息（采用ASCII编码格式）";
CM_ SG_ 1446 ICC_WiFiSSID_Char7_5A6h "第七位WiFi名称后缀信息（采用ASCII编码格式）";
CM_ SG_ 1446 ICC_WiFiSSID_Char8_5A6h "第八位WiFi名称后缀信息（采用ASCII编码格式）";
CM_ BO_ 1447 "同步股份埋点时间戳新增";
CM_ SG_ 1447 CurrentTimeYear_UTC "时间（年）";
CM_ SG_ 1447 CurrentTimeMonth_UTC "时间（月）";
CM_ SG_ 1447 CurrentTimeDay_UTC "时间（日）";
CM_ SG_ 1447 CurrentTimeHour_UTC "时间（时）";
CM_ SG_ 1447 CurrentTimeMinute_UTC "时间（分）";
CM_ SG_ 1447 CurrentTimeSecond_UTC "时间（秒）";
CM_ SG_ 1450 ICC_WiFiAWD_Char1_5AAh "第一位WiFi名称后缀信息（采用ASCII编码格式）
";
CM_ SG_ 1450 ICC_WiFiAWD_Char2_5AAh "第二位WiFi名称后缀信息（采用ASCII编码格式）
";
CM_ SG_ 1450 ICC_WiFiAWD_Char3_5AAh "第三位WiFi名称后缀信息（采用ASCII编码格式）
";
CM_ SG_ 1450 ICC_WiFiAWD_Char4_5AAh "第四位WiFi名称后缀信息（采用ASCII编码格式）
";
CM_ SG_ 1450 ICC_WiFiAWD_Char5_5AAh "第五位WiFi名称后缀信息（采用ASCII编码格式）
";
CM_ SG_ 1450 ICC_WiFiAWD_Char6_5AAh "第六位WiFi名称后缀信息（采用ASCII编码格式）
";
CM_ SG_ 1450 ICC_WiFiAWD_Char7_5AAh "第七位WiFi名称后缀信息（采用ASCII编码格式）
";
CM_ SG_ 1450 ICC_WiFiAWD_Char8_5AAh "第八位WiFi名称后缀信息（采用ASCII编码格式）
";
CM_ BO_ 1451 "捷途ID新增";
CM_ SG_ 1451 SBOX_GNSS_ANT_State "GNSS天线状态";
CM_ SG_ 1451 SBOX_SIM_State "SIM卡状态";
CM_ SG_ 1451 SBOX_BT_State "蓝牙模组状态";
CM_ SG_ 1451 SBOX_TT_State "卫星模组状态";
CM_ SG_ 1451 SBOX_TT_ANT_State "卫星天线状态";
CM_ SG_ 1451 SBOX_BatterState "小电池状态";
CM_ SG_ 1451 SBOX_PowerState "主电状态";
CM_ SG_ 1451 SBOX_SimActivation "sim激活状态";
CM_ SG_ 1451 SBOX_TspActivation "TSP激活状态（OK才可发MSD短信）";
CM_ SG_ 1451 SBOX_SatelliteStatus "卫星网络状态";
CM_ SG_ 1451 SBOX_BtConState "蓝牙连接状态";
CM_ SG_ 1451 SBOX_SelfCheck "SBOX状态
（检测条件：上电注册网络作为功能是否正常）";
CM_ SG_ 1451 SBOX_SatelliteSignalValue "卫星信号强度";
CM_ SG_ 1451 SBOX_BatTemp "SBOX小电池温度";
CM_ SG_ 1451 SBOX_TimeSpentOnline "本次注网时长";
CM_ SG_ 1451 SBOX_RunTime "SBOX总运行时间";
CM_ SG_ 1451 SBOX_EcallState "ECALL状态";
CM_ BO_ 1453 "捷途V1.3新增";
CM_ SG_ 1453 ICC_MemAttributeFR "CoDriverSeatMemberAttribute
副驾驶位成员属性";
CM_ SG_ 1453 ICC_MemAttributeFL "DriverSeatMemberAttribute
驾驶位成员属性";
CM_ SG_ 1453 ICC_MemAttributeRR "SecondRowRightSeatMemberAttribute
二排右成员属性";
CM_ SG_ 1453 ICC_MemAttributeRL "SecondRowLeftSeatMemberAttribute
二排左成员属性";
CM_ SG_ 1453 ICC_CrossBorderMode "HCU 反馈飞车模式执行情况
0x1: On 表示飞车模式限制已开启
0x2: Off 表示飞车模式限制未开启";
CM_ SG_ 1453 ICC_BedStatus "大床模式开关请求
0x1:居家大床
0x2:副驾单人床
0x3:驻车沙发
0x4:旅行小床
0x5:暂停";
CM_ SG_ 1531 BMS_HvBattSoeActDisChaCyc "一个驾驶循环内放电能量累计";
CM_ SG_ 1531 BMS_HvBattSoeActReChaCyc "一个驾驶循环内回充能量累计";
CM_ SG_ 1531 BMS_HvBattRatedEnergy "电池额定能量";
CM_ SG_ 1531 BMS_HvBattRatedU "电池额定电压";
CM_ SG_ 1531 BMS_HvBattTypeCode "发送动力电池类型";
CM_ SG_ 1531 BMS_HvBattManufcCode "供应商代码";
CM_ SG_ 1531 BMS_HvBattTempSensorTotalNum "电池模组温度传感器总个数";
CM_ SG_ 1531 BMS_HvBattTempSensorTempMaxNum "最高温度NTC所在的编号";
CM_ SG_ 1531 BMS_HvBattTempSensorTempMinNum "最低温度NTC所在的编号";
CM_ SG_ 1531 BMS_HvBattTempMaxNum "最高温度模组编号";
CM_ SG_ 1531 BMS_HvBattTempMinNum "最低温度模组编码编号";
CM_ SG_ 1531 BMS_BattCellTotalNum "电池电芯总个数";
CM_ SG_ 1531 BMS_HvBattVoltMaxNum "最高单体电压模组编号";
CM_ SG_ 1531 BMS_HvBattVoltMinNum "最低单体电压所在模组编号";
CM_ SG_ 1531 BMS_ActualSOCMin "映射显示SOC值";
CM_ SG_ 1531 BMS_ActualSOCMax "映射显示SOC值";
CM_ SG_ 1560 srcNodeID_ICC "The srcNodeID of IHU is 0x18";
CM_ SG_ 1560 RMR_ICC "If set to 1 to force the network management of all other nodes on the bus into the re-peat message state.";
CM_ SG_ 1560 ICC_Wakeup_Poweron "整车电源档位为on档（KL15硬线）";
CM_ SG_ 1560 ICC_Wakeup_NM "NM报文";
CM_ SG_ 1560 ICC_Wakeup_Diag "Wakeup Source3 Reserved";
CM_ SG_ 1560 ICC_Wakeup_PowerComfortable "整车电源档位为Comfortable档（KL15硬线）";
CM_ SG_ 1560 ICC_Wakeup_HUD "HUD唤醒（0x63E）股份信号，捷途预留";
CM_ SG_ 1560 ICC_Wakeup_EAMP "EAMP唤醒（0x62A）股份信号，捷途预留";
CM_ SG_ 1560 ICC_Awake_Poweron "整车电源档位为on档（KL15硬线）";
CM_ SG_ 1560 ICC_Awake_NM "Awake Reason2 Reserved";
CM_ SG_ 1560 ICC_Awake_Diag "接收到本部件相关的以太诊断报文";
CM_ SG_ 1560 ICC_Awake_PowerComfortable "整车电源档位为Comfortable档（KL15硬线）";
CM_ SG_ 1560 ICC_Awake_SentinelMode "哨兵模式激活（股份信号，捷途预留）";
CM_ SG_ 1560 ICC_Awake_PetMode "宠物模式";
CM_ SG_ 1560 ICC_Awake_HUD "HUD维持网络（超时2.5s)股份信号，捷途预留";
CM_ SG_ 1560 ICC_Awake_EAMP "EAMP维持网络（超时2.5s)股份信号，捷途预留";
CM_ SG_ 1560 ICC_Awake_FreezerFunction "冰箱功能激活（股份信号，捷途预留）";
CM_ SG_ 1560 ICC_Awake_PowerOffDelay "退电延迟功能激活";
CM_ SG_ 1560 ICC_Awake_VehLockDwnLoad_618h "OTA下载软件";
BA_DEF_ SG_  "GenSigASIL" ENUM  "QM","A","B","C","D","vector_leerstring";
BA_DEF_ SG_  "ASIL" ENUM  "QM","A","B","C","D";
BA_DEF_ SG_  "E2EDataLength" INT 0 65535;
BA_DEF_ SG_  "GenSigInactiveValue" HEX 0 80000000;
BA_DEF_ SG_  "GenSigInvalidValue" HEX 0 281474976710655;
BA_DEF_ SG_  "GenSigStartValue" HEX 0 80000000;
BA_DEF_ SG_  "GenSigSendType" ENUM  "Cyclic","OnWrite","OnWriteWithRepetition","OnChange","OnChangeWithRepetition","IfActive","IfActiveWithRepetition","NoSigSendType";
BA_DEF_ BO_  "CANFD_BRS" ENUM  "0","1";
BA_DEF_ BO_  "DiagUudtResponse" ENUM  "True","False";
BA_DEF_ BO_  "GenMsgCycleTime" INT 0 65535;
BA_DEF_ BO_  "GenMsgCycleTimeFast" INT 0 65535;
BA_DEF_ BO_  "GenMsgDelayTime" INT 0 65535;
BA_DEF_ BO_  "GenMsgILSupport" ENUM  "No","Yes";
BA_DEF_ BO_  "GenMsgNrOfRepetition" INT 0 255;
BA_DEF_ BO_  "GenMsgSendType" ENUM  "Cyclic","Event","IfActive","CE","CA","NoMsgSendType";
BA_DEF_ BO_  "NmAsrMessage" ENUM  "No","Yes";
BA_DEF_ BO_  "NmMessage" ENUM  "No","Yes";
BA_DEF_ BO_  "SCP_AuthInfoTxLength" INT 9 512;
BA_DEF_ BO_  "SCP_FreshnessValueLength" INT 0 512;
BA_DEF_ BO_  "SCP_FreshnessValueTxLength" INT 0 512;
BA_DEF_ BO_  "VFrameFormat" ENUM  "StandardCAN","ExtendedCAN","reserved","J1939PG","reserved","reserved","reserved","reserved","reserved","reserved","reserved","reserved","reserved","reserved","StandardCAN_FD","ExtendedCAN_FD";
BA_DEF_DEF_  "GenSigASIL" "QM";
BA_DEF_DEF_  "ASIL" "QM";
BA_DEF_DEF_  "E2EDataLength" 64;
BA_DEF_DEF_  "GenSigInactiveValue" 0;
BA_DEF_DEF_  "GenSigInvalidValue" 0;
BA_DEF_DEF_  "GenSigStartValue" 0;
BA_DEF_DEF_  "GenSigSendType" "NoSigSendType";
BA_DEF_DEF_  "CANFD_BRS" "1";
BA_DEF_DEF_  "DiagUudtResponse" "True";
BA_DEF_DEF_  "GenMsgCycleTime" 0;
BA_DEF_DEF_  "GenMsgCycleTimeFast" 0;
BA_DEF_DEF_  "GenMsgDelayTime" 0;
BA_DEF_DEF_  "GenMsgILSupport" "Yes";
BA_DEF_DEF_  "GenMsgNrOfRepetition" 0;
BA_DEF_DEF_  "GenMsgSendType" "Cyclic";
BA_DEF_DEF_  "NmAsrMessage" "No";
BA_DEF_DEF_  "NmMessage" "No";
BA_DEF_DEF_  "SCP_AuthInfoTxLength" 28;
BA_DEF_DEF_  "SCP_FreshnessValueLength" 48;
BA_DEF_DEF_  "SCP_FreshnessValueTxLength" 4;
BA_DEF_DEF_  "VFrameFormat" "J1939PG";
BA_ "GenMsgNrOfRepetition" BO_ 1364 2;
BA_ "GenMsgDelayTime" BO_ 1364 5;
BA_ "GenMsgCycleTimeFast" BO_ 1364 100;
BA_ "GenMsgSendType" BO_ 1364 1;
BA_ "VFrameFormat" BO_ 1364 14;
BA_ "GenMsgNrOfRepetition" BO_ 1366 2;
BA_ "GenMsgCycleTime" BO_ 1366 100;
BA_ "GenMsgDelayTime" BO_ 1366 5;
BA_ "GenMsgCycleTimeFast" BO_ 1366 20;
BA_ "VFrameFormat" BO_ 1366 14;
BA_ "GenMsgNrOfRepetition" BO_ 1380 2;
BA_ "GenMsgDelayTime" BO_ 1380 5;
BA_ "GenMsgCycleTimeFast" BO_ 1380 100;
BA_ "GenMsgSendType" BO_ 1380 1;
BA_ "VFrameFormat" BO_ 1380 14;
BA_ "GenMsgCycleTime" BO_ 1394 500;
BA_ "VFrameFormat" BO_ 1394 14;
BA_ "GenMsgCycleTime" BO_ 1395 1000;
BA_ "VFrameFormat" BO_ 1395 14;
BA_ "GenMsgCycleTime" BO_ 1399 1000;
BA_ "VFrameFormat" BO_ 1399 14;
BA_ "GenMsgCycleTime" BO_ 1403 500;
BA_ "VFrameFormat" BO_ 1403 14;
BA_ "GenMsgCycleTime" BO_ 1409 500;
BA_ "VFrameFormat" BO_ 1409 14;
BA_ "GenMsgCycleTime" BO_ 1417 1000;
BA_ "VFrameFormat" BO_ 1417 14;
BA_ "GenMsgCycleTime" BO_ 1419 1000;
BA_ "VFrameFormat" BO_ 1419 14;
BA_ "GenMsgCycleTime" BO_ 1427 100;
BA_ "VFrameFormat" BO_ 1427 14;
BA_ "GenMsgCycleTime" BO_ 1429 1000;
BA_ "VFrameFormat" BO_ 1429 14;
BA_ "GenMsgCycleTime" BO_ 1445 1000;
BA_ "VFrameFormat" BO_ 1445 14;
BA_ "GenMsgCycleTime" BO_ 1446 1000;
BA_ "VFrameFormat" BO_ 1446 14;
BA_ "GenMsgCycleTime" BO_ 1447 500;
BA_ "VFrameFormat" BO_ 1447 14;
BA_ "GenMsgCycleTime" BO_ 1450 1000;
BA_ "VFrameFormat" BO_ 1450 14;
BA_ "GenMsgCycleTime" BO_ 1451 1000;
BA_ "VFrameFormat" BO_ 1451 14;
BA_ "GenMsgCycleTime" BO_ 1453 500;
BA_ "VFrameFormat" BO_ 1453 14;
BA_ "GenMsgCycleTime" BO_ 1531 1000;
BA_ "VFrameFormat" BO_ 1531 14;
BA_ "GenMsgCycleTime" BO_ 1560 1000;
BA_ "NmAsrMessage" BO_ 1560 1;
BA_ "VFrameFormat" BO_ 1560 0;
BA_ "NmMessage" BO_ 1560 1;
BA_ "GenSigSendType" SG_ 1364 ICC_RISD_FrameCounter 2;
BA_ "GenSigSendType" SG_ 1364 ICC_RISD_RollingCounter 2;
BA_ "GenSigSendType" SG_ 1364 ICC_RISD_Pixel1_OnOff 2;
BA_ "GenSigSendType" SG_ 1364 ICC_RISD_Pixel2_OnOff 2;
BA_ "GenSigSendType" SG_ 1364 ICC_RISD_Pixel3_OnOff 2;
BA_ "GenSigSendType" SG_ 1364 ICC_RISD_Pixel4_OnOff 2;
BA_ "GenSigSendType" SG_ 1364 ICC_RISD_Pixel5_OnOff 2;
BA_ "GenSigSendType" SG_ 1364 ICC_RISD_Pixel6_OnOff 2;
BA_ "GenSigSendType" SG_ 1364 ICC_RISD_Pixel7_OnOff 2;
BA_ "GenSigSendType" SG_ 1364 ICC_RISD_Pixel8_OnOff 2;
BA_ "GenSigSendType" SG_ 1364 ICC_RISD_Pixel9_OnOff 2;
BA_ "GenSigSendType" SG_ 1364 ICC_RISD_Pixel10_OnOff 2;
BA_ "GenSigSendType" SG_ 1364 ICC_RISD_Pixel11_OnOff 2;
BA_ "GenSigSendType" SG_ 1364 ICC_RISD_Pixel12_OnOff 2;
BA_ "GenSigSendType" SG_ 1364 ICC_RISD_Pixel13_OnOff 2;
BA_ "GenSigSendType" SG_ 1364 ICC_RISD_Pixel14_OnOff 2;
BA_ "GenSigSendType" SG_ 1364 ICC_RISD_Pixel15_OnOff 2;
BA_ "GenSigSendType" SG_ 1364 ICC_RISD_Pixel16_OnOff 2;
BA_ "GenSigSendType" SG_ 1364 ICC_RISD_Pixel17_OnOff 2;
BA_ "GenSigSendType" SG_ 1364 ICC_RISD_Pixel18_OnOff 2;
BA_ "GenSigSendType" SG_ 1364 ICC_RISD_Pixel19_OnOff 2;
BA_ "GenSigSendType" SG_ 1364 ICC_RISD_Pixel20_OnOff 2;
BA_ "GenSigSendType" SG_ 1364 ICC_RISD_Pixel21_OnOff 2;
BA_ "GenSigSendType" SG_ 1364 ICC_RISD_Pixel22_OnOff 2;
BA_ "GenSigSendType" SG_ 1364 ICC_RISD_Pixel23_OnOff 2;
BA_ "GenSigSendType" SG_ 1364 ICC_RISD_Pixel24_OnOff 2;
BA_ "GenSigSendType" SG_ 1364 ICC_RISD_Pixel25_OnOff 2;
BA_ "GenSigSendType" SG_ 1364 ICC_RISD_Pixel26_OnOff 2;
BA_ "GenSigSendType" SG_ 1364 ICC_RISD_Pixel27_OnOff 2;
BA_ "GenSigSendType" SG_ 1364 ICC_RISD_Pixel28_OnOff 2;
BA_ "GenSigSendType" SG_ 1364 ICC_RISD_Pixel29_OnOff 2;
BA_ "GenSigSendType" SG_ 1364 ICC_RISD_Pixel30_OnOff 2;
BA_ "GenSigSendType" SG_ 1364 ICC_RISD_Pixel31_OnOff 2;
BA_ "GenSigSendType" SG_ 1364 ICC_RISD_Pixel32_OnOff 2;
BA_ "GenSigSendType" SG_ 1364 ICC_RISD_Pixel33_OnOff 2;
BA_ "GenSigSendType" SG_ 1364 ICC_RISD_Pixel34_OnOff 2;
BA_ "GenSigSendType" SG_ 1364 ICC_RISD_Pixel35_OnOff 2;
BA_ "GenSigSendType" SG_ 1364 ICC_RISD_Pixel36_OnOff 2;
BA_ "GenSigSendType" SG_ 1364 ICC_RISD_Pixel37_OnOff 2;
BA_ "GenSigSendType" SG_ 1364 ICC_RISD_Pixel38_OnOff 2;
BA_ "GenSigSendType" SG_ 1364 ICC_RISD_Pixel39_OnOff 2;
BA_ "GenSigSendType" SG_ 1364 ICC_RISD_Pixel40_OnOff 2;
BA_ "GenSigSendType" SG_ 1364 ICC_RISD_Pixel41_OnOff 2;
BA_ "GenSigSendType" SG_ 1364 ICC_RISD_Pixel42_OnOff 2;
BA_ "GenSigSendType" SG_ 1364 ICC_RISD_Pixel43_OnOff 2;
BA_ "GenSigSendType" SG_ 1364 ICC_RISD_Pixel44_OnOff 2;
BA_ "GenSigSendType" SG_ 1364 ICC_RISD_Pixel45_OnOff 2;
BA_ "GenSigSendType" SG_ 1364 ICC_RISD_Pixel46_OnOff 2;
BA_ "GenSigSendType" SG_ 1364 ICC_RISD_Pixel47_OnOff 2;
BA_ "GenSigSendType" SG_ 1364 ICC_RISD_Pixel48_OnOff 2;
BA_ "GenSigSendType" SG_ 1364 ICC_RISD_Pixel49_OnOff 2;
BA_ "GenSigSendType" SG_ 1364 ICC_RISD_Pixel50_OnOff 2;
BA_ "GenSigSendType" SG_ 1364 ICC_RISD_Pixel51_OnOff 2;
BA_ "GenSigSendType" SG_ 1364 ICC_RISD_Pixel52_OnOff 2;
BA_ "GenSigSendType" SG_ 1364 ICC_RISD_Pixel53_OnOff 2;
BA_ "GenSigSendType" SG_ 1364 ICC_RISD_Pixel54_OnOff 2;
BA_ "GenSigSendType" SG_ 1364 ICC_RISD_Pixel55_OnOff 2;
BA_ "GenSigSendType" SG_ 1364 ICC_RISD_Pixel56_OnOff 2;
BA_ "GenSigSendType" SG_ 1364 ICC_RISD_Pixel57_OnOff 2;
BA_ "GenSigSendType" SG_ 1364 ICC_RISD_Pixel58_OnOff 2;
BA_ "GenSigSendType" SG_ 1364 ICC_RISD_Pixel59_OnOff 2;
BA_ "GenSigSendType" SG_ 1364 ICC_RISD_Pixel60_OnOff 2;
BA_ "GenSigSendType" SG_ 1364 ICC_RISD_Pixel61_OnOff 2;
BA_ "GenSigSendType" SG_ 1364 ICC_RISD_Pixel62_OnOff 2;
BA_ "GenSigSendType" SG_ 1364 ICC_RISD_Pixel63_OnOff 2;
BA_ "GenSigSendType" SG_ 1364 ICC_RISD_Pixel64_OnOff 2;
BA_ "GenSigSendType" SG_ 1364 ICC_RISD_Pixel65_OnOff 2;
BA_ "GenSigSendType" SG_ 1364 ICC_RISD_Pixel66_OnOff 2;
BA_ "GenSigSendType" SG_ 1364 ICC_RISD_Pixel67_OnOff 2;
BA_ "GenSigSendType" SG_ 1364 ICC_RISD_Pixel68_OnOff 2;
BA_ "GenSigSendType" SG_ 1364 ICC_RISD_Pixel69_OnOff 2;
BA_ "GenSigSendType" SG_ 1364 ICC_RISD_Pixel70_OnOff 2;
BA_ "GenSigSendType" SG_ 1364 ICC_RISD_Pixel71_OnOff 2;
BA_ "GenSigSendType" SG_ 1364 ICC_RISD_Pixel72_OnOff 2;
BA_ "GenSigSendType" SG_ 1364 ICC_RISD_Pixel73_OnOff 2;
BA_ "GenSigSendType" SG_ 1364 ICC_RISD_Pixel74_OnOff 2;
BA_ "GenSigSendType" SG_ 1364 ICC_RISD_Pixel75_OnOff 2;
BA_ "GenSigSendType" SG_ 1364 ICC_RISD_Pixel76_OnOff 2;
BA_ "GenSigSendType" SG_ 1364 ICC_RISD_Pixel77_OnOff 2;
BA_ "GenSigSendType" SG_ 1364 ICC_RISD_Pixel78_OnOff 2;
BA_ "GenSigSendType" SG_ 1364 ICC_RISD_Pixel79_OnOff 2;
BA_ "GenSigSendType" SG_ 1364 ICC_RISD_Pixel80_OnOff 2;
BA_ "GenSigSendType" SG_ 1364 ICC_RISD_Pixel81_OnOff 2;
BA_ "GenSigSendType" SG_ 1364 ICC_RISD_Pixel82_OnOff 2;
BA_ "GenSigSendType" SG_ 1364 ICC_RISD_Pixel83_OnOff 2;
BA_ "GenSigSendType" SG_ 1364 ICC_RISD_Pixel84_OnOff 2;
BA_ "GenSigSendType" SG_ 1364 ICC_RISD_Pixel85_OnOff 2;
BA_ "GenSigSendType" SG_ 1364 ICC_RISD_Pixel86_OnOff 2;
BA_ "GenSigSendType" SG_ 1364 ICC_RISD_Pixel87_OnOff 2;
BA_ "GenSigSendType" SG_ 1364 ICC_RISD_Pixel88_OnOff 2;
BA_ "GenSigSendType" SG_ 1364 ICC_RISD_Pixel89_OnOff 2;
BA_ "GenSigSendType" SG_ 1364 ICC_RISD_Pixel90_OnOff 2;
BA_ "GenSigSendType" SG_ 1364 ICC_RISD_Pixel91_OnOff 2;
BA_ "GenSigSendType" SG_ 1364 ICC_RISD_Pixel92_OnOff 2;
BA_ "GenSigSendType" SG_ 1364 ICC_RISD_Pixel93_OnOff 2;
BA_ "GenSigSendType" SG_ 1364 ICC_RISD_Pixel94_OnOff 2;
BA_ "GenSigSendType" SG_ 1364 ICC_RISD_Pixel95_OnOff 2;
BA_ "GenSigSendType" SG_ 1364 ICC_RISD_Pixel96_OnOff 2;
BA_ "GenSigSendType" SG_ 1364 ICC_RISD_Pixel97_OnOff 2;
BA_ "GenSigSendType" SG_ 1364 ICC_RISD_Pixel98_OnOff 2;
BA_ "GenSigSendType" SG_ 1364 ICC_RISD_Pixel99_OnOff 2;
BA_ "GenSigSendType" SG_ 1364 ICC_RISD_Pixel100_OnOff 2;
BA_ "GenSigSendType" SG_ 1364 ICC_RISD_Pixel101_OnOff 2;
BA_ "GenSigSendType" SG_ 1364 ICC_RISD_Pixel102_OnOff 2;
BA_ "GenSigSendType" SG_ 1364 ICC_RISD_Pixel103_OnOff 2;
BA_ "GenSigSendType" SG_ 1364 ICC_RISD_Pixel104_OnOff 2;
BA_ "GenSigSendType" SG_ 1364 ICC_RISD_Pixel105_OnOff 2;
BA_ "GenSigSendType" SG_ 1364 ICC_RISD_Pixel106_OnOff 2;
BA_ "GenSigSendType" SG_ 1364 ICC_RISD_Pixel107_OnOff 2;
BA_ "GenSigSendType" SG_ 1364 ICC_RISD_Pixel108_OnOff 2;
BA_ "GenSigSendType" SG_ 1364 ICC_RISD_Pixel109_OnOff 2;
BA_ "GenSigSendType" SG_ 1364 ICC_RISD_Pixel110_OnOff 2;
BA_ "GenSigSendType" SG_ 1364 ICC_RISD_Pixel111_OnOff 2;
BA_ "GenSigSendType" SG_ 1364 ICC_RISD_Pixel112_OnOff 2;
BA_ "GenSigSendType" SG_ 1364 ICC_RISD_Pixel113_OnOff 2;
BA_ "GenSigSendType" SG_ 1364 ICC_RISD_Pixel114_OnOff 2;
BA_ "GenSigSendType" SG_ 1364 ICC_RISD_Pixel115_OnOff 2;
BA_ "GenSigSendType" SG_ 1364 ICC_RISD_Pixel116_OnOff 2;
BA_ "GenSigSendType" SG_ 1364 ICC_RISD_Pixel117_OnOff 2;
BA_ "GenSigSendType" SG_ 1364 ICC_RISD_Pixel118_OnOff 2;
BA_ "GenSigSendType" SG_ 1364 ICC_RISD_Pixel119_OnOff 2;
BA_ "GenSigSendType" SG_ 1364 ICC_RISD_Pixel120_OnOff 2;
BA_ "GenSigSendType" SG_ 1364 ICC_RISD_Pixel121_OnOff 2;
BA_ "GenSigSendType" SG_ 1364 ICC_RISD_Pixel122_OnOff 2;
BA_ "GenSigSendType" SG_ 1364 ICC_RISD_Pixel123_OnOff 2;
BA_ "GenSigSendType" SG_ 1364 ICC_RISD_Pixel124_OnOff 2;
BA_ "GenSigSendType" SG_ 1364 ICC_RISD_Pixel125_OnOff 2;
BA_ "GenSigSendType" SG_ 1364 ICC_RISD_Pixel126_OnOff 2;
BA_ "GenSigSendType" SG_ 1364 ICC_RISD_Pixel127_OnOff 2;
BA_ "GenSigSendType" SG_ 1364 ICC_RISD_Pixel128_OnOff 2;
BA_ "GenSigSendType" SG_ 1364 ICC_RISD_Pixel129_OnOff 2;
BA_ "GenSigSendType" SG_ 1364 ICC_RISD_Pixel130_OnOff 2;
BA_ "GenSigSendType" SG_ 1364 ICC_RISD_Pixel131_OnOff 2;
BA_ "GenSigSendType" SG_ 1364 ICC_RISD_Pixel132_OnOff 2;
BA_ "GenSigSendType" SG_ 1364 ICC_RISD_Pixel133_OnOff 2;
BA_ "GenSigSendType" SG_ 1364 ICC_RISD_Pixel134_OnOff 2;
BA_ "GenSigSendType" SG_ 1364 ICC_RISD_Pixel135_OnOff 2;
BA_ "GenSigSendType" SG_ 1364 ICC_RISD_Pixel136_OnOff 2;
BA_ "GenSigSendType" SG_ 1364 ICC_RISD_Pixel137_OnOff 2;
BA_ "GenSigSendType" SG_ 1364 ICC_RISD_Pixel138_OnOff 2;
BA_ "GenSigSendType" SG_ 1364 ICC_RISD_Pixel139_OnOff 2;
BA_ "GenSigSendType" SG_ 1364 ICC_RISD_Pixel140_OnOff 2;
BA_ "GenSigSendType" SG_ 1364 ICC_RISD_Pixel141_OnOff 2;
BA_ "GenSigSendType" SG_ 1364 ICC_RISD_Pixel142_OnOff 2;
BA_ "GenSigSendType" SG_ 1364 ICC_RISD_Pixel143_OnOff 2;
BA_ "GenSigSendType" SG_ 1364 ICC_RISD_Pixel144_OnOff 2;
BA_ "GenSigSendType" SG_ 1364 ICC_RISD_Pixel145_OnOff 2;
BA_ "GenSigSendType" SG_ 1364 ICC_RISD_Pixel146_OnOff 2;
BA_ "GenSigSendType" SG_ 1364 ICC_RISD_Pixel147_OnOff 2;
BA_ "GenSigSendType" SG_ 1364 ICC_RISD_Pixel148_OnOff 2;
BA_ "GenSigSendType" SG_ 1364 ICC_RISD_Pixel149_OnOff 2;
BA_ "GenSigSendType" SG_ 1364 ICC_RISD_Pixel150_OnOff 2;
BA_ "GenSigSendType" SG_ 1364 ICC_RISD_Pixel151_OnOff 2;
BA_ "GenSigSendType" SG_ 1364 ICC_RISD_Pixel152_OnOff 2;
BA_ "GenSigSendType" SG_ 1364 ICC_RISD_Pixel153_OnOff 2;
BA_ "GenSigSendType" SG_ 1364 ICC_RISD_Pixel154_OnOff 2;
BA_ "GenSigSendType" SG_ 1364 ICC_RISD_Pixel155_OnOff 2;
BA_ "GenSigSendType" SG_ 1364 ICC_RISD_Pixel156_OnOff 2;
BA_ "GenSigSendType" SG_ 1364 ICC_RISD_Pixel157_OnOff 2;
BA_ "GenSigSendType" SG_ 1364 ICC_RISD_Pixel158_OnOff 2;
BA_ "GenSigSendType" SG_ 1364 ICC_RISD_Pixel159_OnOff 2;
BA_ "GenSigSendType" SG_ 1364 ICC_RISD_Pixel160_OnOff 2;
BA_ "GenSigSendType" SG_ 1364 ICC_RISD_Pixel161_OnOff 2;
BA_ "GenSigSendType" SG_ 1364 ICC_RISD_Pixel162_OnOff 2;
BA_ "GenSigSendType" SG_ 1364 ICC_RISD_Pixel163_OnOff 2;
BA_ "GenSigSendType" SG_ 1364 ICC_RISD_Pixel164_OnOff 2;
BA_ "GenSigSendType" SG_ 1364 ICC_RISD_Pixel165_OnOff 2;
BA_ "GenSigSendType" SG_ 1364 ICC_RISD_Pixel166_OnOff 2;
BA_ "GenSigSendType" SG_ 1364 ICC_RISD_Pixel167_OnOff 2;
BA_ "GenSigSendType" SG_ 1364 ICC_RISD_Pixel168_OnOff 2;
BA_ "GenSigSendType" SG_ 1364 ICC_RISD_Pixel169_OnOff 2;
BA_ "GenSigSendType" SG_ 1364 ICC_RISD_Pixel170_OnOff 2;
BA_ "GenSigSendType" SG_ 1364 ICC_RISD_Pixel171_OnOff 2;
BA_ "GenSigSendType" SG_ 1364 ICC_RISD_Pixel172_OnOff 2;
BA_ "GenSigSendType" SG_ 1364 ICC_RISD_Pixel173_OnOff 2;
BA_ "GenSigSendType" SG_ 1364 ICC_RISD_Pixel174_OnOff 2;
BA_ "GenSigSendType" SG_ 1364 ICC_RISD_Pixel175_OnOff 2;
BA_ "GenSigSendType" SG_ 1364 ICC_RISD_Pixel176_OnOff 2;
BA_ "GenSigSendType" SG_ 1364 ICC_RISD_Pixel177_OnOff 2;
BA_ "GenSigSendType" SG_ 1364 ICC_RISD_Pixel178_OnOff 2;
BA_ "GenSigSendType" SG_ 1364 ICC_RISD_Pixel179_OnOff 2;
BA_ "GenSigSendType" SG_ 1364 ICC_RISD_Pixel180_OnOff 2;
BA_ "GenSigSendType" SG_ 1364 ICC_RISD_Pixel181_OnOff 2;
BA_ "GenSigSendType" SG_ 1364 ICC_RISD_Pixel182_OnOff 2;
BA_ "GenSigSendType" SG_ 1364 ICC_RISD_Pixel183_OnOff 2;
BA_ "GenSigSendType" SG_ 1364 ICC_RISD_Pixel184_OnOff 2;
BA_ "GenSigSendType" SG_ 1364 ICC_RISD_Pixel185_OnOff 2;
BA_ "GenSigSendType" SG_ 1364 ICC_RISD_Pixel186_OnOff 2;
BA_ "GenSigSendType" SG_ 1364 ICC_RISD_Pixel187_OnOff 2;
BA_ "GenSigSendType" SG_ 1364 ICC_RISD_Pixel188_OnOff 2;
BA_ "GenSigSendType" SG_ 1364 ICC_RISD_Pixel189_OnOff 2;
BA_ "GenSigSendType" SG_ 1364 ICC_RISD_Pixel190_OnOff 2;
BA_ "GenSigSendType" SG_ 1364 ICC_RISD_Pixel191_OnOff 2;
BA_ "GenSigSendType" SG_ 1364 ICC_RISD_Pixel192_OnOff 2;
BA_ "GenSigSendType" SG_ 1364 ICC_RISD_Pixel193_OnOff 2;
BA_ "GenSigSendType" SG_ 1364 ICC_RISD_Pixel194_OnOff 2;
BA_ "GenSigSendType" SG_ 1364 ICC_RISD_Pixel195_OnOff 2;
BA_ "GenSigSendType" SG_ 1364 ICC_RISD_Pixel196_OnOff 2;
BA_ "GenSigSendType" SG_ 1364 ICC_RISD_Pixel197_OnOff 2;
BA_ "GenSigSendType" SG_ 1364 ICC_RISD_Pixel198_OnOff 2;
BA_ "GenSigSendType" SG_ 1364 ICC_RISD_Pixel199_OnOff 2;
BA_ "GenSigSendType" SG_ 1364 ICC_RISD_Pixel200_OnOff 2;
BA_ "GenSigSendType" SG_ 1364 ICC_RISD_Pixel201_OnOff 2;
BA_ "GenSigSendType" SG_ 1364 ICC_RISD_Pixel202_OnOff 2;
BA_ "GenSigSendType" SG_ 1364 ICC_RISD_Pixel203_OnOff 2;
BA_ "GenSigSendType" SG_ 1364 ICC_RISD_Pixel204_OnOff 2;
BA_ "GenSigSendType" SG_ 1364 ICC_RISD_Pixel205_OnOff 2;
BA_ "GenSigSendType" SG_ 1364 ICC_RISD_Pixel206_OnOff 2;
BA_ "GenSigSendType" SG_ 1364 ICC_RISD_Pixel207_OnOff 2;
BA_ "GenSigSendType" SG_ 1364 ICC_RISD_Pixel208_OnOff 2;
BA_ "GenSigSendType" SG_ 1364 ICC_RISD_Pixel209_OnOff 2;
BA_ "GenSigSendType" SG_ 1364 ICC_RISD_Pixel210_OnOff 2;
BA_ "GenSigSendType" SG_ 1364 ICC_RISD_Pixel211_OnOff 2;
BA_ "GenSigSendType" SG_ 1364 ICC_RISD_Pixel212_OnOff 2;
BA_ "GenSigSendType" SG_ 1364 ICC_RISD_Pixel213_OnOff 2;
BA_ "GenSigSendType" SG_ 1364 ICC_RISD_Pixel214_OnOff 2;
BA_ "GenSigSendType" SG_ 1364 ICC_RISD_Pixel215_OnOff 2;
BA_ "GenSigSendType" SG_ 1364 ICC_RISD_Pixel216_OnOff 2;
BA_ "GenSigSendType" SG_ 1364 ICC_RISD_Pixel217_OnOff 2;
BA_ "GenSigSendType" SG_ 1364 ICC_RISD_Pixel218_OnOff 2;
BA_ "GenSigSendType" SG_ 1364 ICC_RISD_Pixel219_OnOff 2;
BA_ "GenSigSendType" SG_ 1364 ICC_RISD_Pixel220_OnOff 2;
BA_ "GenSigSendType" SG_ 1364 ICC_RISD_Pixel221_OnOff 2;
BA_ "GenSigSendType" SG_ 1364 ICC_RISD_Pixel222_OnOff 2;
BA_ "GenSigSendType" SG_ 1364 ICC_RISD_Pixel223_OnOff 2;
BA_ "GenSigSendType" SG_ 1364 ICC_RISD_Pixel224_OnOff 2;
BA_ "GenSigSendType" SG_ 1364 ICC_RISD_Pixel225_OnOff 2;
BA_ "GenSigSendType" SG_ 1364 ICC_RISD_Pixel226_OnOff 2;
BA_ "GenSigSendType" SG_ 1364 ICC_RISD_Pixel227_OnOff 2;
BA_ "GenSigSendType" SG_ 1364 ICC_RISD_Pixel228_OnOff 2;
BA_ "GenSigSendType" SG_ 1364 ICC_RISD_Pixel229_OnOff 2;
BA_ "GenSigSendType" SG_ 1364 ICC_RISD_Pixel230_OnOff 2;
BA_ "GenSigSendType" SG_ 1364 ICC_RISD_Pixel231_OnOff 2;
BA_ "GenSigSendType" SG_ 1364 ICC_RISD_Pixel232_OnOff 2;
BA_ "GenSigSendType" SG_ 1364 ICC_RISD_Pixel233_OnOff 2;
BA_ "GenSigSendType" SG_ 1364 ICC_RISD_Pixel234_OnOff 2;
BA_ "GenSigSendType" SG_ 1364 ICC_RISD_Pixel235_OnOff 2;
BA_ "GenSigSendType" SG_ 1364 ICC_RISD_Pixel236_OnOff 2;
BA_ "GenSigSendType" SG_ 1364 ICC_RISD_Pixel237_OnOff 2;
BA_ "GenSigSendType" SG_ 1364 ICC_RISD_Pixel238_OnOff 2;
BA_ "GenSigSendType" SG_ 1364 ICC_RISD_Pixel239_OnOff 2;
BA_ "GenSigSendType" SG_ 1364 ICC_RISD_Pixel240_OnOff 2;
BA_ "GenSigSendType" SG_ 1364 ICC_RISD_Pixel241_OnOff 2;
BA_ "GenSigSendType" SG_ 1364 ICC_RISD_Pixel242_OnOff 2;
BA_ "GenSigSendType" SG_ 1364 ICC_RISD_Pixel243_OnOff 2;
BA_ "GenSigSendType" SG_ 1364 ICC_RISD_Pixel244_OnOff 2;
BA_ "GenSigSendType" SG_ 1364 ICC_RISD_Pixel245_OnOff 2;
BA_ "GenSigSendType" SG_ 1364 ICC_RISD_Pixel246_OnOff 2;
BA_ "GenSigSendType" SG_ 1364 ICC_RISD_Pixel247_OnOff 2;
BA_ "GenSigSendType" SG_ 1364 ICC_RISD_Pixel248_OnOff 2;
BA_ "GenSigSendType" SG_ 1364 ICC_RISD_Pixel249_OnOff 2;
BA_ "GenSigSendType" SG_ 1364 ICC_RISD_Pixel250_OnOff 2;
BA_ "GenSigSendType" SG_ 1364 ICC_RISD_Pixel251_OnOff 2;
BA_ "GenSigSendType" SG_ 1364 ICC_RISD_Pixel252_OnOff 2;
BA_ "GenSigSendType" SG_ 1364 ICC_RISD_Pixel253_OnOff 2;
BA_ "GenSigSendType" SG_ 1364 ICC_RISD_Pixel254_OnOff 2;
BA_ "GenSigSendType" SG_ 1364 ICC_RISD_Pixel255_OnOff 2;
BA_ "GenSigSendType" SG_ 1364 ICC_RISD_Pixel256_OnOff 2;
BA_ "GenSigSendType" SG_ 1364 ICC_RISD_Pixel257_OnOff 2;
BA_ "GenSigSendType" SG_ 1364 ICC_RISD_Pixel258_OnOff 2;
BA_ "GenSigSendType" SG_ 1364 ICC_RISD_Pixel259_OnOff 2;
BA_ "GenSigSendType" SG_ 1364 ICC_RISD_Pixel260_OnOff 2;
BA_ "GenSigSendType" SG_ 1364 ICC_RISD_Pixel261_OnOff 2;
BA_ "GenSigSendType" SG_ 1364 ICC_RISD_Pixel262_OnOff 2;
BA_ "GenSigSendType" SG_ 1364 ICC_RISD_Pixel263_OnOff 2;
BA_ "GenSigSendType" SG_ 1364 ICC_RISD_Pixel264_OnOff 2;
BA_ "GenSigSendType" SG_ 1364 ICC_RISD_Pixel265_OnOff 2;
BA_ "GenSigSendType" SG_ 1364 ICC_RISD_Pixel266_OnOff 2;
BA_ "GenSigSendType" SG_ 1364 ICC_RISD_Pixel267_OnOff 2;
BA_ "GenSigSendType" SG_ 1364 ICC_RISD_Pixel268_OnOff 2;
BA_ "GenSigSendType" SG_ 1364 ICC_RISD_Pixel269_OnOff 2;
BA_ "GenSigSendType" SG_ 1364 ICC_RISD_Pixel270_OnOff 2;
BA_ "GenSigSendType" SG_ 1364 ICC_RISD_Pixel271_OnOff 2;
BA_ "GenSigSendType" SG_ 1364 ICC_RISD_Pixel272_OnOff 2;
BA_ "GenSigSendType" SG_ 1364 ICC_RISD_Pixel273_OnOff 2;
BA_ "GenSigSendType" SG_ 1364 ICC_RISD_Pixel274_OnOff 2;
BA_ "GenSigSendType" SG_ 1364 ICC_RISD_Pixel275_OnOff 2;
BA_ "GenSigSendType" SG_ 1364 ICC_RISD_Pixel276_OnOff 2;
BA_ "GenSigSendType" SG_ 1364 ICC_RISD_Pixel277_OnOff 2;
BA_ "GenSigSendType" SG_ 1364 ICC_RISD_Pixel278_OnOff 2;
BA_ "GenSigSendType" SG_ 1364 ICC_RISD_Pixel279_OnOff 2;
BA_ "GenSigSendType" SG_ 1364 ICC_RISD_Pixel280_OnOff 2;
BA_ "GenSigSendType" SG_ 1364 ICC_RISD_Pixel281_OnOff 2;
BA_ "GenSigSendType" SG_ 1364 ICC_RISD_Pixel282_OnOff 2;
BA_ "GenSigSendType" SG_ 1364 ICC_RISD_Pixel283_OnOff 2;
BA_ "GenSigSendType" SG_ 1364 ICC_RISD_Pixel284_OnOff 2;
BA_ "GenSigSendType" SG_ 1364 ICC_RISD_Pixel285_OnOff 2;
BA_ "GenSigSendType" SG_ 1364 ICC_RISD_Pixel286_OnOff 2;
BA_ "GenSigSendType" SG_ 1364 ICC_RISD_Pixel287_OnOff 2;
BA_ "GenSigSendType" SG_ 1364 ICC_RISD_Pixel288_OnOff 2;
BA_ "GenSigSendType" SG_ 1364 ICC_RISD_Pixel289_OnOff 2;
BA_ "GenSigSendType" SG_ 1364 ICC_RISD_Pixel290_OnOff 2;
BA_ "GenSigSendType" SG_ 1364 ICC_RISD_Pixel291_OnOff 2;
BA_ "GenSigSendType" SG_ 1364 ICC_RISD_Pixel292_OnOff 2;
BA_ "GenSigSendType" SG_ 1364 ICC_RISD_Pixel293_OnOff 2;
BA_ "GenSigSendType" SG_ 1364 ICC_RISD_Pixel294_OnOff 2;
BA_ "GenSigSendType" SG_ 1364 ICC_RISD_Pixel295_OnOff 2;
BA_ "GenSigSendType" SG_ 1364 ICC_RISD_Pixel296_OnOff 2;
BA_ "GenSigSendType" SG_ 1364 ICC_RISD_Pixel297_OnOff 2;
BA_ "GenSigSendType" SG_ 1364 ICC_RISD_Pixel298_OnOff 2;
BA_ "GenSigSendType" SG_ 1364 ICC_RISD_Pixel299_OnOff 2;
BA_ "GenSigSendType" SG_ 1364 ICC_RISD_Pixel300_OnOff 2;
BA_ "GenSigSendType" SG_ 1364 ICC_RISD_Pixel301_OnOff 2;
BA_ "GenSigSendType" SG_ 1364 ICC_RISD_Pixel302_OnOff 2;
BA_ "GenSigSendType" SG_ 1364 ICC_RISD_Pixel303_OnOff 2;
BA_ "GenSigSendType" SG_ 1364 ICC_RISD_Pixel304_OnOff 2;
BA_ "GenSigSendType" SG_ 1364 ICC_RISD_Pixel305_OnOff 2;
BA_ "GenSigSendType" SG_ 1364 ICC_RISD_Pixel306_OnOff 2;
BA_ "GenSigSendType" SG_ 1364 ICC_RISD_Pixel307_OnOff 2;
BA_ "GenSigSendType" SG_ 1364 ICC_RISD_Pixel308_OnOff 2;
BA_ "GenSigSendType" SG_ 1364 ICC_RISD_Pixel309_OnOff 2;
BA_ "GenSigSendType" SG_ 1364 ICC_RISD_Pixel310_OnOff 2;
BA_ "GenSigSendType" SG_ 1364 ICC_RISD_Pixel311_OnOff 2;
BA_ "GenSigSendType" SG_ 1364 ICC_RISD_Pixel312_OnOff 2;
BA_ "GenSigSendType" SG_ 1364 ICC_RISD_Pixel313_OnOff 2;
BA_ "GenSigSendType" SG_ 1364 ICC_RISD_Pixel314_OnOff 2;
BA_ "GenSigSendType" SG_ 1364 ICC_RISD_Pixel315_OnOff 2;
BA_ "GenSigSendType" SG_ 1364 ICC_RISD_Pixel316_OnOff 2;
BA_ "GenSigSendType" SG_ 1364 ICC_RISD_Pixel317_OnOff 2;
BA_ "GenSigSendType" SG_ 1364 ICC_RISD_Pixel318_OnOff 2;
BA_ "GenSigSendType" SG_ 1364 ICC_RISD_Pixel319_OnOff 2;
BA_ "GenSigSendType" SG_ 1364 ICC_RISD_Pixel320_OnOff 2;
BA_ "GenSigSendType" SG_ 1364 ICC_RISD_Pixel321_OnOff 2;
BA_ "GenSigSendType" SG_ 1364 ICC_RISD_Pixel322_OnOff 2;
BA_ "GenSigSendType" SG_ 1364 ICC_RISD_Pixel323_OnOff 2;
BA_ "GenSigSendType" SG_ 1364 ICC_RISD_Pixel324_OnOff 2;
BA_ "GenSigSendType" SG_ 1364 ICC_RISD_Pixel325_OnOff 2;
BA_ "GenSigSendType" SG_ 1364 ICC_RISD_Pixel326_OnOff 2;
BA_ "GenSigSendType" SG_ 1364 ICC_RISD_Pixel327_OnOff 2;
BA_ "GenSigSendType" SG_ 1364 ICC_RISD_Pixel328_OnOff 2;
BA_ "GenSigSendType" SG_ 1364 ICC_RISD_Pixel329_OnOff 2;
BA_ "GenSigSendType" SG_ 1364 ICC_RISD_Pixel330_OnOff 2;
BA_ "GenSigSendType" SG_ 1364 ICC_RISD_Pixel331_OnOff 2;
BA_ "GenSigSendType" SG_ 1364 ICC_RISD_Pixel332_OnOff 2;
BA_ "GenSigSendType" SG_ 1364 ICC_RISD_Pixel333_OnOff 2;
BA_ "GenSigSendType" SG_ 1364 ICC_RISD_Pixel334_OnOff 2;
BA_ "GenSigSendType" SG_ 1364 ICC_RISD_Pixel335_OnOff 2;
BA_ "GenSigSendType" SG_ 1364 ICC_RISD_Pixel336_OnOff 2;
BA_ "GenSigSendType" SG_ 1364 ICC_RISD_Pixel337_OnOff 2;
BA_ "GenSigSendType" SG_ 1364 ICC_RISD_Pixel338_OnOff 2;
BA_ "GenSigSendType" SG_ 1364 ICC_RISD_Pixel339_OnOff 2;
BA_ "GenSigSendType" SG_ 1364 ICC_RISD_Pixel340_OnOff 2;
BA_ "GenSigSendType" SG_ 1364 ICC_RISD_Pixel341_OnOff 2;
BA_ "GenSigSendType" SG_ 1364 ICC_RISD_Pixel342_OnOff 2;
BA_ "GenSigSendType" SG_ 1364 ICC_RISD_Pixel343_OnOff 2;
BA_ "GenSigSendType" SG_ 1364 ICC_RISD_Pixel344_OnOff 2;
BA_ "GenSigSendType" SG_ 1364 ICC_RISD_Pixel345_OnOff 2;
BA_ "GenSigSendType" SG_ 1364 ICC_RISD_Pixel346_OnOff 2;
BA_ "GenSigSendType" SG_ 1364 ICC_RISD_Pixel347_OnOff 2;
BA_ "GenSigSendType" SG_ 1364 ICC_RISD_Pixel348_OnOff 2;
BA_ "GenSigSendType" SG_ 1364 ICC_RISD_Pixel349_OnOff 2;
BA_ "GenSigSendType" SG_ 1364 ICC_RISD_Pixel350_OnOff 2;
BA_ "GenSigSendType" SG_ 1364 ICC_RISD_Pixel351_OnOff 2;
BA_ "GenSigSendType" SG_ 1364 ICC_RISD_Pixel352_OnOff 2;
BA_ "GenSigSendType" SG_ 1364 ICC_RISD_Pixel353_OnOff 2;
BA_ "GenSigSendType" SG_ 1364 ICC_RISD_Pixel354_OnOff 2;
BA_ "GenSigSendType" SG_ 1364 ICC_RISD_Pixel355_OnOff 2;
BA_ "GenSigSendType" SG_ 1364 ICC_RISD_Pixel356_OnOff 2;
BA_ "GenSigSendType" SG_ 1364 ICC_RISD_Pixel357_OnOff 2;
BA_ "GenSigSendType" SG_ 1364 ICC_RISD_Pixel358_OnOff 2;
BA_ "GenSigSendType" SG_ 1364 ICC_RISD_Pixel359_OnOff 2;
BA_ "GenSigSendType" SG_ 1364 ICC_RISD_Pixel360_OnOff 2;
BA_ "GenSigSendType" SG_ 1364 ICC_RISD_Pixel361_OnOff 2;
BA_ "GenSigSendType" SG_ 1364 ICC_RISD_Pixel362_OnOff 2;
BA_ "GenSigSendType" SG_ 1364 ICC_RISD_Pixel363_OnOff 2;
BA_ "GenSigSendType" SG_ 1364 ICC_RISD_Pixel364_OnOff 2;
BA_ "GenSigSendType" SG_ 1364 ICC_RISD_Pixel365_OnOff 2;
BA_ "GenSigSendType" SG_ 1364 ICC_RISD_Pixel366_OnOff 2;
BA_ "GenSigSendType" SG_ 1364 ICC_RISD_Pixel367_OnOff 2;
BA_ "GenSigSendType" SG_ 1364 ICC_RISD_Pixel368_OnOff 2;
BA_ "GenSigSendType" SG_ 1364 ICC_RISD_Pixel369_OnOff 2;
BA_ "GenSigSendType" SG_ 1364 ICC_RISD_Pixel370_OnOff 2;
BA_ "GenSigSendType" SG_ 1364 ICC_RISD_Pixel371_OnOff 2;
BA_ "GenSigSendType" SG_ 1364 ICC_RISD_Pixel372_OnOff 2;
BA_ "GenSigSendType" SG_ 1364 ICC_RISD_Pixel373_OnOff 2;
BA_ "GenSigSendType" SG_ 1364 ICC_RISD_Pixel374_OnOff 2;
BA_ "GenSigSendType" SG_ 1364 ICC_RISD_Pixel375_OnOff 2;
BA_ "GenSigSendType" SG_ 1364 ICC_RISD_Pixel376_OnOff 2;
BA_ "GenSigSendType" SG_ 1364 ICC_RISD_Pixel377_OnOff 2;
BA_ "GenSigSendType" SG_ 1364 ICC_RISD_Pixel378_OnOff 2;
BA_ "GenSigSendType" SG_ 1364 ICC_RISD_Pixel379_OnOff 2;
BA_ "GenSigSendType" SG_ 1364 ICC_RISD_Pixel380_OnOff 2;
BA_ "GenSigSendType" SG_ 1364 ICC_RISD_Pixel381_OnOff 2;
BA_ "GenSigSendType" SG_ 1364 ICC_RISD_Pixel382_OnOff 2;
BA_ "GenSigSendType" SG_ 1364 ICC_RISD_Pixel383_OnOff 2;
BA_ "GenSigSendType" SG_ 1364 ICC_RISD_Pixel384_OnOff 2;
BA_ "GenSigSendType" SG_ 1364 ICC_RISD_Pixel385_OnOff 2;
BA_ "GenSigSendType" SG_ 1364 ICC_RISD_Pixel386_OnOff 2;
BA_ "GenSigSendType" SG_ 1364 ICC_RISD_Pixel387_OnOff 2;
BA_ "GenSigSendType" SG_ 1364 ICC_RISD_Pixel388_OnOff 2;
BA_ "GenSigSendType" SG_ 1364 ICC_RISD_Pixel389_OnOff 2;
BA_ "GenSigSendType" SG_ 1364 ICC_RISD_Pixel390_OnOff 2;
BA_ "GenSigSendType" SG_ 1364 ICC_RISD_Pixel391_OnOff 2;
BA_ "GenSigSendType" SG_ 1364 ICC_RISD_Pixel392_OnOff 2;
BA_ "GenSigSendType" SG_ 1364 ICC_RISD_Pixel393_OnOff 2;
BA_ "GenSigSendType" SG_ 1364 ICC_RISD_Pixel394_OnOff 2;
BA_ "GenSigSendType" SG_ 1364 ICC_RISD_Pixel395_OnOff 2;
BA_ "GenSigSendType" SG_ 1364 ICC_RISD_Pixel396_OnOff 2;
BA_ "GenSigSendType" SG_ 1364 ICC_RISD_Pixel397_OnOff 2;
BA_ "GenSigSendType" SG_ 1364 ICC_RISD_Pixel398_OnOff 2;
BA_ "GenSigSendType" SG_ 1364 ICC_RISD_Pixel399_OnOff 2;
BA_ "GenSigSendType" SG_ 1364 ICC_RISD_Pixel400_OnOff 2;
BA_ "GenSigSendType" SG_ 1364 ICC_RISD_Pixel401_OnOff 2;
BA_ "GenSigSendType" SG_ 1364 ICC_RISD_Pixel402_OnOff 2;
BA_ "GenSigSendType" SG_ 1364 ICC_RISD_Pixel403_OnOff 2;
BA_ "GenSigSendType" SG_ 1364 ICC_RISD_Pixel404_OnOff 2;
BA_ "GenSigSendType" SG_ 1364 ICC_RISD_Pixel405_OnOff 2;
BA_ "GenSigSendType" SG_ 1364 ICC_RISD_Pixel406_OnOff 2;
BA_ "GenSigSendType" SG_ 1364 ICC_RISD_Pixel407_OnOff 2;
BA_ "GenSigSendType" SG_ 1364 ICC_RISD_Pixel408_OnOff 2;
BA_ "GenSigSendType" SG_ 1364 ICC_RISD_Pixel409_OnOff 2;
BA_ "GenSigSendType" SG_ 1364 ICC_RISD_Pixel410_OnOff 2;
BA_ "GenSigSendType" SG_ 1364 ICC_RISD_Pixel411_OnOff 2;
BA_ "GenSigSendType" SG_ 1364 ICC_RISD_Pixel412_OnOff 2;
BA_ "GenSigSendType" SG_ 1364 ICC_RISD_Pixel413_OnOff 2;
BA_ "GenSigSendType" SG_ 1364 ICC_RISD_Pixel414_OnOff 2;
BA_ "GenSigSendType" SG_ 1364 ICC_RISD_Pixel415_OnOff 2;
BA_ "GenSigSendType" SG_ 1364 ICC_RISD_Pixel416_OnOff 2;
BA_ "GenSigSendType" SG_ 1364 ICC_RISD_Pixel417_OnOff 2;
BA_ "GenSigSendType" SG_ 1364 ICC_RISD_Pixel418_OnOff 2;
BA_ "GenSigSendType" SG_ 1364 ICC_RISD_Pixel419_OnOff 2;
BA_ "GenSigSendType" SG_ 1364 ICC_RISD_Pixel420_OnOff 2;
BA_ "GenSigSendType" SG_ 1364 ICC_RISD_Pixel421_OnOff 2;
BA_ "GenSigSendType" SG_ 1364 ICC_RISD_Pixel422_OnOff 2;
BA_ "GenSigSendType" SG_ 1364 ICC_RISD_Pixel423_OnOff 2;
BA_ "GenSigSendType" SG_ 1364 ICC_RISD_Pixel424_OnOff 2;
BA_ "GenSigSendType" SG_ 1364 ICC_RISD_Pixel425_OnOff 2;
BA_ "GenSigSendType" SG_ 1364 ICC_RISD_Pixel426_OnOff 2;
BA_ "GenSigSendType" SG_ 1364 ICC_RISD_Pixel427_OnOff 2;
BA_ "GenSigSendType" SG_ 1364 ICC_RISD_Pixel428_OnOff 2;
BA_ "GenSigSendType" SG_ 1364 ICC_RISD_Pixel429_OnOff 2;
BA_ "GenSigSendType" SG_ 1364 ICC_RISD_Pixel430_OnOff 2;
BA_ "GenSigSendType" SG_ 1364 ICC_RISD_Pixel431_OnOff 2;
BA_ "GenSigSendType" SG_ 1364 ICC_RISD_Pixel432_OnOff 2;
BA_ "GenSigSendType" SG_ 1364 ICC_RISD_Pixel433_OnOff 2;
BA_ "GenSigSendType" SG_ 1364 ICC_RISD_Pixel434_OnOff 2;
BA_ "GenSigSendType" SG_ 1364 ICC_RISD_Pixel435_OnOff 2;
BA_ "GenSigSendType" SG_ 1364 ICC_RISD_Pixel436_OnOff 2;
BA_ "GenSigSendType" SG_ 1364 ICC_RISD_Pixel437_OnOff 2;
BA_ "GenSigSendType" SG_ 1364 ICC_RISD_Pixel438_OnOff 2;
BA_ "GenSigSendType" SG_ 1364 ICC_RISD_Pixel439_OnOff 2;
BA_ "GenSigSendType" SG_ 1364 ICC_RISD_Pixel440_OnOff 2;
BA_ "GenSigSendType" SG_ 1364 ICC_RISD_Pixel441_OnOff 2;
BA_ "GenSigSendType" SG_ 1364 ICC_RISD_Pixel442_OnOff 2;
BA_ "GenSigSendType" SG_ 1364 ICC_RISD_Pixel443_OnOff 2;
BA_ "GenSigSendType" SG_ 1364 ICC_RISD_Pixel444_OnOff 2;
BA_ "GenSigSendType" SG_ 1364 ICC_RISD_Pixel445_OnOff 2;
BA_ "GenSigSendType" SG_ 1364 ICC_RISD_Pixel446_OnOff 2;
BA_ "GenSigSendType" SG_ 1364 ICC_RISD_Pixel447_OnOff 2;
BA_ "GenSigSendType" SG_ 1364 ICC_RISD_Pixel448_OnOff 2;
BA_ "GenSigSendType" SG_ 1364 ICC_RISD_Pixel449_OnOff 2;
BA_ "GenSigSendType" SG_ 1364 ICC_RISD_Pixel450_OnOff 2;
BA_ "GenSigSendType" SG_ 1364 ICC_RISD_Pixel451_OnOff 2;
BA_ "GenSigSendType" SG_ 1364 ICC_RISD_Pixel452_OnOff 2;
BA_ "GenSigSendType" SG_ 1364 ICC_RISD_Pixel453_OnOff 2;
BA_ "GenSigSendType" SG_ 1364 ICC_RISD_Pixel454_OnOff 2;
BA_ "GenSigSendType" SG_ 1364 ICC_RISD_Pixel455_OnOff 2;
BA_ "GenSigSendType" SG_ 1364 ICC_RISD_Pixel456_OnOff 2;
BA_ "GenSigSendType" SG_ 1364 ICC_RISD_Pixel457_OnOff 2;
BA_ "GenSigSendType" SG_ 1364 ICC_RISD_Pixel458_OnOff 2;
BA_ "GenSigSendType" SG_ 1364 ICC_RISD_Pixel459_OnOff 2;
BA_ "GenSigSendType" SG_ 1364 ICC_RISD_Pixel460_OnOff 2;
BA_ "GenSigSendType" SG_ 1364 ICC_RISD_Pixel461_OnOff 2;
BA_ "GenSigSendType" SG_ 1364 ICC_RISD_Pixel462_OnOff 2;
BA_ "GenSigSendType" SG_ 1364 ICC_RISD_Pixel463_OnOff 2;
BA_ "GenSigSendType" SG_ 1364 ICC_RISD_Pixel464_OnOff 2;
BA_ "GenSigSendType" SG_ 1364 ICC_RISD_Pixel465_OnOff 2;
BA_ "GenSigSendType" SG_ 1364 ICC_RISD_Pixel466_OnOff 2;
BA_ "GenSigSendType" SG_ 1364 ICC_RISD_Pixel467_OnOff 2;
BA_ "GenSigSendType" SG_ 1364 ICC_RISD_Pixel468_OnOff 2;
BA_ "GenSigSendType" SG_ 1364 ICC_RISD_Pixel469_OnOff 2;
BA_ "GenSigSendType" SG_ 1364 ICC_RISD_Pixel470_OnOff 2;
BA_ "GenSigSendType" SG_ 1364 ICC_RISD_Pixel471_OnOff 2;
BA_ "GenSigSendType" SG_ 1364 ICC_RISD_Pixel472_OnOff 2;
BA_ "GenSigSendType" SG_ 1364 ICC_RISD_Pixel473_OnOff 2;
BA_ "GenSigSendType" SG_ 1364 ICC_RISD_Pixel474_OnOff 2;
BA_ "GenSigSendType" SG_ 1364 ICC_RISD_Pixel475_OnOff 2;
BA_ "GenSigSendType" SG_ 1364 ICC_RISD_Pixel476_OnOff 2;
BA_ "GenSigSendType" SG_ 1364 ICC_RISD_Pixel477_OnOff 2;
BA_ "GenSigSendType" SG_ 1364 ICC_RISD_Pixel478_OnOff 2;
BA_ "GenSigSendType" SG_ 1364 ICC_RISD_Pixel479_OnOff 2;
BA_ "GenSigSendType" SG_ 1364 ICC_RISD_Pixel480_OnOff 2;
BA_ "GenSigSendType" SG_ 1364 ICC_RISD_Pixel481_OnOff 2;
BA_ "GenSigSendType" SG_ 1364 ICC_RISD_Pixel482_OnOff 2;
BA_ "GenSigSendType" SG_ 1364 ICC_RISD_Pixel483_OnOff 2;
BA_ "GenSigSendType" SG_ 1364 ICC_RISD_Pixel484_OnOff 2;
BA_ "GenSigSendType" SG_ 1364 ICC_RISD_Pixel485_OnOff 2;
BA_ "GenSigSendType" SG_ 1364 ICC_RISD_Pixel486_OnOff 2;
BA_ "GenSigSendType" SG_ 1364 ICC_RISD_Pixel487_OnOff 2;
BA_ "GenSigSendType" SG_ 1364 ICC_RISD_Pixel488_OnOff 2;
BA_ "GenSigSendType" SG_ 1364 ICC_RISD_Pixel489_OnOff 2;
BA_ "GenSigSendType" SG_ 1364 ICC_RISD_Pixel490_OnOff 2;
BA_ "GenSigSendType" SG_ 1364 ICC_RISD_Pixel491_OnOff 2;
BA_ "GenSigSendType" SG_ 1364 ICC_RISD_Pixel492_OnOff 2;
BA_ "GenSigSendType" SG_ 1364 ICC_RISD_Pixel493_OnOff 2;
BA_ "GenSigSendType" SG_ 1364 ICC_RISD_Pixel494_OnOff 2;
BA_ "GenSigSendType" SG_ 1364 ICC_RISD_Pixel495_OnOff 2;
BA_ "GenSigSendType" SG_ 1364 ICC_RISD_Pixel496_OnOff 2;
BA_ "GenSigSendType" SG_ 1364 ICC_RISD_Pixel497_OnOff 2;
BA_ "GenSigSendType" SG_ 1364 ICC_RISD_Pixel498_OnOff 2;
BA_ "GenSigSendType" SG_ 1364 ICC_RISD_Pixel499_OnOff 2;
BA_ "GenSigSendType" SG_ 1364 ICC_RISD_Pixel500_OnOff 2;
BA_ "GenSigSendType" SG_ 1364 ICC_RISD_Pixel501_OnOff 2;
BA_ "GenSigSendType" SG_ 1364 ICC_RISD_Pixel502_OnOff 2;
BA_ "GenSigSendType" SG_ 1364 ICC_RISD_Pixel503_OnOff 2;
BA_ "GenSigSendType" SG_ 1364 ICC_RISD_Pixel504_OnOff 2;
BA_ "GenSigSendType" SG_ 1366 ICC_LKSSettingModSt 2;
BA_ "GenSigSendType" SG_ 1366 ICC_LDWWarnType 2;
BA_ "GenSigSendType" SG_ 1366 ICC_LDWLDPSnvtySet 2;
BA_ "GenSigSendType" SG_ 1366 ICC_ELKSettingSt 2;
BA_ "GenSigSendType" SG_ 1366 ICC_ISLIWarnMod 2;
BA_ "GenSigSendType" SG_ 1366 ICC_AEBSettingSt 2;
BA_ "GenSigSendType" SG_ 1366 ICC_FCWSettingSt 2;
BA_ "GenSigSendType" SG_ 1366 ICC_ICAEnableBtnSts 2;
BA_ "GenSigSendType" SG_ 1366 ICC_Reset 0;
BA_ "GenSigSendType" SG_ 1366 ICC_ACC_SwrsSts 0;
BA_ "GenSigSendType" SG_ 1366 ICC_Customize_buttons 0;
BA_ "GenSigSendType" SG_ 1366 ICC_AVM_TouchEvt 2;
BA_ "GenSigSendType" SG_ 1366 ICC_HMAOnOffSet 0;
BA_ "GenSigInvalidValue" SG_ 1366 ICC_AVM_BtnPressInputValueX 4095;
BA_ "GenSigStartValue" SG_ 1366 ICC_AVM_BtnPressInputValueX 4095;
BA_ "GenSigSendType" SG_ 1366 ICC_AVM_BtnPressInputValueX 2;
BA_ "GenSigInvalidValue" SG_ 1366 ICC_AVM_BtnPressInputValueY 4095;
BA_ "GenSigStartValue" SG_ 1366 ICC_AVM_BtnPressInputValueY 4095;
BA_ "GenSigSendType" SG_ 1366 ICC_AVM_BtnPressInputValueY 2;
BA_ "GenSigSendType" SG_ 1366 ICC_OtaDwnLoad_556h 0;
BA_ "GenSigStartValue" SG_ 1366 ICC_NaviBtnPressInputValX_556h 65535;
BA_ "GenSigInactiveValue" SG_ 1366 ICC_NaviBtnPressInputValX_556h 65535;
BA_ "GenSigSendType" SG_ 1366 ICC_NaviBtnPressInputValX_556h 2;
BA_ "GenSigStartValue" SG_ 1366 ICC_NaviBtnPressInputValY_556h 65535;
BA_ "GenSigInactiveValue" SG_ 1366 ICC_NaviBtnPressInputValY_556h 65535;
BA_ "GenSigSendType" SG_ 1366 ICC_NaviBtnPressInputValY_556h 2;
BA_ "GenSigSendType" SG_ 1366 ICC_RRMDisplay_AVM_APA_556h 2;
BA_ "GenSigSendType" SG_ 1366 ICC_CarMdlSetColor_556h 2;
BA_ "GenSigSendType" SG_ 1366 ICC_AVMActivationSpeedSet_556h 2;
BA_ "GenSigSendType" SG_ 1366 ICC_enum_AESSettingSt_556h 2;
BA_ "GenSigSendType" SG_ 1366 ICC_enum_MAASettingSt_556h 2;
BA_ "GenSigSendType" SG_ 1366 ICC_enum_MEBSettingSt_556h 2;
BA_ "GenSigSendType" SG_ 1366 ICC_DataCollectionSwtSet_556h 2;
BA_ "GenSigSendType" SG_ 1366 ICC_ADS_DAISwtSet_556h 2;
BA_ "GenSigSendType" SG_ 1366 ICC_VoiceplayModeSwtSet_556h 2;
BA_ "GenSigSendType" SG_ 1366 ICC_NOPEnableBtnSts_556h 2;
BA_ "GenSigSendType" SG_ 1366 ICC_ParkFuncUserLearnSts_556h 0;
BA_ "GenSigInvalidValue" SG_ 1366 TimeToStopSentinelMinutSet_556h 63;
BA_ "GenSigStartValue" SG_ 1366 TimeToStopSentinelMinutSet_556h 62;
BA_ "GenSigSendType" SG_ 1366 TimeToStopSentinelMinutSet_556h 2;
BA_ "GenSigSendType" SG_ 1366 ReservationSentinelReq_556h 2;
BA_ "GenSigInvalidValue" SG_ 1366 TimeToStopSentinelHourSet_556h 31;
BA_ "GenSigStartValue" SG_ 1366 TimeToStopSentinelHourSet_556h 30;
BA_ "GenSigSendType" SG_ 1366 TimeToStopSentinelHourSet_556h 2;
BA_ "GenSigSendType" SG_ 1366 SentinelMode_SensitivityReq_556h 0;
BA_ "GenSigInvalidValue" SG_ 1366 TimeToStartSentinelHourSet_556h 31;
BA_ "GenSigStartValue" SG_ 1366 TimeToStartSentinelHourSet_556h 30;
BA_ "GenSigSendType" SG_ 1366 TimeToStartSentinelHourSet_556h 2;
BA_ "GenSigSendType" SG_ 1366 TimeToStartSentinelDaySet_556h 2;
BA_ "GenSigInvalidValue" SG_ 1366 TimeToStartSentinelMinutSet_556h 63;
BA_ "GenSigStartValue" SG_ 1366 TimeToStartSentinelMinutSet_556h 62;
BA_ "GenSigSendType" SG_ 1366 TimeToStartSentinelMinutSet_556h 2;
BA_ "GenSigSendType" SG_ 1366 SentinelModeSwitchReq_556h 2;
BA_ "GenSigSendType" SG_ 1380 ICC_DrvSeatHeatLvlCmd2_564h 2;
BA_ "GenSigSendType" SG_ 1380 ICC_DrvSecSeatHeatLvlCmd2_564h 2;
BA_ "GenSigSendType" SG_ 1380 ICC_DrvSeatVentLvlCmd2_564h 2;
BA_ "GenSigSendType" SG_ 1380 ICC_DrvSecSeatVentLvlCmd2_564h 2;
BA_ "GenSigSendType" SG_ 1380 ICC_FRSeatHeatLvlCmd2 2;
BA_ "GenSigSendType" SG_ 1380 ICC_RRSeatHeatLvlCmd2 2;
BA_ "GenSigSendType" SG_ 1380 ICC_FRSeatVentLvlCmd2 2;
BA_ "GenSigSendType" SG_ 1380 ICC_RRSeatVentLvlCmd2 2;
BA_ "GenSigSendType" SG_ 1380 ICC_FRSeatliedownCmd2 2;
BA_ "GenSigSendType" SG_ 1380 ICC_2nd_FREnjoyableSeatSwitch 2;
BA_ "GenSigSendType" SG_ 1380 ICC_3rd_FLEnjoyableSeatSwitch 2;
BA_ "GenSigSendType" SG_ 1380 ICC_3rd_FLFrontFlipSwitch 2;
BA_ "GenSigSendType" SG_ 1380 ICC_3rd_FREnjoyableSeatSwitch 2;
BA_ "GenSigSendType" SG_ 1380 ICC_3rd_FRFrontFlipSwitch 2;
BA_ "GenSigSendType" SG_ 1380 ICC_QueenSeatSwitch 2;
BA_ "GenSigInvalidValue" SG_ 1380 ICC_2nd_FLSeatLvltargetCmd 127;
BA_ "GenSigSendType" SG_ 1380 ICC_2nd_FLSeatLvltargetCmd 2;
BA_ "GenSigInvalidValue" SG_ 1380 ICC_2nd_FLSeatBackAgtargetCmd 127;
BA_ "GenSigSendType" SG_ 1380 ICC_2nd_FLSeatBackAgtargetCmd 2;
BA_ "GenSigInvalidValue" SG_ 1380 ICC_2nd_FRSeatLvltargetCmd 127;
BA_ "GenSigSendType" SG_ 1380 ICC_2nd_FRSeatLvltargetCmd 2;
BA_ "GenSigInvalidValue" SG_ 1380 ICC_2nd_FRSeatBackAgtargetCmd 127;
BA_ "GenSigSendType" SG_ 1380 ICC_2nd_FRSeatBackAgtargetCmd 2;
BA_ "GenSigInvalidValue" SG_ 1380 ICC_2nd_FRSeatLegSpprttargetCmd 127;
BA_ "GenSigSendType" SG_ 1380 ICC_2nd_FRSeatLegSpprttargetCmd 2;
BA_ "GenSigInvalidValue" SG_ 1380 ICC_3rd_FLSeatBackAgtargetCmd 127;
BA_ "GenSigSendType" SG_ 1380 ICC_3rd_FLSeatBackAgtargetCmd 2;
BA_ "GenSigInvalidValue" SG_ 1380 ICC_3rd_FRSeatBackAgtargetCmd 127;
BA_ "GenSigSendType" SG_ 1380 ICC_3rd_FRSeatBackAgtargetCmd 2;
BA_ "GenSigSendType" SG_ 1380 ICC_SetAVASFuntion_564h 2;
BA_ "GenSigSendType" SG_ 1380 ICC_AutoSeatHeatLevelCmd_564h 2;
BA_ "GenSigSendType" SG_ 1380 ICC_AutoSteerWhlHeatCmd_564h 2;
BA_ "GenSigSendType" SG_ 1380 ICC_AutoSeatVentLevelCmd_564h 2;
BA_ "GenSigSendType" SG_ 1394 AVAS_CRC1_572h 0;
BA_ "GenSigSendType" SG_ 1394 AVAS_RollgCntr1_572h 0;
BA_ "GenSigSendType" SG_ 1394 AVAS_FunctionSts_572h 0;
BA_ "GenSigInvalidValue" SG_ 1395 ICC_VINcode_10 255;
BA_ "GenSigSendType" SG_ 1395 ICC_VINcode_10 0;
BA_ "GenSigInvalidValue" SG_ 1395 ICC_VINcode_11 255;
BA_ "GenSigSendType" SG_ 1395 ICC_VINcode_11 0;
BA_ "GenSigInvalidValue" SG_ 1395 ICC_VINcode_12 255;
BA_ "GenSigSendType" SG_ 1395 ICC_VINcode_12 0;
BA_ "GenSigInvalidValue" SG_ 1395 ICC_VINcode_13 255;
BA_ "GenSigSendType" SG_ 1395 ICC_VINcode_13 0;
BA_ "GenSigInvalidValue" SG_ 1395 ICC_VINcode_14 255;
BA_ "GenSigSendType" SG_ 1395 ICC_VINcode_14 0;
BA_ "GenSigInvalidValue" SG_ 1395 ICC_VINcode_15 255;
BA_ "GenSigSendType" SG_ 1395 ICC_VINcode_15 0;
BA_ "GenSigInvalidValue" SG_ 1395 ICC_VINcode_16 255;
BA_ "GenSigSendType" SG_ 1395 ICC_VINcode_16 0;
BA_ "GenSigInvalidValue" SG_ 1395 ICC_VINcode_17 255;
BA_ "GenSigSendType" SG_ 1395 ICC_VINcode_17 0;
BA_ "GenSigInvalidValue" SG_ 1399 ICC_CLTC_RangeAval 1023;
BA_ "GenSigSendType" SG_ 1399 ICC_CLTC_RangeAval 0;
BA_ "GenSigInvalidValue" SG_ 1399 ICC_DynamicRangeAval 1023;
BA_ "GenSigSendType" SG_ 1399 ICC_DynamicRangeAval 0;
BA_ "GenSigInvalidValue" SG_ 1399 ICC_WLTC_RangeAval 1023;
BA_ "GenSigSendType" SG_ 1399 ICC_WLTC_RangeAval 0;
BA_ "GenSigInvalidValue" SG_ 1399 ICC_CLTC_RangeAvalFuel 4095;
BA_ "GenSigSendType" SG_ 1399 ICC_CLTC_RangeAvalFuel 0;
BA_ "GenSigInvalidValue" SG_ 1399 ICC_WLTC_RangeAvalFuel 4095;
BA_ "GenSigSendType" SG_ 1399 ICC_WLTC_RangeAvalFuel 0;
BA_ "GenSigInvalidValue" SG_ 1399 ICC_DynamicRangeAvalFuel 4095;
BA_ "GenSigSendType" SG_ 1399 ICC_DynamicRangeAvalFuel 0;
BA_ "GenSigInvalidValue" SG_ 1399 ICC_CLTC_RangeAvalComp 4095;
BA_ "GenSigSendType" SG_ 1399 ICC_CLTC_RangeAvalComp 0;
BA_ "GenSigInvalidValue" SG_ 1399 ICC_WLTC_RangeAvalComp 4095;
BA_ "GenSigSendType" SG_ 1399 ICC_WLTC_RangeAvalComp 0;
BA_ "GenSigInvalidValue" SG_ 1399 ICC_DynamicRangeAvalComp 4095;
BA_ "GenSigSendType" SG_ 1399 ICC_DynamicRangeAvalComp 0;
BA_ "GenSigSendType" SG_ 1399 ICC_Conditiontype 0;
BA_ "GenSigInvalidValue" SG_ 1399 SailOdoMeter_577h 255;
BA_ "GenSigSendType" SG_ 1399 SailOdoMeter_577h 0;
BA_ "GenSigInvalidValue" SG_ 1399 TotalSailOdoMeterBackUp_577h 65535;
BA_ "GenSigSendType" SG_ 1399 TotalSailOdoMeterBackUp_577h 0;
BA_ "GenSigInvalidValue" SG_ 1399 ICC_SailremainingTime_577h 255;
BA_ "GenSigSendType" SG_ 1399 ICC_SailremainingTime_577h 0;
BA_ "GenSigSendType" SG_ 1399 MaintenanceOdometer_Valid_577h 0;
BA_ "GenSigSendType" SG_ 1399 MaintenanceOdometer_BkpEn_577h 0;
BA_ "GenSigInvalidValue" SG_ 1399 MaintenanceOdometer_577h 16777215;
BA_ "GenSigSendType" SG_ 1399 MaintenanceOdometer_577h 0;
BA_ "GenSigSendType" SG_ 1403 RMCU_ErrLvlDis 0;
BA_ "GenSigInvalidValue" SG_ 1403 RMCU_Speed_EDR 65535;
BA_ "GenSigSendType" SG_ 1403 RMCU_Speed_EDR 0;
BA_ "GenSigInvalidValue" SG_ 1409 FLZCU_Totalodometerbackup 16777215;
BA_ "GenSigSendType" SG_ 1409 FLZCU_Totalodometerbackup 0;
BA_ "GenSigInvalidValue" SG_ 1409 FLZCU_EVodometerbackup 16777215;
BA_ "GenSigSendType" SG_ 1409 FLZCU_EVodometerbackup 0;
BA_ "GenSigSendType" SG_ 1417 HCU_RangCnsDispThisTrip_589h 0;
BA_ "GenSigInvalidValue" SG_ 1417 HCU_ElecCnsAvgThisTrip_589h 4095;
BA_ "GenSigSendType" SG_ 1417 HCU_ElecCnsAvgThisTrip_589h 0;
BA_ "GenSigSendType" SG_ 1417 HCU_ACRangCnsThisTrip_589h 0;
BA_ "GenSigSendType" SG_ 1417 HCU_AuxRangCnsThisTrip_589h 0;
BA_ "GenSigSendType" SG_ 1417 HCU_RgnRangBiasThisTrip_589h 0;
BA_ "GenSigSendType" SG_ 1417 HCU_RangCnsDispAfChrg_589h 0;
BA_ "GenSigSendType" SG_ 1417 HCU_ACRangCnsAfChrg_589h 0;
BA_ "GenSigSendType" SG_ 1417 HCU_AuxRangCnsAfChrg_589h 0;
BA_ "GenSigSendType" SG_ 1417 HCU_RgnRangBiasAfChrg_589h 0;
BA_ "GenSigSendType" SG_ 1417 HCU_RangCnsDispAfRst_589h 0;
BA_ "GenSigSendType" SG_ 1417 HCU_ACRangCnsAfRst_589h 0;
BA_ "GenSigSendType" SG_ 1417 HCU_AuxRangCnsAfRst_589h 0;
BA_ "GenSigSendType" SG_ 1417 HCU_RgnRangBiasAfRst_589h 0;
BA_ "GenSigSendType" SG_ 1417 HCU_stCleverDisReason_589h 0;
BA_ "GenSigInvalidValue" SG_ 1419 ICM_AverageFuelConsume_A_58Bh 511;
BA_ "GenSigSendType" SG_ 1419 ICM_AverageFuelConsume_A_58Bh 0;
BA_ "GenSigSendType" SG_ 1419 ICM_EngineOil_LiquidLow_58Bh 0;
BA_ "GenSigInvalidValue" SG_ 1419 ICM_AverageFuelConsume_B_58Bh 511;
BA_ "GenSigSendType" SG_ 1419 ICM_AverageFuelConsume_B_58Bh 0;
BA_ "GenSigSendType" SG_ 1419 ICM_BrakeFluidSts_58Bh 0;
BA_ "GenSigInvalidValue" SG_ 1419 ICM_AverageVehicleSpeed_A_58Bh 511;
BA_ "GenSigSendType" SG_ 1419 ICM_AverageVehicleSpeed_A_58Bh 0;
BA_ "GenSigInvalidValue" SG_ 1419 ICM_Maintenance_tips_58Bh 32767;
BA_ "GenSigSendType" SG_ 1419 ICM_Maintenance_tips_58Bh 0;
BA_ "GenSigInvalidValue" SG_ 1419 ICM_DrivingTime_A_58Bh 16383;
BA_ "GenSigSendType" SG_ 1419 ICM_DrivingTime_A_58Bh 0;
BA_ "GenSigInvalidValue" SG_ 1419 ICM_DrivingTime_B_58Bh 16383;
BA_ "GenSigSendType" SG_ 1419 ICM_DrivingTime_B_58Bh 0;
BA_ "GenSigInvalidValue" SG_ 1419 TotalOdometer_km_TRIPOBD_58Bh 16777215;
BA_ "GenSigSendType" SG_ 1419 TotalOdometer_km_TRIPOBD_58Bh 0;
BA_ "GenSigStartValue" SG_ 1427 ILCF_1_LogoParkingSts 1;
BA_ "GenSigSendType" SG_ 1427 ILCF_1_LogoParkingSts 0;
BA_ "GenSigSendType" SG_ 1427 ILCF_1_DIYMusicShowModSts 0;
BA_ "GenSigSendType" SG_ 1427 ILCF_1_RandomMusicShowSts 0;
BA_ "GenSigStartValue" SG_ 1427 ILCF_1_LogoColorAdjSts 117;
BA_ "GenSigSendType" SG_ 1427 ILCF_1_LogoColorAdjSts 0;
BA_ "GenSigInvalidValue" SG_ 1429 FLZCU_VINcode_10 255;
BA_ "GenSigSendType" SG_ 1429 FLZCU_VINcode_10 0;
BA_ "GenSigInvalidValue" SG_ 1429 FLZCU_VINcode_11 255;
BA_ "GenSigSendType" SG_ 1429 FLZCU_VINcode_11 0;
BA_ "GenSigInvalidValue" SG_ 1429 FLZCU_VINcode_12 255;
BA_ "GenSigSendType" SG_ 1429 FLZCU_VINcode_12 0;
BA_ "GenSigInvalidValue" SG_ 1429 FLZCU_VINcode_13 255;
BA_ "GenSigSendType" SG_ 1429 FLZCU_VINcode_13 0;
BA_ "GenSigInvalidValue" SG_ 1429 FLZCU_VINcode_14 255;
BA_ "GenSigSendType" SG_ 1429 FLZCU_VINcode_14 0;
BA_ "GenSigInvalidValue" SG_ 1429 FLZCU_VINcode_15 255;
BA_ "GenSigSendType" SG_ 1429 FLZCU_VINcode_15 0;
BA_ "GenSigInvalidValue" SG_ 1429 FLZCU_VINcode_16 255;
BA_ "GenSigSendType" SG_ 1429 FLZCU_VINcode_16 0;
BA_ "GenSigInvalidValue" SG_ 1429 FLZCU_VINcode_17 255;
BA_ "GenSigSendType" SG_ 1429 FLZCU_VINcode_17 0;
BA_ "GenSigSendType" SG_ 1445 HCU_SumFuCnsThisTrip 0;
BA_ "GenSigSendType" SG_ 1445 HCU_SumElecCnsThisTrip 0;
BA_ "GenSigSendType" SG_ 1445 HCU_SumEgyCnsThisTrip 0;
BA_ "GenSigSendType" SG_ 1446 ICC_WiFiSSID_Char1_5A6h 0;
BA_ "GenSigSendType" SG_ 1446 ICC_WiFiSSID_Char2_5A6h 0;
BA_ "GenSigSendType" SG_ 1446 ICC_WiFiSSID_Char3_5A6h 0;
BA_ "GenSigSendType" SG_ 1446 ICC_WiFiSSID_Char4_5A6h 0;
BA_ "GenSigSendType" SG_ 1446 ICC_WiFiSSID_Char5_5A6h 0;
BA_ "GenSigSendType" SG_ 1446 ICC_WiFiSSID_Char6_5A6h 0;
BA_ "GenSigSendType" SG_ 1446 ICC_WiFiSSID_Char7_5A6h 0;
BA_ "GenSigSendType" SG_ 1446 ICC_WiFiSSID_Char8_5A6h 0;
BA_ "GenSigSendType" SG_ 1447 CurrentTimeYear_UTC 0;
BA_ "GenSigStartValue" SG_ 1447 CurrentTimeMonth_UTC 1;
BA_ "GenSigSendType" SG_ 1447 CurrentTimeMonth_UTC 0;
BA_ "GenSigStartValue" SG_ 1447 CurrentTimeDay_UTC 1;
BA_ "GenSigSendType" SG_ 1447 CurrentTimeDay_UTC 0;
BA_ "GenSigSendType" SG_ 1447 CurrentTimeHour_UTC 0;
BA_ "GenSigSendType" SG_ 1447 CurrentTimeMinute_UTC 0;
BA_ "GenSigSendType" SG_ 1447 CurrentTimeSecond_UTC 0;
BA_ "GenSigSendType" SG_ 1450 ICC_WiFiAWD_Char1_5AAh 0;
BA_ "GenSigSendType" SG_ 1450 ICC_WiFiAWD_Char2_5AAh 0;
BA_ "GenSigSendType" SG_ 1450 ICC_WiFiAWD_Char3_5AAh 0;
BA_ "GenSigSendType" SG_ 1450 ICC_WiFiAWD_Char4_5AAh 0;
BA_ "GenSigSendType" SG_ 1450 ICC_WiFiAWD_Char5_5AAh 0;
BA_ "GenSigSendType" SG_ 1450 ICC_WiFiAWD_Char6_5AAh 0;
BA_ "GenSigSendType" SG_ 1450 ICC_WiFiAWD_Char7_5AAh 0;
BA_ "GenSigSendType" SG_ 1450 ICC_WiFiAWD_Char8_5AAh 0;
BA_ "GenSigInvalidValue" SG_ 1451 SBOX_GNSS_ANT_State 3;
BA_ "GenSigSendType" SG_ 1451 SBOX_GNSS_ANT_State 0;
BA_ "GenSigInvalidValue" SG_ 1451 SBOX_SIM_State 3;
BA_ "GenSigSendType" SG_ 1451 SBOX_SIM_State 0;
BA_ "GenSigInvalidValue" SG_ 1451 SBOX_BT_State 3;
BA_ "GenSigSendType" SG_ 1451 SBOX_BT_State 0;
BA_ "GenSigInvalidValue" SG_ 1451 SBOX_TT_State 3;
BA_ "GenSigSendType" SG_ 1451 SBOX_TT_State 0;
BA_ "GenSigInvalidValue" SG_ 1451 SBOX_TT_ANT_State 3;
BA_ "GenSigSendType" SG_ 1451 SBOX_TT_ANT_State 0;
BA_ "GenSigInvalidValue" SG_ 1451 SBOX_BatterState 3;
BA_ "GenSigSendType" SG_ 1451 SBOX_BatterState 0;
BA_ "GenSigInvalidValue" SG_ 1451 SBOX_PowerState 3;
BA_ "GenSigSendType" SG_ 1451 SBOX_PowerState 0;
BA_ "GenSigSendType" SG_ 1451 SBOX_SimActivation 0;
BA_ "GenSigSendType" SG_ 1451 SBOX_TspActivation 0;
BA_ "GenSigSendType" SG_ 1451 SBOX_SatelliteStatus 0;
BA_ "GenSigSendType" SG_ 1451 SBOX_BtConState 0;
BA_ "GenSigSendType" SG_ 1451 SBOX_SelfCheck 0;
BA_ "GenSigSendType" SG_ 1451 SBOX_SatelliteSignalValue 0;
BA_ "GenSigStartValue" SG_ 1451 SBOX_BatTemp 255;
BA_ "GenSigSendType" SG_ 1451 SBOX_BatTemp 0;
BA_ "GenSigSendType" SG_ 1451 SBOX_TimeSpentOnline 0;
BA_ "GenSigSendType" SG_ 1451 SBOX_RunTime 0;
BA_ "GenSigSendType" SG_ 1451 SBOX_EcallState 0;
BA_ "GenSigSendType" SG_ 1453 ICC_MemAttributeFR 0;
BA_ "GenSigSendType" SG_ 1453 ICC_MemAttributeFL 0;
BA_ "GenSigSendType" SG_ 1453 ICC_MemAttributeRR 0;
BA_ "GenSigSendType" SG_ 1453 ICC_MemAttributeRL 0;
BA_ "GenSigSendType" SG_ 1453 ICC_CrossBorderMode 0;
BA_ "GenSigSendType" SG_ 1453 ICC_BedStatus 0;
BA_ "GenSigInvalidValue" SG_ 1531 BMS_HvBattSoeActDisChaCyc 65535;
BA_ "GenSigStartValue" SG_ 1531 BMS_HvBattSoeActDisChaCyc 65535;
BA_ "GenSigSendType" SG_ 1531 BMS_HvBattSoeActDisChaCyc 0;
BA_ "GenSigInvalidValue" SG_ 1531 BMS_HvBattSoeActReChaCyc 65535;
BA_ "GenSigStartValue" SG_ 1531 BMS_HvBattSoeActReChaCyc 65535;
BA_ "GenSigSendType" SG_ 1531 BMS_HvBattSoeActReChaCyc 0;
BA_ "GenSigInvalidValue" SG_ 1531 BMS_HvBattRatedEnergy 16383;
BA_ "GenSigStartValue" SG_ 1531 BMS_HvBattRatedEnergy 16382;
BA_ "GenSigSendType" SG_ 1531 BMS_HvBattRatedEnergy 0;
BA_ "GenSigInvalidValue" SG_ 1531 BMS_HvBattRatedU 16383;
BA_ "GenSigStartValue" SG_ 1531 BMS_HvBattRatedU 16382;
BA_ "GenSigSendType" SG_ 1531 BMS_HvBattRatedU 0;
BA_ "GenSigStartValue" SG_ 1531 BMS_HvBattTypeCode 255;
BA_ "GenSigSendType" SG_ 1531 BMS_HvBattTypeCode 0;
BA_ "GenSigInvalidValue" SG_ 1531 BMS_HvBattManufcCode 4294967295;
BA_ "GenSigSendType" SG_ 1531 BMS_HvBattManufcCode 0;
BA_ "GenSigInvalidValue" SG_ 1531 BMS_HvBattTempSensorTotalNum 65535;
BA_ "GenSigStartValue" SG_ 1531 BMS_HvBattTempSensorTotalNum 65535;
BA_ "GenSigSendType" SG_ 1531 BMS_HvBattTempSensorTotalNum 0;
BA_ "GenSigInvalidValue" SG_ 1531 BMS_HvBattTempSensorTempMaxNum 255;
BA_ "GenSigStartValue" SG_ 1531 BMS_HvBattTempSensorTempMaxNum 255;
BA_ "GenSigSendType" SG_ 1531 BMS_HvBattTempSensorTempMaxNum 0;
BA_ "GenSigInvalidValue" SG_ 1531 BMS_HvBattTempSensorTempMinNum 255;
BA_ "GenSigStartValue" SG_ 1531 BMS_HvBattTempSensorTempMinNum 255;
BA_ "GenSigSendType" SG_ 1531 BMS_HvBattTempSensorTempMinNum 0;
BA_ "GenSigInvalidValue" SG_ 1531 BMS_HvBattTempMaxNum 255;
BA_ "GenSigStartValue" SG_ 1531 BMS_HvBattTempMaxNum 255;
BA_ "GenSigSendType" SG_ 1531 BMS_HvBattTempMaxNum 0;
BA_ "GenSigInvalidValue" SG_ 1531 BMS_HvBattTempMinNum 255;
BA_ "GenSigStartValue" SG_ 1531 BMS_HvBattTempMinNum 255;
BA_ "GenSigSendType" SG_ 1531 BMS_HvBattTempMinNum 0;
BA_ "GenSigInvalidValue" SG_ 1531 BMS_BattCellTotalNum 65535;
BA_ "GenSigStartValue" SG_ 1531 BMS_BattCellTotalNum 65535;
BA_ "GenSigSendType" SG_ 1531 BMS_BattCellTotalNum 0;
BA_ "GenSigInvalidValue" SG_ 1531 BMS_HvBattVoltMaxNum 255;
BA_ "GenSigStartValue" SG_ 1531 BMS_HvBattVoltMaxNum 255;
BA_ "GenSigSendType" SG_ 1531 BMS_HvBattVoltMaxNum 0;
BA_ "GenSigInvalidValue" SG_ 1531 BMS_HvBattVoltMinNum 255;
BA_ "GenSigStartValue" SG_ 1531 BMS_HvBattVoltMinNum 255;
BA_ "GenSigSendType" SG_ 1531 BMS_HvBattVoltMinNum 0;
BA_ "GenSigInvalidValue" SG_ 1531 BMS_ActualSOCMin 4095;
BA_ "GenSigStartValue" SG_ 1531 BMS_ActualSOCMin 4095;
BA_ "GenSigSendType" SG_ 1531 BMS_ActualSOCMin 0;
BA_ "GenSigInvalidValue" SG_ 1531 BMS_ActualSOCMax 4095;
BA_ "GenSigStartValue" SG_ 1531 BMS_ActualSOCMax 4095;
BA_ "GenSigSendType" SG_ 1531 BMS_ActualSOCMax 0;
BA_ "GenSigStartValue" SG_ 1560 srcNodeID_ICC 24;
BA_ "GenSigSendType" SG_ 1560 srcNodeID_ICC 0;
BA_ "GenSigSendType" SG_ 1560 RMR_ICC 0;
BA_ "GenSigSendType" SG_ 1560 NMm_ICC_Reserved1 0;
BA_ "GenSigSendType" SG_ 1560 ICC_Wakeup_Poweron 0;
BA_ "GenSigSendType" SG_ 1560 ICC_Wakeup_NM 0;
BA_ "GenSigSendType" SG_ 1560 ICC_Wakeup_Diag 0;
BA_ "GenSigSendType" SG_ 1560 ICC_Wakeup_PowerComfortable 0;
BA_ "GenSigSendType" SG_ 1560 ICC_Wakeup_HUD 0;
BA_ "GenSigSendType" SG_ 1560 ICC_Wakeup_EAMP 0;
BA_ "GenSigSendType" SG_ 1560 ICC_Awake_Poweron 0;
BA_ "GenSigSendType" SG_ 1560 ICC_Awake_NM 0;
BA_ "GenSigSendType" SG_ 1560 ICC_Awake_Diag 0;
BA_ "GenSigSendType" SG_ 1560 ICC_Awake_PowerComfortable 0;
BA_ "GenSigSendType" SG_ 1560 ICC_Awake_SentinelMode 0;
BA_ "GenSigSendType" SG_ 1560 ICC_Awake_PetMode 0;
BA_ "GenSigSendType" SG_ 1560 ICC_Awake_HUD 0;
BA_ "GenSigSendType" SG_ 1560 ICC_Awake_EAMP 0;
BA_ "GenSigSendType" SG_ 1560 ICC_Awake_FreezerFunction 0;
BA_ "GenSigSendType" SG_ 1560 ICC_Awake_PowerOffDelay 0;
BA_ "GenSigSendType" SG_ 1560 ICC_Awake_VehLockDwnLoad_618h 0;
VAL_ 1364 ICC_RISD_FrameCounter 0 "FrameCounter 0" 1 "FrameCounter 1" 2 "FrameCounter 2" 3 "FrameCounter 3" ;
VAL_ 1364 ICC_RISD_RollingCounter 0 "Counter 0" 1 "Counter 1" 2 "Counter 2" ;
VAL_ 1364 ICC_RISD_Pixel1_OnOff 0 "Pixel On" 1 "Pixel Off" ;
VAL_ 1364 ICC_RISD_Pixel2_OnOff 0 "Pixel On" 1 "Pixel Off" ;
VAL_ 1364 ICC_RISD_Pixel3_OnOff 0 "Pixel On" 1 "Pixel Off" ;
VAL_ 1364 ICC_RISD_Pixel4_OnOff 0 "Pixel On" 1 "Pixel Off" ;
VAL_ 1364 ICC_RISD_Pixel5_OnOff 0 "Pixel On" 1 "Pixel Off" ;
VAL_ 1364 ICC_RISD_Pixel6_OnOff 0 "Pixel On" 1 "Pixel Off" ;
VAL_ 1364 ICC_RISD_Pixel7_OnOff 0 "Pixel On" 1 "Pixel Off" ;
VAL_ 1364 ICC_RISD_Pixel8_OnOff 0 "Pixel On" 1 "Pixel Off" ;
VAL_ 1364 ICC_RISD_Pixel9_OnOff 0 "Pixel On" 1 "Pixel Off" ;
VAL_ 1364 ICC_RISD_Pixel10_OnOff 0 "Pixel On" 1 "Pixel Off" ;
VAL_ 1364 ICC_RISD_Pixel11_OnOff 0 "Pixel On" 1 "Pixel Off" ;
VAL_ 1364 ICC_RISD_Pixel12_OnOff 0 "Pixel On" 1 "Pixel Off" ;
VAL_ 1364 ICC_RISD_Pixel13_OnOff 0 "Pixel On" 1 "Pixel Off" ;
VAL_ 1364 ICC_RISD_Pixel14_OnOff 0 "Pixel On" 1 "Pixel Off" ;
VAL_ 1364 ICC_RISD_Pixel15_OnOff 0 "Pixel On" 1 "Pixel Off" ;
VAL_ 1364 ICC_RISD_Pixel16_OnOff 0 "Pixel On" 1 "Pixel Off" ;
VAL_ 1364 ICC_RISD_Pixel17_OnOff 0 "Pixel On" 1 "Pixel Off" ;
VAL_ 1364 ICC_RISD_Pixel18_OnOff 0 "Pixel On" 1 "Pixel Off" ;
VAL_ 1364 ICC_RISD_Pixel19_OnOff 0 "Pixel On" 1 "Pixel Off" ;
VAL_ 1364 ICC_RISD_Pixel20_OnOff 0 "Pixel On" 1 "Pixel Off" ;
VAL_ 1364 ICC_RISD_Pixel21_OnOff 0 "Pixel On" 1 "Pixel Off" ;
VAL_ 1364 ICC_RISD_Pixel22_OnOff 0 "Pixel On" 1 "Pixel Off" ;
VAL_ 1364 ICC_RISD_Pixel23_OnOff 0 "Pixel On" 1 "Pixel Off" ;
VAL_ 1364 ICC_RISD_Pixel24_OnOff 0 "Pixel On" 1 "Pixel Off" ;
VAL_ 1364 ICC_RISD_Pixel25_OnOff 0 "Pixel On" 1 "Pixel Off" ;
VAL_ 1364 ICC_RISD_Pixel26_OnOff 0 "Pixel On" 1 "Pixel Off" ;
VAL_ 1364 ICC_RISD_Pixel27_OnOff 0 "Pixel On" 1 "Pixel Off" ;
VAL_ 1364 ICC_RISD_Pixel28_OnOff 0 "Pixel On" 1 "Pixel Off" ;
VAL_ 1364 ICC_RISD_Pixel29_OnOff 0 "Pixel On" 1 "Pixel Off" ;
VAL_ 1364 ICC_RISD_Pixel30_OnOff 0 "Pixel On" 1 "Pixel Off" ;
VAL_ 1364 ICC_RISD_Pixel31_OnOff 0 "Pixel On" 1 "Pixel Off" ;
VAL_ 1364 ICC_RISD_Pixel32_OnOff 0 "Pixel On" 1 "Pixel Off" ;
VAL_ 1364 ICC_RISD_Pixel33_OnOff 0 "Pixel On" 1 "Pixel Off" ;
VAL_ 1364 ICC_RISD_Pixel34_OnOff 0 "Pixel On" 1 "Pixel Off" ;
VAL_ 1364 ICC_RISD_Pixel35_OnOff 0 "Pixel On" 1 "Pixel Off" ;
VAL_ 1364 ICC_RISD_Pixel36_OnOff 0 "Pixel On" 1 "Pixel Off" ;
VAL_ 1364 ICC_RISD_Pixel37_OnOff 0 "Pixel On" 1 "Pixel Off" ;
VAL_ 1364 ICC_RISD_Pixel38_OnOff 0 "Pixel On" 1 "Pixel Off" ;
VAL_ 1364 ICC_RISD_Pixel39_OnOff 0 "Pixel On" 1 "Pixel Off" ;
VAL_ 1364 ICC_RISD_Pixel40_OnOff 0 "Pixel On" 1 "Pixel Off" ;
VAL_ 1364 ICC_RISD_Pixel41_OnOff 0 "Pixel On" 1 "Pixel Off" ;
VAL_ 1364 ICC_RISD_Pixel42_OnOff 0 "Pixel On" 1 "Pixel Off" ;
VAL_ 1364 ICC_RISD_Pixel43_OnOff 0 "Pixel On" 1 "Pixel Off" ;
VAL_ 1364 ICC_RISD_Pixel44_OnOff 0 "Pixel On" 1 "Pixel Off" ;
VAL_ 1364 ICC_RISD_Pixel45_OnOff 0 "Pixel On" 1 "Pixel Off" ;
VAL_ 1364 ICC_RISD_Pixel46_OnOff 0 "Pixel On" 1 "Pixel Off" ;
VAL_ 1364 ICC_RISD_Pixel47_OnOff 0 "Pixel On" 1 "Pixel Off" ;
VAL_ 1364 ICC_RISD_Pixel48_OnOff 0 "Pixel On" 1 "Pixel Off" ;
VAL_ 1364 ICC_RISD_Pixel49_OnOff 0 "Pixel On" 1 "Pixel Off" ;
VAL_ 1364 ICC_RISD_Pixel50_OnOff 0 "Pixel On" 1 "Pixel Off" ;
VAL_ 1364 ICC_RISD_Pixel51_OnOff 0 "Pixel On" 1 "Pixel Off" ;
VAL_ 1364 ICC_RISD_Pixel52_OnOff 0 "Pixel On" 1 "Pixel Off" ;
VAL_ 1364 ICC_RISD_Pixel53_OnOff 0 "Pixel On" 1 "Pixel Off" ;
VAL_ 1364 ICC_RISD_Pixel54_OnOff 0 "Pixel On" 1 "Pixel Off" ;
VAL_ 1364 ICC_RISD_Pixel55_OnOff 0 "Pixel On" 1 "Pixel Off" ;
VAL_ 1364 ICC_RISD_Pixel56_OnOff 0 "Pixel On" 1 "Pixel Off" ;
VAL_ 1364 ICC_RISD_Pixel57_OnOff 0 "Pixel On" 1 "Pixel Off" ;
VAL_ 1364 ICC_RISD_Pixel58_OnOff 0 "Pixel On" 1 "Pixel Off" ;
VAL_ 1364 ICC_RISD_Pixel59_OnOff 0 "Pixel On" 1 "Pixel Off" ;
VAL_ 1364 ICC_RISD_Pixel60_OnOff 0 "Pixel On" 1 "Pixel Off" ;
VAL_ 1364 ICC_RISD_Pixel61_OnOff 0 "Pixel On" 1 "Pixel Off" ;
VAL_ 1364 ICC_RISD_Pixel62_OnOff 0 "Pixel On" 1 "Pixel Off" ;
VAL_ 1364 ICC_RISD_Pixel63_OnOff 0 "Pixel On" 1 "Pixel Off" ;
VAL_ 1364 ICC_RISD_Pixel64_OnOff 0 "Pixel On" 1 "Pixel Off" ;
VAL_ 1364 ICC_RISD_Pixel65_OnOff 0 "Pixel On" 1 "Pixel Off" ;
VAL_ 1364 ICC_RISD_Pixel66_OnOff 0 "Pixel On" 1 "Pixel Off" ;
VAL_ 1364 ICC_RISD_Pixel67_OnOff 0 "Pixel On" 1 "Pixel Off" ;
VAL_ 1364 ICC_RISD_Pixel68_OnOff 0 "Pixel On" 1 "Pixel Off" ;
VAL_ 1364 ICC_RISD_Pixel69_OnOff 0 "Pixel On" 1 "Pixel Off" ;
VAL_ 1364 ICC_RISD_Pixel70_OnOff 0 "Pixel On" 1 "Pixel Off" ;
VAL_ 1364 ICC_RISD_Pixel71_OnOff 0 "Pixel On" 1 "Pixel Off" ;
VAL_ 1364 ICC_RISD_Pixel72_OnOff 0 "Pixel On" 1 "Pixel Off" ;
VAL_ 1364 ICC_RISD_Pixel73_OnOff 0 "Pixel On" 1 "Pixel Off" ;
VAL_ 1364 ICC_RISD_Pixel74_OnOff 0 "Pixel On" 1 "Pixel Off" ;
VAL_ 1364 ICC_RISD_Pixel75_OnOff 0 "Pixel On" 1 "Pixel Off" ;
VAL_ 1364 ICC_RISD_Pixel76_OnOff 0 "Pixel On" 1 "Pixel Off" ;
VAL_ 1364 ICC_RISD_Pixel77_OnOff 0 "Pixel On" 1 "Pixel Off" ;
VAL_ 1364 ICC_RISD_Pixel78_OnOff 0 "Pixel On" 1 "Pixel Off" ;
VAL_ 1364 ICC_RISD_Pixel79_OnOff 0 "Pixel On" 1 "Pixel Off" ;
VAL_ 1364 ICC_RISD_Pixel80_OnOff 0 "Pixel On" 1 "Pixel Off" ;
VAL_ 1364 ICC_RISD_Pixel81_OnOff 0 "Pixel On" 1 "Pixel Off" ;
VAL_ 1364 ICC_RISD_Pixel82_OnOff 0 "Pixel On" 1 "Pixel Off" ;
VAL_ 1364 ICC_RISD_Pixel83_OnOff 0 "Pixel On" 1 "Pixel Off" ;
VAL_ 1364 ICC_RISD_Pixel84_OnOff 0 "Pixel On" 1 "Pixel Off" ;
VAL_ 1364 ICC_RISD_Pixel85_OnOff 0 "Pixel On" 1 "Pixel Off" ;
VAL_ 1364 ICC_RISD_Pixel86_OnOff 0 "Pixel On" 1 "Pixel Off" ;
VAL_ 1364 ICC_RISD_Pixel87_OnOff 0 "Pixel On" 1 "Pixel Off" ;
VAL_ 1364 ICC_RISD_Pixel88_OnOff 0 "Pixel On" 1 "Pixel Off" ;
VAL_ 1364 ICC_RISD_Pixel89_OnOff 0 "Pixel On" 1 "Pixel Off" ;
VAL_ 1364 ICC_RISD_Pixel90_OnOff 0 "Pixel On" 1 "Pixel Off" ;
VAL_ 1364 ICC_RISD_Pixel91_OnOff 0 "Pixel On" 1 "Pixel Off" ;
VAL_ 1364 ICC_RISD_Pixel92_OnOff 0 "Pixel On" 1 "Pixel Off" ;
VAL_ 1364 ICC_RISD_Pixel93_OnOff 0 "Pixel On" 1 "Pixel Off" ;
VAL_ 1364 ICC_RISD_Pixel94_OnOff 0 "Pixel On" 1 "Pixel Off" ;
VAL_ 1364 ICC_RISD_Pixel95_OnOff 0 "Pixel On" 1 "Pixel Off" ;
VAL_ 1364 ICC_RISD_Pixel96_OnOff 0 "Pixel On" 1 "Pixel Off" ;
VAL_ 1364 ICC_RISD_Pixel97_OnOff 0 "Pixel On" 1 "Pixel Off" ;
VAL_ 1364 ICC_RISD_Pixel98_OnOff 0 "Pixel On" 1 "Pixel Off" ;
VAL_ 1364 ICC_RISD_Pixel99_OnOff 0 "Pixel On" 1 "Pixel Off" ;
VAL_ 1364 ICC_RISD_Pixel100_OnOff 0 "Pixel On" 1 "Pixel Off" ;
VAL_ 1364 ICC_RISD_Pixel101_OnOff 0 "Pixel On" 1 "Pixel Off" ;
VAL_ 1364 ICC_RISD_Pixel102_OnOff 0 "Pixel On" 1 "Pixel Off" ;
VAL_ 1364 ICC_RISD_Pixel103_OnOff 0 "Pixel On" 1 "Pixel Off" ;
VAL_ 1364 ICC_RISD_Pixel104_OnOff 0 "Pixel On" 1 "Pixel Off" ;
VAL_ 1364 ICC_RISD_Pixel105_OnOff 0 "Pixel On" 1 "Pixel Off" ;
VAL_ 1364 ICC_RISD_Pixel106_OnOff 0 "Pixel On" 1 "Pixel Off" ;
VAL_ 1364 ICC_RISD_Pixel107_OnOff 0 "Pixel On" 1 "Pixel Off" ;
VAL_ 1364 ICC_RISD_Pixel108_OnOff 0 "Pixel On" 1 "Pixel Off" ;
VAL_ 1364 ICC_RISD_Pixel109_OnOff 0 "Pixel On" 1 "Pixel Off" ;
VAL_ 1364 ICC_RISD_Pixel110_OnOff 0 "Pixel On" 1 "Pixel Off" ;
VAL_ 1364 ICC_RISD_Pixel111_OnOff 0 "Pixel On" 1 "Pixel Off" ;
VAL_ 1364 ICC_RISD_Pixel112_OnOff 0 "Pixel On" 1 "Pixel Off" ;
VAL_ 1364 ICC_RISD_Pixel113_OnOff 0 "Pixel On" 1 "Pixel Off" ;
VAL_ 1364 ICC_RISD_Pixel114_OnOff 0 "Pixel On" 1 "Pixel Off" ;
VAL_ 1364 ICC_RISD_Pixel115_OnOff 0 "Pixel On" 1 "Pixel Off" ;
VAL_ 1364 ICC_RISD_Pixel116_OnOff 0 "Pixel On" 1 "Pixel Off" ;
VAL_ 1364 ICC_RISD_Pixel117_OnOff 0 "Pixel On" 1 "Pixel Off" ;
VAL_ 1364 ICC_RISD_Pixel118_OnOff 0 "Pixel On" 1 "Pixel Off" ;
VAL_ 1364 ICC_RISD_Pixel119_OnOff 0 "Pixel On" 1 "Pixel Off" ;
VAL_ 1364 ICC_RISD_Pixel120_OnOff 0 "Pixel On" 1 "Pixel Off" ;
VAL_ 1364 ICC_RISD_Pixel121_OnOff 0 "Pixel On" 1 "Pixel Off" ;
VAL_ 1364 ICC_RISD_Pixel122_OnOff 0 "Pixel On" 1 "Pixel Off" ;
VAL_ 1364 ICC_RISD_Pixel123_OnOff 0 "Pixel On" 1 "Pixel Off" ;
VAL_ 1364 ICC_RISD_Pixel124_OnOff 0 "Pixel On" 1 "Pixel Off" ;
VAL_ 1364 ICC_RISD_Pixel125_OnOff 0 "Pixel On" 1 "Pixel Off" ;
VAL_ 1364 ICC_RISD_Pixel126_OnOff 0 "Pixel On" 1 "Pixel Off" ;
VAL_ 1364 ICC_RISD_Pixel127_OnOff 0 "Pixel On" 1 "Pixel Off" ;
VAL_ 1364 ICC_RISD_Pixel128_OnOff 0 "Pixel On" 1 "Pixel Off" ;
VAL_ 1364 ICC_RISD_Pixel129_OnOff 0 "Pixel On" 1 "Pixel Off" ;
VAL_ 1364 ICC_RISD_Pixel130_OnOff 0 "Pixel On" 1 "Pixel Off" ;
VAL_ 1364 ICC_RISD_Pixel131_OnOff 0 "Pixel On" 1 "Pixel Off" ;
VAL_ 1364 ICC_RISD_Pixel132_OnOff 0 "Pixel On" 1 "Pixel Off" ;
VAL_ 1364 ICC_RISD_Pixel133_OnOff 0 "Pixel On" 1 "Pixel Off" ;
VAL_ 1364 ICC_RISD_Pixel134_OnOff 0 "Pixel On" 1 "Pixel Off" ;
VAL_ 1364 ICC_RISD_Pixel135_OnOff 0 "Pixel On" 1 "Pixel Off" ;
VAL_ 1364 ICC_RISD_Pixel136_OnOff 0 "Pixel On" 1 "Pixel Off" ;
VAL_ 1364 ICC_RISD_Pixel137_OnOff 0 "Pixel On" 1 "Pixel Off" ;
VAL_ 1364 ICC_RISD_Pixel138_OnOff 0 "Pixel On" 1 "Pixel Off" ;
VAL_ 1364 ICC_RISD_Pixel139_OnOff 0 "Pixel On" 1 "Pixel Off" ;
VAL_ 1364 ICC_RISD_Pixel140_OnOff 0 "Pixel On" 1 "Pixel Off" ;
VAL_ 1364 ICC_RISD_Pixel141_OnOff 0 "Pixel On" 1 "Pixel Off" ;
VAL_ 1364 ICC_RISD_Pixel142_OnOff 0 "Pixel On" 1 "Pixel Off" ;
VAL_ 1364 ICC_RISD_Pixel143_OnOff 0 "Pixel On" 1 "Pixel Off" ;
VAL_ 1364 ICC_RISD_Pixel144_OnOff 0 "Pixel On" 1 "Pixel Off" ;
VAL_ 1364 ICC_RISD_Pixel145_OnOff 0 "Pixel On" 1 "Pixel Off" ;
VAL_ 1364 ICC_RISD_Pixel146_OnOff 0 "Pixel On" 1 "Pixel Off" ;
VAL_ 1364 ICC_RISD_Pixel147_OnOff 0 "Pixel On" 1 "Pixel Off" ;
VAL_ 1364 ICC_RISD_Pixel148_OnOff 0 "Pixel On" 1 "Pixel Off" ;
VAL_ 1364 ICC_RISD_Pixel149_OnOff 0 "Pixel On" 1 "Pixel Off" ;
VAL_ 1364 ICC_RISD_Pixel150_OnOff 0 "Pixel On" 1 "Pixel Off" ;
VAL_ 1364 ICC_RISD_Pixel151_OnOff 0 "Pixel On" 1 "Pixel Off" ;
VAL_ 1364 ICC_RISD_Pixel152_OnOff 0 "Pixel On" 1 "Pixel Off" ;
VAL_ 1364 ICC_RISD_Pixel153_OnOff 0 "Pixel On" 1 "Pixel Off" ;
VAL_ 1364 ICC_RISD_Pixel154_OnOff 0 "Pixel On" 1 "Pixel Off" ;
VAL_ 1364 ICC_RISD_Pixel155_OnOff 0 "Pixel On" 1 "Pixel Off" ;
VAL_ 1364 ICC_RISD_Pixel156_OnOff 0 "Pixel On" 1 "Pixel Off" ;
VAL_ 1364 ICC_RISD_Pixel157_OnOff 0 "Pixel On" 1 "Pixel Off" ;
VAL_ 1364 ICC_RISD_Pixel158_OnOff 0 "Pixel On" 1 "Pixel Off" ;
VAL_ 1364 ICC_RISD_Pixel159_OnOff 0 "Pixel On" 1 "Pixel Off" ;
VAL_ 1364 ICC_RISD_Pixel160_OnOff 0 "Pixel On" 1 "Pixel Off" ;
VAL_ 1364 ICC_RISD_Pixel161_OnOff 0 "Pixel On" 1 "Pixel Off" ;
VAL_ 1364 ICC_RISD_Pixel162_OnOff 0 "Pixel On" 1 "Pixel Off" ;
VAL_ 1364 ICC_RISD_Pixel163_OnOff 0 "Pixel On" 1 "Pixel Off" ;
VAL_ 1364 ICC_RISD_Pixel164_OnOff 0 "Pixel On" 1 "Pixel Off" ;
VAL_ 1364 ICC_RISD_Pixel165_OnOff 0 "Pixel On" 1 "Pixel Off" ;
VAL_ 1364 ICC_RISD_Pixel166_OnOff 0 "Pixel On" 1 "Pixel Off" ;
VAL_ 1364 ICC_RISD_Pixel167_OnOff 0 "Pixel On" 1 "Pixel Off" ;
VAL_ 1364 ICC_RISD_Pixel168_OnOff 0 "Pixel On" 1 "Pixel Off" ;
VAL_ 1364 ICC_RISD_Pixel169_OnOff 0 "Pixel On" 1 "Pixel Off" ;
VAL_ 1364 ICC_RISD_Pixel170_OnOff 0 "Pixel On" 1 "Pixel Off" ;
VAL_ 1364 ICC_RISD_Pixel171_OnOff 0 "Pixel On" 1 "Pixel Off" ;
VAL_ 1364 ICC_RISD_Pixel172_OnOff 0 "Pixel On" 1 "Pixel Off" ;
VAL_ 1364 ICC_RISD_Pixel173_OnOff 0 "Pixel On" 1 "Pixel Off" ;
VAL_ 1364 ICC_RISD_Pixel174_OnOff 0 "Pixel On" 1 "Pixel Off" ;
VAL_ 1364 ICC_RISD_Pixel175_OnOff 0 "Pixel On" 1 "Pixel Off" ;
VAL_ 1364 ICC_RISD_Pixel176_OnOff 0 "Pixel On" 1 "Pixel Off" ;
VAL_ 1364 ICC_RISD_Pixel177_OnOff 0 "Pixel On" 1 "Pixel Off" ;
VAL_ 1364 ICC_RISD_Pixel178_OnOff 0 "Pixel On" 1 "Pixel Off" ;
VAL_ 1364 ICC_RISD_Pixel179_OnOff 0 "Pixel On" 1 "Pixel Off" ;
VAL_ 1364 ICC_RISD_Pixel180_OnOff 0 "Pixel On" 1 "Pixel Off" ;
VAL_ 1364 ICC_RISD_Pixel181_OnOff 0 "Pixel On" 1 "Pixel Off" ;
VAL_ 1364 ICC_RISD_Pixel182_OnOff 0 "Pixel On" 1 "Pixel Off" ;
VAL_ 1364 ICC_RISD_Pixel183_OnOff 0 "Pixel On" 1 "Pixel Off" ;
VAL_ 1364 ICC_RISD_Pixel184_OnOff 0 "Pixel On" 1 "Pixel Off" ;
VAL_ 1364 ICC_RISD_Pixel185_OnOff 0 "Pixel On" 1 "Pixel Off" ;
VAL_ 1364 ICC_RISD_Pixel186_OnOff 0 "Pixel On" 1 "Pixel Off" ;
VAL_ 1364 ICC_RISD_Pixel187_OnOff 0 "Pixel On" 1 "Pixel Off" ;
VAL_ 1364 ICC_RISD_Pixel188_OnOff 0 "Pixel On" 1 "Pixel Off" ;
VAL_ 1364 ICC_RISD_Pixel189_OnOff 0 "Pixel On" 1 "Pixel Off" ;
VAL_ 1364 ICC_RISD_Pixel190_OnOff 0 "Pixel On" 1 "Pixel Off" ;
VAL_ 1364 ICC_RISD_Pixel191_OnOff 0 "Pixel On" 1 "Pixel Off" ;
VAL_ 1364 ICC_RISD_Pixel192_OnOff 0 "Pixel On" 1 "Pixel Off" ;
VAL_ 1364 ICC_RISD_Pixel193_OnOff 0 "Pixel On" 1 "Pixel Off" ;
VAL_ 1364 ICC_RISD_Pixel194_OnOff 0 "Pixel On" 1 "Pixel Off" ;
VAL_ 1364 ICC_RISD_Pixel195_OnOff 0 "Pixel On" 1 "Pixel Off" ;
VAL_ 1364 ICC_RISD_Pixel196_OnOff 0 "Pixel On" 1 "Pixel Off" ;
VAL_ 1364 ICC_RISD_Pixel197_OnOff 0 "Pixel On" 1 "Pixel Off" ;
VAL_ 1364 ICC_RISD_Pixel198_OnOff 0 "Pixel On" 1 "Pixel Off" ;
VAL_ 1364 ICC_RISD_Pixel199_OnOff 0 "Pixel On" 1 "Pixel Off" ;
VAL_ 1364 ICC_RISD_Pixel200_OnOff 0 "Pixel On" 1 "Pixel Off" ;
VAL_ 1364 ICC_RISD_Pixel201_OnOff 0 "Pixel On" 1 "Pixel Off" ;
VAL_ 1364 ICC_RISD_Pixel202_OnOff 0 "Pixel On" 1 "Pixel Off" ;
VAL_ 1364 ICC_RISD_Pixel203_OnOff 0 "Pixel On" 1 "Pixel Off" ;
VAL_ 1364 ICC_RISD_Pixel204_OnOff 0 "Pixel On" 1 "Pixel Off" ;
VAL_ 1364 ICC_RISD_Pixel205_OnOff 0 "Pixel On" 1 "Pixel Off" ;
VAL_ 1364 ICC_RISD_Pixel206_OnOff 0 "Pixel On" 1 "Pixel Off" ;
VAL_ 1364 ICC_RISD_Pixel207_OnOff 0 "Pixel On" 1 "Pixel Off" ;
VAL_ 1364 ICC_RISD_Pixel208_OnOff 0 "Pixel On" 1 "Pixel Off" ;
VAL_ 1364 ICC_RISD_Pixel209_OnOff 0 "Pixel On" 1 "Pixel Off" ;
VAL_ 1364 ICC_RISD_Pixel210_OnOff 0 "Pixel On" 1 "Pixel Off" ;
VAL_ 1364 ICC_RISD_Pixel211_OnOff 0 "Pixel On" 1 "Pixel Off" ;
VAL_ 1364 ICC_RISD_Pixel212_OnOff 0 "Pixel On" 1 "Pixel Off" ;
VAL_ 1364 ICC_RISD_Pixel213_OnOff 0 "Pixel On" 1 "Pixel Off" ;
VAL_ 1364 ICC_RISD_Pixel214_OnOff 0 "Pixel On" 1 "Pixel Off" ;
VAL_ 1364 ICC_RISD_Pixel215_OnOff 0 "Pixel On" 1 "Pixel Off" ;
VAL_ 1364 ICC_RISD_Pixel216_OnOff 0 "Pixel On" 1 "Pixel Off" ;
VAL_ 1364 ICC_RISD_Pixel217_OnOff 0 "Pixel On" 1 "Pixel Off" ;
VAL_ 1364 ICC_RISD_Pixel218_OnOff 0 "Pixel On" 1 "Pixel Off" ;
VAL_ 1364 ICC_RISD_Pixel219_OnOff 0 "Pixel On" 1 "Pixel Off" ;
VAL_ 1364 ICC_RISD_Pixel220_OnOff 0 "Pixel On" 1 "Pixel Off" ;
VAL_ 1364 ICC_RISD_Pixel221_OnOff 0 "Pixel On" 1 "Pixel Off" ;
VAL_ 1364 ICC_RISD_Pixel222_OnOff 0 "Pixel On" 1 "Pixel Off" ;
VAL_ 1364 ICC_RISD_Pixel223_OnOff 0 "Pixel On" 1 "Pixel Off" ;
VAL_ 1364 ICC_RISD_Pixel224_OnOff 0 "Pixel On" 1 "Pixel Off" ;
VAL_ 1364 ICC_RISD_Pixel225_OnOff 0 "Pixel On" 1 "Pixel Off" ;
VAL_ 1364 ICC_RISD_Pixel226_OnOff 0 "Pixel On" 1 "Pixel Off" ;
VAL_ 1364 ICC_RISD_Pixel227_OnOff 0 "Pixel On" 1 "Pixel Off" ;
VAL_ 1364 ICC_RISD_Pixel228_OnOff 0 "Pixel On" 1 "Pixel Off" ;
VAL_ 1364 ICC_RISD_Pixel229_OnOff 0 "Pixel On" 1 "Pixel Off" ;
VAL_ 1364 ICC_RISD_Pixel230_OnOff 0 "Pixel On" 1 "Pixel Off" ;
VAL_ 1364 ICC_RISD_Pixel231_OnOff 0 "Pixel On" 1 "Pixel Off" ;
VAL_ 1364 ICC_RISD_Pixel232_OnOff 0 "Pixel On" 1 "Pixel Off" ;
VAL_ 1364 ICC_RISD_Pixel233_OnOff 0 "Pixel On" 1 "Pixel Off" ;
VAL_ 1364 ICC_RISD_Pixel234_OnOff 0 "Pixel On" 1 "Pixel Off" ;
VAL_ 1364 ICC_RISD_Pixel235_OnOff 0 "Pixel On" 1 "Pixel Off" ;
VAL_ 1364 ICC_RISD_Pixel236_OnOff 0 "Pixel On" 1 "Pixel Off" ;
VAL_ 1364 ICC_RISD_Pixel237_OnOff 0 "Pixel On" 1 "Pixel Off" ;
VAL_ 1364 ICC_RISD_Pixel238_OnOff 0 "Pixel On" 1 "Pixel Off" ;
VAL_ 1364 ICC_RISD_Pixel239_OnOff 0 "Pixel On" 1 "Pixel Off" ;
VAL_ 1364 ICC_RISD_Pixel240_OnOff 0 "Pixel On" 1 "Pixel Off" ;
VAL_ 1364 ICC_RISD_Pixel241_OnOff 0 "Pixel On" 1 "Pixel Off" ;
VAL_ 1364 ICC_RISD_Pixel242_OnOff 0 "Pixel On" 1 "Pixel Off" ;
VAL_ 1364 ICC_RISD_Pixel243_OnOff 0 "Pixel On" 1 "Pixel Off" ;
VAL_ 1364 ICC_RISD_Pixel244_OnOff 0 "Pixel On" 1 "Pixel Off" ;
VAL_ 1364 ICC_RISD_Pixel245_OnOff 0 "Pixel On" 1 "Pixel Off" ;
VAL_ 1364 ICC_RISD_Pixel246_OnOff 0 "Pixel On" 1 "Pixel Off" ;
VAL_ 1364 ICC_RISD_Pixel247_OnOff 0 "Pixel On" 1 "Pixel Off" ;
VAL_ 1364 ICC_RISD_Pixel248_OnOff 0 "Pixel On" 1 "Pixel Off" ;
VAL_ 1364 ICC_RISD_Pixel249_OnOff 0 "Pixel On" 1 "Pixel Off" ;
VAL_ 1364 ICC_RISD_Pixel250_OnOff 0 "Pixel On" 1 "Pixel Off" ;
VAL_ 1364 ICC_RISD_Pixel251_OnOff 0 "Pixel On" 1 "Pixel Off" ;
VAL_ 1364 ICC_RISD_Pixel252_OnOff 0 "Pixel On" 1 "Pixel Off" ;
VAL_ 1364 ICC_RISD_Pixel253_OnOff 0 "Pixel On" 1 "Pixel Off" ;
VAL_ 1364 ICC_RISD_Pixel254_OnOff 0 "Pixel On" 1 "Pixel Off" ;
VAL_ 1364 ICC_RISD_Pixel255_OnOff 0 "Pixel On" 1 "Pixel Off" ;
VAL_ 1364 ICC_RISD_Pixel256_OnOff 0 "Pixel On" 1 "Pixel Off" ;
VAL_ 1364 ICC_RISD_Pixel257_OnOff 0 "Pixel On" 1 "Pixel Off" ;
VAL_ 1364 ICC_RISD_Pixel258_OnOff 0 "Pixel On" 1 "Pixel Off" ;
VAL_ 1364 ICC_RISD_Pixel259_OnOff 0 "Pixel On" 1 "Pixel Off" ;
VAL_ 1364 ICC_RISD_Pixel260_OnOff 0 "Pixel On" 1 "Pixel Off" ;
VAL_ 1364 ICC_RISD_Pixel261_OnOff 0 "Pixel On" 1 "Pixel Off" ;
VAL_ 1364 ICC_RISD_Pixel262_OnOff 0 "Pixel On" 1 "Pixel Off" ;
VAL_ 1364 ICC_RISD_Pixel263_OnOff 0 "Pixel On" 1 "Pixel Off" ;
VAL_ 1364 ICC_RISD_Pixel264_OnOff 0 "Pixel On" 1 "Pixel Off" ;
VAL_ 1364 ICC_RISD_Pixel265_OnOff 0 "Pixel On" 1 "Pixel Off" ;
VAL_ 1364 ICC_RISD_Pixel266_OnOff 0 "Pixel On" 1 "Pixel Off" ;
VAL_ 1364 ICC_RISD_Pixel267_OnOff 0 "Pixel On" 1 "Pixel Off" ;
VAL_ 1364 ICC_RISD_Pixel268_OnOff 0 "Pixel On" 1 "Pixel Off" ;
VAL_ 1364 ICC_RISD_Pixel269_OnOff 0 "Pixel On" 1 "Pixel Off" ;
VAL_ 1364 ICC_RISD_Pixel270_OnOff 0 "Pixel On" 1 "Pixel Off" ;
VAL_ 1364 ICC_RISD_Pixel271_OnOff 0 "Pixel On" 1 "Pixel Off" ;
VAL_ 1364 ICC_RISD_Pixel272_OnOff 0 "Pixel On" 1 "Pixel Off" ;
VAL_ 1364 ICC_RISD_Pixel273_OnOff 0 "Pixel On" 1 "Pixel Off" ;
VAL_ 1364 ICC_RISD_Pixel274_OnOff 0 "Pixel On" 1 "Pixel Off" ;
VAL_ 1364 ICC_RISD_Pixel275_OnOff 0 "Pixel On" 1 "Pixel Off" ;
VAL_ 1364 ICC_RISD_Pixel276_OnOff 0 "Pixel On" 1 "Pixel Off" ;
VAL_ 1364 ICC_RISD_Pixel277_OnOff 0 "Pixel On" 1 "Pixel Off" ;
VAL_ 1364 ICC_RISD_Pixel278_OnOff 0 "Pixel On" 1 "Pixel Off" ;
VAL_ 1364 ICC_RISD_Pixel279_OnOff 0 "Pixel On" 1 "Pixel Off" ;
VAL_ 1364 ICC_RISD_Pixel280_OnOff 0 "Pixel On" 1 "Pixel Off" ;
VAL_ 1364 ICC_RISD_Pixel281_OnOff 0 "Pixel On" 1 "Pixel Off" ;
VAL_ 1364 ICC_RISD_Pixel282_OnOff 0 "Pixel On" 1 "Pixel Off" ;
VAL_ 1364 ICC_RISD_Pixel283_OnOff 0 "Pixel On" 1 "Pixel Off" ;
VAL_ 1364 ICC_RISD_Pixel284_OnOff 0 "Pixel On" 1 "Pixel Off" ;
VAL_ 1364 ICC_RISD_Pixel285_OnOff 0 "Pixel On" 1 "Pixel Off" ;
VAL_ 1364 ICC_RISD_Pixel286_OnOff 0 "Pixel On" 1 "Pixel Off" ;
VAL_ 1364 ICC_RISD_Pixel287_OnOff 0 "Pixel On" 1 "Pixel Off" ;
VAL_ 1364 ICC_RISD_Pixel288_OnOff 0 "Pixel On" 1 "Pixel Off" ;
VAL_ 1364 ICC_RISD_Pixel289_OnOff 0 "Pixel On" 1 "Pixel Off" ;
VAL_ 1364 ICC_RISD_Pixel290_OnOff 0 "Pixel On" 1 "Pixel Off" ;
VAL_ 1364 ICC_RISD_Pixel291_OnOff 0 "Pixel On" 1 "Pixel Off" ;
VAL_ 1364 ICC_RISD_Pixel292_OnOff 0 "Pixel On" 1 "Pixel Off" ;
VAL_ 1364 ICC_RISD_Pixel293_OnOff 0 "Pixel On" 1 "Pixel Off" ;
VAL_ 1364 ICC_RISD_Pixel294_OnOff 0 "Pixel On" 1 "Pixel Off" ;
VAL_ 1364 ICC_RISD_Pixel295_OnOff 0 "Pixel On" 1 "Pixel Off" ;
VAL_ 1364 ICC_RISD_Pixel296_OnOff 0 "Pixel On" 1 "Pixel Off" ;
VAL_ 1364 ICC_RISD_Pixel297_OnOff 0 "Pixel On" 1 "Pixel Off" ;
VAL_ 1364 ICC_RISD_Pixel298_OnOff 0 "Pixel On" 1 "Pixel Off" ;
VAL_ 1364 ICC_RISD_Pixel299_OnOff 0 "Pixel On" 1 "Pixel Off" ;
VAL_ 1364 ICC_RISD_Pixel300_OnOff 0 "Pixel On" 1 "Pixel Off" ;
VAL_ 1364 ICC_RISD_Pixel301_OnOff 0 "Pixel On" 1 "Pixel Off" ;
VAL_ 1364 ICC_RISD_Pixel302_OnOff 0 "Pixel On" 1 "Pixel Off" ;
VAL_ 1364 ICC_RISD_Pixel303_OnOff 0 "Pixel On" 1 "Pixel Off" ;
VAL_ 1364 ICC_RISD_Pixel304_OnOff 0 "Pixel On" 1 "Pixel Off" ;
VAL_ 1364 ICC_RISD_Pixel305_OnOff 0 "Pixel On" 1 "Pixel Off" ;
VAL_ 1364 ICC_RISD_Pixel306_OnOff 0 "Pixel On" 1 "Pixel Off" ;
VAL_ 1364 ICC_RISD_Pixel307_OnOff 0 "Pixel On" 1 "Pixel Off" ;
VAL_ 1364 ICC_RISD_Pixel308_OnOff 0 "Pixel On" 1 "Pixel Off" ;
VAL_ 1364 ICC_RISD_Pixel309_OnOff 0 "Pixel On" 1 "Pixel Off" ;
VAL_ 1364 ICC_RISD_Pixel310_OnOff 0 "Pixel On" 1 "Pixel Off" ;
VAL_ 1364 ICC_RISD_Pixel311_OnOff 0 "Pixel On" 1 "Pixel Off" ;
VAL_ 1364 ICC_RISD_Pixel312_OnOff 0 "Pixel On" 1 "Pixel Off" ;
VAL_ 1364 ICC_RISD_Pixel313_OnOff 0 "Pixel On" 1 "Pixel Off" ;
VAL_ 1364 ICC_RISD_Pixel314_OnOff 0 "Pixel On" 1 "Pixel Off" ;
VAL_ 1364 ICC_RISD_Pixel315_OnOff 0 "Pixel On" 1 "Pixel Off" ;
VAL_ 1364 ICC_RISD_Pixel316_OnOff 0 "Pixel On" 1 "Pixel Off" ;
VAL_ 1364 ICC_RISD_Pixel317_OnOff 0 "Pixel On" 1 "Pixel Off" ;
VAL_ 1364 ICC_RISD_Pixel318_OnOff 0 "Pixel On" 1 "Pixel Off" ;
VAL_ 1364 ICC_RISD_Pixel319_OnOff 0 "Pixel On" 1 "Pixel Off" ;
VAL_ 1364 ICC_RISD_Pixel320_OnOff 0 "Pixel On" 1 "Pixel Off" ;
VAL_ 1364 ICC_RISD_Pixel321_OnOff 0 "Pixel On" 1 "Pixel Off" ;
VAL_ 1364 ICC_RISD_Pixel322_OnOff 0 "Pixel On" 1 "Pixel Off" ;
VAL_ 1364 ICC_RISD_Pixel323_OnOff 0 "Pixel On" 1 "Pixel Off" ;
VAL_ 1364 ICC_RISD_Pixel324_OnOff 0 "Pixel On" 1 "Pixel Off" ;
VAL_ 1364 ICC_RISD_Pixel325_OnOff 0 "Pixel On" 1 "Pixel Off" ;
VAL_ 1364 ICC_RISD_Pixel326_OnOff 0 "Pixel On" 1 "Pixel Off" ;
VAL_ 1364 ICC_RISD_Pixel327_OnOff 0 "Pixel On" 1 "Pixel Off" ;
VAL_ 1364 ICC_RISD_Pixel328_OnOff 0 "Pixel On" 1 "Pixel Off" ;
VAL_ 1364 ICC_RISD_Pixel329_OnOff 0 "Pixel On" 1 "Pixel Off" ;
VAL_ 1364 ICC_RISD_Pixel330_OnOff 0 "Pixel On" 1 "Pixel Off" ;
VAL_ 1364 ICC_RISD_Pixel331_OnOff 0 "Pixel On" 1 "Pixel Off" ;
VAL_ 1364 ICC_RISD_Pixel332_OnOff 0 "Pixel On" 1 "Pixel Off" ;
VAL_ 1364 ICC_RISD_Pixel333_OnOff 0 "Pixel On" 1 "Pixel Off" ;
VAL_ 1364 ICC_RISD_Pixel334_OnOff 0 "Pixel On" 1 "Pixel Off" ;
VAL_ 1364 ICC_RISD_Pixel335_OnOff 0 "Pixel On" 1 "Pixel Off" ;
VAL_ 1364 ICC_RISD_Pixel336_OnOff 0 "Pixel On" 1 "Pixel Off" ;
VAL_ 1364 ICC_RISD_Pixel337_OnOff 0 "Pixel On" 1 "Pixel Off" ;
VAL_ 1364 ICC_RISD_Pixel338_OnOff 0 "Pixel On" 1 "Pixel Off" ;
VAL_ 1364 ICC_RISD_Pixel339_OnOff 0 "Pixel On" 1 "Pixel Off" ;
VAL_ 1364 ICC_RISD_Pixel340_OnOff 0 "Pixel On" 1 "Pixel Off" ;
VAL_ 1364 ICC_RISD_Pixel341_OnOff 0 "Pixel On" 1 "Pixel Off" ;
VAL_ 1364 ICC_RISD_Pixel342_OnOff 0 "Pixel On" 1 "Pixel Off" ;
VAL_ 1364 ICC_RISD_Pixel343_OnOff 0 "Pixel On" 1 "Pixel Off" ;
VAL_ 1364 ICC_RISD_Pixel344_OnOff 0 "Pixel On" 1 "Pixel Off" ;
VAL_ 1364 ICC_RISD_Pixel345_OnOff 0 "Pixel On" 1 "Pixel Off" ;
VAL_ 1364 ICC_RISD_Pixel346_OnOff 0 "Pixel On" 1 "Pixel Off" ;
VAL_ 1364 ICC_RISD_Pixel347_OnOff 0 "Pixel On" 1 "Pixel Off" ;
VAL_ 1364 ICC_RISD_Pixel348_OnOff 0 "Pixel On" 1 "Pixel Off" ;
VAL_ 1364 ICC_RISD_Pixel349_OnOff 0 "Pixel On" 1 "Pixel Off" ;
VAL_ 1364 ICC_RISD_Pixel350_OnOff 0 "Pixel On" 1 "Pixel Off" ;
VAL_ 1364 ICC_RISD_Pixel351_OnOff 0 "Pixel On" 1 "Pixel Off" ;
VAL_ 1364 ICC_RISD_Pixel352_OnOff 0 "Pixel On" 1 "Pixel Off" ;
VAL_ 1364 ICC_RISD_Pixel353_OnOff 0 "Pixel On" 1 "Pixel Off" ;
VAL_ 1364 ICC_RISD_Pixel354_OnOff 0 "Pixel On" 1 "Pixel Off" ;
VAL_ 1364 ICC_RISD_Pixel355_OnOff 0 "Pixel On" 1 "Pixel Off" ;
VAL_ 1364 ICC_RISD_Pixel356_OnOff 0 "Pixel On" 1 "Pixel Off" ;
VAL_ 1364 ICC_RISD_Pixel357_OnOff 0 "Pixel On" 1 "Pixel Off" ;
VAL_ 1364 ICC_RISD_Pixel358_OnOff 0 "Pixel On" 1 "Pixel Off" ;
VAL_ 1364 ICC_RISD_Pixel359_OnOff 0 "Pixel On" 1 "Pixel Off" ;
VAL_ 1364 ICC_RISD_Pixel360_OnOff 0 "Pixel On" 1 "Pixel Off" ;
VAL_ 1364 ICC_RISD_Pixel361_OnOff 0 "Pixel On" 1 "Pixel Off" ;
VAL_ 1364 ICC_RISD_Pixel362_OnOff 0 "Pixel On" 1 "Pixel Off" ;
VAL_ 1364 ICC_RISD_Pixel363_OnOff 0 "Pixel On" 1 "Pixel Off" ;
VAL_ 1364 ICC_RISD_Pixel364_OnOff 0 "Pixel On" 1 "Pixel Off" ;
VAL_ 1364 ICC_RISD_Pixel365_OnOff 0 "Pixel On" 1 "Pixel Off" ;
VAL_ 1364 ICC_RISD_Pixel366_OnOff 0 "Pixel On" 1 "Pixel Off" ;
VAL_ 1364 ICC_RISD_Pixel367_OnOff 0 "Pixel On" 1 "Pixel Off" ;
VAL_ 1364 ICC_RISD_Pixel368_OnOff 0 "Pixel On" 1 "Pixel Off" ;
VAL_ 1364 ICC_RISD_Pixel369_OnOff 0 "Pixel On" 1 "Pixel Off" ;
VAL_ 1364 ICC_RISD_Pixel370_OnOff 0 "Pixel On" 1 "Pixel Off" ;
VAL_ 1364 ICC_RISD_Pixel371_OnOff 0 "Pixel On" 1 "Pixel Off" ;
VAL_ 1364 ICC_RISD_Pixel372_OnOff 0 "Pixel On" 1 "Pixel Off" ;
VAL_ 1364 ICC_RISD_Pixel373_OnOff 0 "Pixel On" 1 "Pixel Off" ;
VAL_ 1364 ICC_RISD_Pixel374_OnOff 0 "Pixel On" 1 "Pixel Off" ;
VAL_ 1364 ICC_RISD_Pixel375_OnOff 0 "Pixel On" 1 "Pixel Off" ;
VAL_ 1364 ICC_RISD_Pixel376_OnOff 0 "Pixel On" 1 "Pixel Off" ;
VAL_ 1364 ICC_RISD_Pixel377_OnOff 0 "Pixel On" 1 "Pixel Off" ;
VAL_ 1364 ICC_RISD_Pixel378_OnOff 0 "Pixel On" 1 "Pixel Off" ;
VAL_ 1364 ICC_RISD_Pixel379_OnOff 0 "Pixel On" 1 "Pixel Off" ;
VAL_ 1364 ICC_RISD_Pixel380_OnOff 0 "Pixel On" 1 "Pixel Off" ;
VAL_ 1364 ICC_RISD_Pixel381_OnOff 0 "Pixel On" 1 "Pixel Off" ;
VAL_ 1364 ICC_RISD_Pixel382_OnOff 0 "Pixel On" 1 "Pixel Off" ;
VAL_ 1364 ICC_RISD_Pixel383_OnOff 0 "Pixel On" 1 "Pixel Off" ;
VAL_ 1364 ICC_RISD_Pixel384_OnOff 0 "Pixel On" 1 "Pixel Off" ;
VAL_ 1364 ICC_RISD_Pixel385_OnOff 0 "Pixel On" 1 "Pixel Off" ;
VAL_ 1364 ICC_RISD_Pixel386_OnOff 0 "Pixel On" 1 "Pixel Off" ;
VAL_ 1364 ICC_RISD_Pixel387_OnOff 0 "Pixel On" 1 "Pixel Off" ;
VAL_ 1364 ICC_RISD_Pixel388_OnOff 0 "Pixel On" 1 "Pixel Off" ;
VAL_ 1364 ICC_RISD_Pixel389_OnOff 0 "Pixel On" 1 "Pixel Off" ;
VAL_ 1364 ICC_RISD_Pixel390_OnOff 0 "Pixel On" 1 "Pixel Off" ;
VAL_ 1364 ICC_RISD_Pixel391_OnOff 0 "Pixel On" 1 "Pixel Off" ;
VAL_ 1364 ICC_RISD_Pixel392_OnOff 0 "Pixel On" 1 "Pixel Off" ;
VAL_ 1364 ICC_RISD_Pixel393_OnOff 0 "Pixel On" 1 "Pixel Off" ;
VAL_ 1364 ICC_RISD_Pixel394_OnOff 0 "Pixel On" 1 "Pixel Off" ;
VAL_ 1364 ICC_RISD_Pixel395_OnOff 0 "Pixel On" 1 "Pixel Off" ;
VAL_ 1364 ICC_RISD_Pixel396_OnOff 0 "Pixel On" 1 "Pixel Off" ;
VAL_ 1364 ICC_RISD_Pixel397_OnOff 0 "Pixel On" 1 "Pixel Off" ;
VAL_ 1364 ICC_RISD_Pixel398_OnOff 0 "Pixel On" 1 "Pixel Off" ;
VAL_ 1364 ICC_RISD_Pixel399_OnOff 0 "Pixel On" 1 "Pixel Off" ;
VAL_ 1364 ICC_RISD_Pixel400_OnOff 0 "Pixel On" 1 "Pixel Off" ;
VAL_ 1364 ICC_RISD_Pixel401_OnOff 0 "Pixel On" 1 "Pixel Off" ;
VAL_ 1364 ICC_RISD_Pixel402_OnOff 0 "Pixel On" 1 "Pixel Off" ;
VAL_ 1364 ICC_RISD_Pixel403_OnOff 0 "Pixel On" 1 "Pixel Off" ;
VAL_ 1364 ICC_RISD_Pixel404_OnOff 0 "Pixel On" 1 "Pixel Off" ;
VAL_ 1364 ICC_RISD_Pixel405_OnOff 0 "Pixel On" 1 "Pixel Off" ;
VAL_ 1364 ICC_RISD_Pixel406_OnOff 0 "Pixel On" 1 "Pixel Off" ;
VAL_ 1364 ICC_RISD_Pixel407_OnOff 0 "Pixel On" 1 "Pixel Off" ;
VAL_ 1364 ICC_RISD_Pixel408_OnOff 0 "Pixel On" 1 "Pixel Off" ;
VAL_ 1364 ICC_RISD_Pixel409_OnOff 0 "Pixel On" 1 "Pixel Off" ;
VAL_ 1364 ICC_RISD_Pixel410_OnOff 0 "Pixel On" 1 "Pixel Off" ;
VAL_ 1364 ICC_RISD_Pixel411_OnOff 0 "Pixel On" 1 "Pixel Off" ;
VAL_ 1364 ICC_RISD_Pixel412_OnOff 0 "Pixel On" 1 "Pixel Off" ;
VAL_ 1364 ICC_RISD_Pixel413_OnOff 0 "Pixel On" 1 "Pixel Off" ;
VAL_ 1364 ICC_RISD_Pixel414_OnOff 0 "Pixel On" 1 "Pixel Off" ;
VAL_ 1364 ICC_RISD_Pixel415_OnOff 0 "Pixel On" 1 "Pixel Off" ;
VAL_ 1364 ICC_RISD_Pixel416_OnOff 0 "Pixel On" 1 "Pixel Off" ;
VAL_ 1364 ICC_RISD_Pixel417_OnOff 0 "Pixel On" 1 "Pixel Off" ;
VAL_ 1364 ICC_RISD_Pixel418_OnOff 0 "Pixel On" 1 "Pixel Off" ;
VAL_ 1364 ICC_RISD_Pixel419_OnOff 0 "Pixel On" 1 "Pixel Off" ;
VAL_ 1364 ICC_RISD_Pixel420_OnOff 0 "Pixel On" 1 "Pixel Off" ;
VAL_ 1364 ICC_RISD_Pixel421_OnOff 0 "Pixel On" 1 "Pixel Off" ;
VAL_ 1364 ICC_RISD_Pixel422_OnOff 0 "Pixel On" 1 "Pixel Off" ;
VAL_ 1364 ICC_RISD_Pixel423_OnOff 0 "Pixel On" 1 "Pixel Off" ;
VAL_ 1364 ICC_RISD_Pixel424_OnOff 0 "Pixel On" 1 "Pixel Off" ;
VAL_ 1364 ICC_RISD_Pixel425_OnOff 0 "Pixel On" 1 "Pixel Off" ;
VAL_ 1364 ICC_RISD_Pixel426_OnOff 0 "Pixel On" 1 "Pixel Off" ;
VAL_ 1364 ICC_RISD_Pixel427_OnOff 0 "Pixel On" 1 "Pixel Off" ;
VAL_ 1364 ICC_RISD_Pixel428_OnOff 0 "Pixel On" 1 "Pixel Off" ;
VAL_ 1364 ICC_RISD_Pixel429_OnOff 0 "Pixel On" 1 "Pixel Off" ;
VAL_ 1364 ICC_RISD_Pixel430_OnOff 0 "Pixel On" 1 "Pixel Off" ;
VAL_ 1364 ICC_RISD_Pixel431_OnOff 0 "Pixel On" 1 "Pixel Off" ;
VAL_ 1364 ICC_RISD_Pixel432_OnOff 0 "Pixel On" 1 "Pixel Off" ;
VAL_ 1364 ICC_RISD_Pixel433_OnOff 0 "Pixel On" 1 "Pixel Off" ;
VAL_ 1364 ICC_RISD_Pixel434_OnOff 0 "Pixel On" 1 "Pixel Off" ;
VAL_ 1364 ICC_RISD_Pixel435_OnOff 0 "Pixel On" 1 "Pixel Off" ;
VAL_ 1364 ICC_RISD_Pixel436_OnOff 0 "Pixel On" 1 "Pixel Off" ;
VAL_ 1364 ICC_RISD_Pixel437_OnOff 0 "Pixel On" 1 "Pixel Off" ;
VAL_ 1364 ICC_RISD_Pixel438_OnOff 0 "Pixel On" 1 "Pixel Off" ;
VAL_ 1364 ICC_RISD_Pixel439_OnOff 0 "Pixel On" 1 "Pixel Off" ;
VAL_ 1364 ICC_RISD_Pixel440_OnOff 0 "Pixel On" 1 "Pixel Off" ;
VAL_ 1364 ICC_RISD_Pixel441_OnOff 0 "Pixel On" 1 "Pixel Off" ;
VAL_ 1364 ICC_RISD_Pixel442_OnOff 0 "Pixel On" 1 "Pixel Off" ;
VAL_ 1364 ICC_RISD_Pixel443_OnOff 0 "Pixel On" 1 "Pixel Off" ;
VAL_ 1364 ICC_RISD_Pixel444_OnOff 0 "Pixel On" 1 "Pixel Off" ;
VAL_ 1364 ICC_RISD_Pixel445_OnOff 0 "Pixel On" 1 "Pixel Off" ;
VAL_ 1364 ICC_RISD_Pixel446_OnOff 0 "Pixel On" 1 "Pixel Off" ;
VAL_ 1364 ICC_RISD_Pixel447_OnOff 0 "Pixel On" 1 "Pixel Off" ;
VAL_ 1364 ICC_RISD_Pixel448_OnOff 0 "Pixel On" 1 "Pixel Off" ;
VAL_ 1364 ICC_RISD_Pixel449_OnOff 0 "Pixel On" 1 "Pixel Off" ;
VAL_ 1364 ICC_RISD_Pixel450_OnOff 0 "Pixel On" 1 "Pixel Off" ;
VAL_ 1364 ICC_RISD_Pixel451_OnOff 0 "Pixel On" 1 "Pixel Off" ;
VAL_ 1364 ICC_RISD_Pixel452_OnOff 0 "Pixel On" 1 "Pixel Off" ;
VAL_ 1364 ICC_RISD_Pixel453_OnOff 0 "Pixel On" 1 "Pixel Off" ;
VAL_ 1364 ICC_RISD_Pixel454_OnOff 0 "Pixel On" 1 "Pixel Off" ;
VAL_ 1364 ICC_RISD_Pixel455_OnOff 0 "Pixel On" 1 "Pixel Off" ;
VAL_ 1364 ICC_RISD_Pixel456_OnOff 0 "Pixel On" 1 "Pixel Off" ;
VAL_ 1364 ICC_RISD_Pixel457_OnOff 0 "Pixel On" 1 "Pixel Off" ;
VAL_ 1364 ICC_RISD_Pixel458_OnOff 0 "Pixel On" 1 "Pixel Off" ;
VAL_ 1364 ICC_RISD_Pixel459_OnOff 0 "Pixel On" 1 "Pixel Off" ;
VAL_ 1364 ICC_RISD_Pixel460_OnOff 0 "Pixel On" 1 "Pixel Off" ;
VAL_ 1364 ICC_RISD_Pixel461_OnOff 0 "Pixel On" 1 "Pixel Off" ;
VAL_ 1364 ICC_RISD_Pixel462_OnOff 0 "Pixel On" 1 "Pixel Off" ;
VAL_ 1364 ICC_RISD_Pixel463_OnOff 0 "Pixel On" 1 "Pixel Off" ;
VAL_ 1364 ICC_RISD_Pixel464_OnOff 0 "Pixel On" 1 "Pixel Off" ;
VAL_ 1364 ICC_RISD_Pixel465_OnOff 0 "Pixel On" 1 "Pixel Off" ;
VAL_ 1364 ICC_RISD_Pixel466_OnOff 0 "Pixel On" 1 "Pixel Off" ;
VAL_ 1364 ICC_RISD_Pixel467_OnOff 0 "Pixel On" 1 "Pixel Off" ;
VAL_ 1364 ICC_RISD_Pixel468_OnOff 0 "Pixel On" 1 "Pixel Off" ;
VAL_ 1364 ICC_RISD_Pixel469_OnOff 0 "Pixel On" 1 "Pixel Off" ;
VAL_ 1364 ICC_RISD_Pixel470_OnOff 0 "Pixel On" 1 "Pixel Off" ;
VAL_ 1364 ICC_RISD_Pixel471_OnOff 0 "Pixel On" 1 "Pixel Off" ;
VAL_ 1364 ICC_RISD_Pixel472_OnOff 0 "Pixel On" 1 "Pixel Off" ;
VAL_ 1364 ICC_RISD_Pixel473_OnOff 0 "Pixel On" 1 "Pixel Off" ;
VAL_ 1364 ICC_RISD_Pixel474_OnOff 0 "Pixel On" 1 "Pixel Off" ;
VAL_ 1364 ICC_RISD_Pixel475_OnOff 0 "Pixel On" 1 "Pixel Off" ;
VAL_ 1364 ICC_RISD_Pixel476_OnOff 0 "Pixel On" 1 "Pixel Off" ;
VAL_ 1364 ICC_RISD_Pixel477_OnOff 0 "Pixel On" 1 "Pixel Off" ;
VAL_ 1364 ICC_RISD_Pixel478_OnOff 0 "Pixel On" 1 "Pixel Off" ;
VAL_ 1364 ICC_RISD_Pixel479_OnOff 0 "Pixel On" 1 "Pixel Off" ;
VAL_ 1364 ICC_RISD_Pixel480_OnOff 0 "Pixel On" 1 "Pixel Off" ;
VAL_ 1364 ICC_RISD_Pixel481_OnOff 0 "Pixel On" 1 "Pixel Off" ;
VAL_ 1364 ICC_RISD_Pixel482_OnOff 0 "Pixel On" 1 "Pixel Off" ;
VAL_ 1364 ICC_RISD_Pixel483_OnOff 0 "Pixel On" 1 "Pixel Off" ;
VAL_ 1364 ICC_RISD_Pixel484_OnOff 0 "Pixel On" 1 "Pixel Off" ;
VAL_ 1364 ICC_RISD_Pixel485_OnOff 0 "Pixel On" 1 "Pixel Off" ;
VAL_ 1364 ICC_RISD_Pixel486_OnOff 0 "Pixel On" 1 "Pixel Off" ;
VAL_ 1364 ICC_RISD_Pixel487_OnOff 0 "Pixel On" 1 "Pixel Off" ;
VAL_ 1364 ICC_RISD_Pixel488_OnOff 0 "Pixel On" 1 "Pixel Off" ;
VAL_ 1364 ICC_RISD_Pixel489_OnOff 0 "Pixel On" 1 "Pixel Off" ;
VAL_ 1364 ICC_RISD_Pixel490_OnOff 0 "Pixel On" 1 "Pixel Off" ;
VAL_ 1364 ICC_RISD_Pixel491_OnOff 0 "Pixel On" 1 "Pixel Off" ;
VAL_ 1364 ICC_RISD_Pixel492_OnOff 0 "Pixel On" 1 "Pixel Off" ;
VAL_ 1364 ICC_RISD_Pixel493_OnOff 0 "Pixel On" 1 "Pixel Off" ;
VAL_ 1364 ICC_RISD_Pixel494_OnOff 0 "Pixel On" 1 "Pixel Off" ;
VAL_ 1364 ICC_RISD_Pixel495_OnOff 0 "Pixel On" 1 "Pixel Off" ;
VAL_ 1364 ICC_RISD_Pixel496_OnOff 0 "Pixel On" 1 "Pixel Off" ;
VAL_ 1364 ICC_RISD_Pixel497_OnOff 0 "Pixel On" 1 "Pixel Off" ;
VAL_ 1364 ICC_RISD_Pixel498_OnOff 0 "Pixel On" 1 "Pixel Off" ;
VAL_ 1364 ICC_RISD_Pixel499_OnOff 0 "Pixel On" 1 "Pixel Off" ;
VAL_ 1364 ICC_RISD_Pixel500_OnOff 0 "Pixel On" 1 "Pixel Off" ;
VAL_ 1364 ICC_RISD_Pixel501_OnOff 0 "Pixel On" 1 "Pixel Off" ;
VAL_ 1364 ICC_RISD_Pixel502_OnOff 0 "Pixel On" 1 "Pixel Off" ;
VAL_ 1364 ICC_RISD_Pixel503_OnOff 0 "Pixel On" 1 "Pixel Off" ;
VAL_ 1364 ICC_RISD_Pixel504_OnOff 0 "Pixel On" 1 "Pixel Off" ;
VAL_ 1366 ICC_LKSSettingModSt 0 "Not Active" 1 "Warning" 2 "Warning And Intervention" 3 "OFF" ;
VAL_ 1366 ICC_LDWWarnType 0 "Not Active" 1 "Warning Only" 2 "Vibration  Only" 3 "Warning And Vibration" ;
VAL_ 1366 ICC_LDWLDPSnvtySet 0 "Not Active" 1 "High" 2 "Low" 3 "reserve" ;
VAL_ 1366 ICC_ELKSettingSt 0 "Not Active" 1 "ON" 2 "OFF" 3 "Reserved" ;
VAL_ 1366 ICC_ISLIWarnMod 0 "Not Active" 1 "Display warning" 2 "Sound And Display Warning" 3 "OFF" ;
VAL_ 1366 ICC_AEBSettingSt 0 "Not Active" 1 "ON" 2 "OFF" 3 "Reserved" ;
VAL_ 1366 ICC_FCWSettingSt 0 "Not Active" 1 "OFF" 2 "High" 3 "Middle" 4 "Low" 5 "Reserved" 6 "Reserved" 7 "Reserved" ;
VAL_ 1366 ICC_ICAEnableBtnSts 0 "Not Active" 1 "ON" 2 "OFF" 3 "Reserved" ;
VAL_ 1366 ICC_Reset 0 "Not_Active" 1 "ON" ;
VAL_ 1366 ICC_ACC_SwrsSts 0 "OFF" 1 "ON" ;
VAL_ 1366 ICC_Customize_buttons 0 "Not Active" 1 "APA" 2 "TJA/ICA/ACC/NOA" 3 "Offroad AutoPilot" 4 "HPA" 5 "Not used" 6 "Not used" 7 "Not used" ;
VAL_ 1366 ICC_AVM_TouchEvt 0 "Not active" 1 "Press down" 2 "Moving" 3 "Lift up" ;
VAL_ 1366 ICC_HMAOnOffSet 0 "Inactive" 1 "OFF" 2 "ON" 3 "reserved" ;
VAL_ 1366 ICC_OtaDwnLoad_556h 0 "Not Active" 1 "ReqDwnLoad" 2 "Reaserved" 3 "Reaserved" ;
VAL_ 1366 ICC_RRMDisplay_AVM_APA_556h 0 "Not Ative" 1 "AVM ON" 2 "AVM OFF" 3 "APA ON" 4 "APA OFF" 5 "Reserved" 6 "Reserved" 7 "Reserved" ;
VAL_ 1366 ICC_CarMdlSetColor_556h 0 "Not Active" 1 "Colour1" 2 "Colour2" 3 "Colour3" 4 "Colour4" 5 "Colour5" 6 "Colour6" 7 "Colour7" 8 "Colour8" 9 "Colour9" 10 "Colour10" 11 "Colour11" 12 "Colour12" 13 "Colour13" 14 "Colour14" 15 "Colour15" ;
VAL_ 1366 ICC_AVMActivationSpeedSet_556h 0 "Not Active" 1 "Speed1(15KM/h)" 2 "Speed2(30KM/h)" 3 "Not Used" ;
VAL_ 1366 ICC_enum_AESSettingSt_556h 0 "None" 1 "ON" 2 "Off" 3 "reserved" ;
VAL_ 1366 ICC_enum_MAASettingSt_556h 0 "None" 1 "ON" 2 "Off" 3 "reserved" ;
VAL_ 1366 ICC_enum_MEBSettingSt_556h 0 "None" 1 "ON" 2 "Off" 3 "reserved" ;
VAL_ 1366 ICC_DataCollectionSwtSet_556h 0 "Not Active" 1 "ON" 2 "OFF" 3 "Not Used" ;
VAL_ 1366 ICC_ADS_DAISwtSet_556h 0 "Not Active" 1 "ON" 2 "OFF" 3 "Not Used" ;
VAL_ 1366 ICC_VoiceplayModeSwtSet_556h 0 "Not_Active" 1 "Concise" 2 "Detail" 3 "Not_Used" ;
VAL_ 1366 ICC_NOPEnableBtnSts_556h 0 "None" 1 "ON" 2 "Off" 3 "reserved" ;
VAL_ 1366 ICC_ParkFuncUserLearnSts_556h 0 "No Tips" 1 "Learned" 2 "Not Learned" ;
VAL_ 1366 TimeToStopSentinelMinutSet_556h 0 "Minute_0" 1 "Minute_1" 2 "Minute_2" 3 "Minute_3" 4 "Minute_4" 5 "Minute_5" 6 "Minute_6" 7 "Minute_7" 8 "Minute_8" 9 "Minute_9" 10 "Minute_10" 11 "Minute_11" 12 "Minute_12" 13 "Minute_13" 14 "Minute_14" 15 "Minute_15" 16 "Minute_16" 17 "Minute_17" 18 "Minute_18" 19 "Minute_19" 20 "Minute_20" 21 "Minute_21" 22 "Minute_22" 23 "Minute_23" 24 "Minute_24" 25 "Minute_25" 26 "Minute_26" 27 "Minute_27" 28 "Minute_28" 29 "Minute_29" 30 "Minute_30" 31 "Minute_31" 32 "Minute_32" 33 "Minute_33" 34 "Minute_34" 35 "Minute_35" 36 "Minute_36" 37 "Minute_37" 38 "Minute_38" 39 "Minute_39" 40 "Minute_40" 41 "Minute_41" 42 "Minute_42" 43 "Minute_43" 44 "Minute_44" 45 "Minute_45" 46 "Minute_46" 47 "Minute_47" 48 "Minute_48" 49 "Minute_49" 50 "Minute_50" 51 "Minute_51" 52 "Minute_52" 53 "Minute_53" 54 "Minute_54" 55 "Minute_55" 56 "Minute_56" 57 "Minute_57" 58 "Minute_58" 59 "Minute_59" 62 "Inactive" 63 "Invalid" ;
VAL_ 1366 ReservationSentinelReq_556h 0 "No_active" 1 "ON" 2 "OFF" ;
VAL_ 1366 TimeToStopSentinelHourSet_556h 0 "Hour_0" 1 "Hour_1" 2 "Hour_2" 3 "Hour_3" 4 "Hour_4" 5 "Hour_5" 6 "Hour_6" 7 "Hour_7" 8 "Hour_8" 9 "Hour_9" 10 "Hour_10" 11 "Hour_11" 12 "Hour_12" 13 "Hour_13" 14 "Hour_14" 15 "Hour_15" 16 "Hour_16" 17 "Hour_17" 18 "Hour_18" 19 "Hour_19" 20 "Hour_20" 21 "Hour_21" 22 "Hour_22" 23 "Hour_23" 30 "Inactive" 31 "Invalid" ;
VAL_ 1366 SentinelMode_SensitivityReq_556h 0 "No_active" 1 "High" 2 "Middle" 3 "Low" ;
VAL_ 1366 TimeToStartSentinelHourSet_556h 0 "Hour_0" 1 "Hour_1" 2 "Hour_2" 3 "Hour_3" 4 "Hour_4" 5 "Hour_5" 6 "Hour_6" 7 "Hour_7" 8 "Hour_8" 9 "Hour_9" 10 "Hour_10" 11 "Hour_11" 12 "Hour_12" 13 "Hour_13" 14 "Hour_14" 15 "Hour_15" 16 "Hour_16" 17 "Hour_17" 18 "Hour_18" 19 "Hour_19" 20 "Hour_20" 21 "Hour_21" 22 "Hour_22" 23 "Hour_23" 30 "Inactive" 31 "Invalid" ;
VAL_ 1366 TimeToStartSentinelDaySet_556h 0 "No_active" 1 "Toady" 2 "Tomorrow" ;
VAL_ 1366 TimeToStartSentinelMinutSet_556h 0 "Minute_0" 1 "Minute_1" 2 "Minute_2" 3 "Minute_3" 4 "Minute_4" 5 "Minute_5" 6 "Minute_6" 7 "Minute_7" 8 "Minute_8" 9 "Minute_9" 10 "Minute_10" 11 "Minute_11" 12 "Minute_12" 13 "Minute_13" 14 "Minute_14" 15 "Minute_15" 16 "Minute_16" 17 "Minute_17" 18 "Minute_18" 19 "Minute_19" 20 "Minute_20" 21 "Minute_21" 22 "Minute_22" 23 "Minute_23" 24 "Minute_24" 25 "Minute_25" 26 "Minute_26" 27 "Minute_27" 28 "Minute_28" 29 "Minute_29" 30 "Minute_30" 31 "Minute_31" 32 "Minute_32" 33 "Minute_33" 34 "Minute_34" 35 "Minute_35" 36 "Minute_36" 37 "Minute_37" 38 "Minute_38" 39 "Minute_39" 40 "Minute_40" 41 "Minute_41" 42 "Minute_42" 43 "Minute_43" 44 "Minute_44" 45 "Minute_45" 46 "Minute_46" 47 "Minute_47" 48 "Minute_48" 49 "Minute_49" 50 "Minute_50" 51 "Minute_51" 52 "Minute_52" 53 "Minute_53" 54 "Minute_54" 55 "Minute_55" 56 "Minute_56" 57 "Minute_57" 58 "Minute_58" 59 "Minute_59" 62 "Inactive" 63 "Invalid" ;
VAL_ 1366 SentinelModeSwitchReq_556h 0 "No_active" 1 "ON" 2 "OFF" ;
VAL_ 1380 ICC_DrvSeatHeatLvlCmd2_564h 0 "Not active" 1 "OFF" 2 "Seat heating Level1" 3 "Seat heating Level2" 4 "Seat heating Level3" 5 "Seat heating Level4" 6 "Seat heating Level5" 7 "Seat heating Level6" 8 "Seat heating Level7" 9 "Seat heating Level8" 10 "Seat heating Level9" 11 "Reserved" ;
VAL_ 1380 ICC_DrvSecSeatHeatLvlCmd2_564h 0 "Not active" 1 "OFF" 2 "Seat heating Level1" 3 "Seat heating Level2" 4 "Seat heating Level3" 5 "Seat heating Level4" 6 "Seat heating Level5" 7 "Seat heating Level6" 8 "Seat heating Level7" 9 "Seat heating Level8" 10 "Seat heating Level9" 11 "Reserved" ;
VAL_ 1380 ICC_DrvSeatVentLvlCmd2_564h 0 "Not Active" 1 "OFF" 2 "Seat Ventilation Level1" 3 "Seat Ventilation Level2" 4 "Seat Ventilation Level3" 5 "Seat Ventilation Level4" 6 "Seat Ventilation Level5" 7 "Seat Ventilation Level6" 8 "Seat Ventilation Level7" 9 "Seat Ventilation Level8" 10 "Seat Ventilation Level9" 11 "Reserved" ;
VAL_ 1380 ICC_DrvSecSeatVentLvlCmd2_564h 0 "Not Active" 1 "OFF" 2 "Seat Ventilation Level1" 3 "Seat Ventilation Level2" 4 "Seat Ventilation Level3" 5 "Seat Ventilation Level4" 6 "Seat Ventilation Level5" 7 "Seat Ventilation Level6" 8 "Seat Ventilation Level7" 9 "Seat Ventilation Level8" 10 "Seat Ventilation Level9" 11 "Reserved" ;
VAL_ 1380 ICC_FRSeatHeatLvlCmd2 0 "Not active" 1 "OFF" 2 "Seat heating Level1" 3 "Seat heating Level2" 4 "Seat heating Level3" 5 "Seat heating Level4" 6 "Seat heating Level5" 7 "Seat heating Level6" 8 "Seat heating Level7" 9 "Seat heating Level8" 10 "Seat heating Level9" 11 "Reserved" ;
VAL_ 1380 ICC_RRSeatHeatLvlCmd2 0 "Not active" 1 "OFF" 2 "Seat heating Level1" 3 "Seat heating Level2" 4 "Seat heating Level3" 5 "Seat heating Level4" 6 "Seat heating Level5" 7 "Seat heating Level6" 8 "Seat heating Level7" 9 "Seat heating Level8" 10 "Seat heating Level9" 11 "Reserved" ;
VAL_ 1380 ICC_FRSeatVentLvlCmd2 0 "Not Active" 1 "OFF" 2 "Seat Ventilation Level1" 3 "Seat Ventilation Level2" 4 "Seat Ventilation Level3" 5 "Seat Ventilation Level4" 6 "Seat Ventilation Level5" 7 "Seat Ventilation Level6" 8 "Seat Ventilation Level7" 9 "Seat Ventilation Level8" 10 "Seat Ventilation Level9" 11 "Reserved" ;
VAL_ 1380 ICC_RRSeatVentLvlCmd2 0 "Not Active" 1 "OFF" 2 "Seat Ventilation Level1" 3 "Seat Ventilation Level2" 4 "Seat Ventilation Level3" 5 "Seat Ventilation Level4" 6 "Seat Ventilation Level5" 7 "Seat Ventilation Level6" 8 "Seat Ventilation Level7" 9 "Seat Ventilation Level8" 10 "Seat Ventilation Level9" 11 "Reserved" ;
VAL_ 1380 ICC_FRSeatliedownCmd2 0 "Not active" 1 "Unfold" 2 "Return" 3 "Reserved" ;
VAL_ 1380 ICC_2nd_FREnjoyableSeatSwitch 0 "Not Active" 1 "Entrence" 2 "Exit" 3 "Pause" ;
VAL_ 1380 ICC_3rd_FLEnjoyableSeatSwitch 0 "Not Active" 1 "Entrence" 2 "Exit" 3 "Pause" ;
VAL_ 1380 ICC_3rd_FLFrontFlipSwitch 0 "Not Active" 1 "FrontFlip" 2 "Exit" 3 "Pause" ;
VAL_ 1380 ICC_3rd_FREnjoyableSeatSwitch 0 "Not Active" 1 "Entrence" 2 "Exit" 3 "Pause" ;
VAL_ 1380 ICC_3rd_FRFrontFlipSwitch 0 "Not Active" 1 "FrontFlip" 2 "Exit" 3 "Pause" ;
VAL_ 1380 ICC_QueenSeatSwitch 0 "Not Active" 1 "Entrence" 2 "Exit" 3 "Pause" ;
VAL_ 1380 ICC_SetAVASFuntion_564h 0 "Not_Active" 1 "AVAS_ON" 2 "AVAS_OFF" 3 "Not_Used" ;
VAL_ 1380 ICC_AutoSeatHeatLevelCmd_564h 0 "Not Active" 1 "ON" 2 "OFF" 3 "Reserved" ;
VAL_ 1380 ICC_AutoSteerWhlHeatCmd_564h 0 "Not Active" 1 "ON" 2 "OFF" 3 "Reserved" ;
VAL_ 1380 ICC_AutoSeatVentLevelCmd_564h 0 "Not Active" 1 "ON" 2 "OFF" 3 "Reserved" ;
VAL_ 1394 AVAS_FunctionSts_572h 0 "ON" 1 "OFF" ;
VAL_ 1399 ICC_Conditiontype 0 "Default" 1 "Dynamics" 2 "CLTC" 3 "WLTC" ;
VAL_ 1399 MaintenanceOdometer_Valid_577h 0 "Valid" 1 "Not valid" ;
VAL_ 1399 MaintenanceOdometer_BkpEn_577h 0 "Not Active" 1 "Disable" 2 "Enable" 3 "Reserved" ;
VAL_ 1403 RMCU_ErrLvlDis 0 "No Error" 1 "Err_level1" 2 "Err_level2" 3 "Err_level3" 4 "Err_level4" 5 "Err_level5" 6 "Err_level6" ;
VAL_ 1403 RMCU_Speed_EDR 65535 "Invalid" ;
VAL_ 1417 HCU_stCleverDisReason_589h 0 "No_Command" 1 "please quit offroad drive mode" 2 "please quit cco mode" 3 "please quit ads mode" 4 "please quit energy saving mode" 5 "please quit sickness mode" 6 "Please turn off the CleverDrv and try again" 7 "The CleverDrv has been enabled. The driving mode cannot be adjusted. If you need to adjust it, please turn off the CleverDrv" 8 "please quit CleverRgn mode" ;
VAL_ 1419 ICM_EngineOil_LiquidLow_58Bh 0 "Off" 1 "On" ;
VAL_ 1419 ICM_BrakeFluidSts_58Bh 0 "Normal" 1 "Empty" ;
VAL_ 1427 ILCF_1_LogoParkingSts 0 "Not Active" 1 "ON" 2 "OFF" 3 "Reserved" ;
VAL_ 1427 ILCF_1_DIYMusicShowModSts 0 "Not Active" 1 "Mode1" 2 "Mode2" 3 "Mode3" ;
VAL_ 1427 ILCF_1_RandomMusicShowSts 0 "Not Active" 1 "Active" 2 "Reserved" 3 "Reserved" ;
VAL_ 1451 SBOX_GNSS_ANT_State 0 "GPS State is normal" 1 "GPS State is Short-Circuit to GND" 2 "GPS State is Short-Circuit to VCC" 3 "Reserved" ;
VAL_ 1451 SBOX_SIM_State 0 "SIM_State is normal" 1 "SIM_State is abnormal" ;
VAL_ 1451 SBOX_BT_State 0 "BT_State is normal" 1 "BT_State is abnormal" ;
VAL_ 1451 SBOX_TT_State 0 "TT_State is normal" 1 "TT_State is abnormal" ;
VAL_ 1451 SBOX_TT_ANT_State 0 "TT State is normal" 1 "TT State is Short-Circuit to GND" 2 "TT State is Short-Circuit to VCC" 3 "Reserved" ;
VAL_ 1451 SBOX_BatterState 0 "BackupPowe is normal" 1 "BackupPowe is Short-Circuit" 2 "BackupPowe is Open-Circuit" 3 "Reserved" ;
VAL_ 1451 SBOX_PowerState 0 "Power is normal" 1 "Power is overvoltage" 2 "Power is undervoltage" 3 "Reserved" ;
VAL_ 1451 SBOX_SimActivation 0 "unactivate" 1 "activate" ;
VAL_ 1451 SBOX_TspActivation 0 "unactivate" 1 "activate" ;
VAL_ 1451 SBOX_SatelliteStatus 1 "holding state" 2 "registered network" 3 "registration network failure" 4 "register network successfully" ;
VAL_ 1451 SBOX_BtConState 0 "not connect" 1 "connect car(SPP)" 2 "connect app(BLE)" ;
VAL_ 1451 SBOX_SelfCheck 0 "Invalid" 1 "Abnormal" 2 "Normal" ;
VAL_ 1451 SBOX_BatTemp 255 "Invalid" ;
VAL_ 1451 SBOX_EcallState 0 "Invalid" 1 "Unactivate" 2 "Activate" 3 "Reserved" ;
VAL_ 1453 ICC_MemAttributeFR 0 "Not Active" 1 "Children" 2 "Youth" 3 "Oldman" 4 "reserved" 5 "reserved" 6 "reserved" 7 "reserved" ;
VAL_ 1453 ICC_MemAttributeFL 0 "Not Active" 1 "Children" 2 "Youth" 3 "Oldman" 4 "reserved" 5 "reserved" 6 "reserved" 7 "reserved" ;
VAL_ 1453 ICC_MemAttributeRR 0 "Not Active" 1 "Children" 2 "Youth" 3 "Oldman" 4 "reserved" 5 "reserved" 6 "reserved" 7 "reserved" ;
VAL_ 1453 ICC_MemAttributeRL 0 "Not Active" 1 "Children" 2 "Youth" 3 "Oldman" 4 "reserved" 5 "reserved" 6 "reserved" 7 "reserved" ;
VAL_ 1453 ICC_CrossBorderMode 0 "Not Active" 1 "On" 2 "Off" 3 "Reserved" ;
VAL_ 1453 ICC_BedStatus 0 "Not Active" 1 "Large Bed At Home" 2 "Single Bed" 3 "Sofa For Parking" 4 "Travel Bed" 5 "Pause" 6 "Reserved" 7 "OFF" ;
VAL_ 1531 BMS_HvBattSoeActDisChaCyc 65534 "Abnormal" 65535 "Invalid" ;
VAL_ 1531 BMS_HvBattSoeActReChaCyc 65534 "Abnormal" 65535 "Invalid" ;
VAL_ 1531 BMS_HvBattRatedEnergy 16382 "Abnormal" 16383 "Invalid" ;
VAL_ 1531 BMS_HvBattRatedU 16382 "Abnormal" 16383 "Invalid" ;
VAL_ 1531 BMS_HvBattTypeCode 0 "reserved" 1 "LFP" 2 "LMO" 3 "LCO" 4 "NCM" 5 "Polymer Lithium ion" 6 "Supercapacitors" 7 "LTO" 252 "Fuel Cell" 255 "other type" ;
VAL_ 1531 BMS_HvBattManufcCode -2147483648 "Invalid" -2147483648 "Abnormal" ;
VAL_ 1531 BMS_HvBattTempSensorTempMaxNum 254 "Abnormal" 255 "Invalid" ;
VAL_ 1531 BMS_HvBattTempSensorTempMinNum 254 "Abnormal" 255 "Invalid" ;
VAL_ 1531 BMS_HvBattTempMaxNum 254 "Abnormal" 255 "Invalid" ;
VAL_ 1531 BMS_HvBattTempMinNum 254 "Abnormal" 255 "Invalid" ;
VAL_ 1531 BMS_BattCellTotalNum 65534 "Abnormal" 65535 "Invalid" ;
VAL_ 1531 BMS_HvBattVoltMaxNum 254 "Abnormal" 255 "Invalid" ;
VAL_ 1531 BMS_HvBattVoltMinNum 254 "Abnormal" 255 "Invalid" ;
VAL_ 1531 BMS_ActualSOCMin 4095 "Invalid" ;
VAL_ 1531 BMS_ActualSOCMax 4095 "Invalid" ;
VAL_ 1560 RMR_ICC 0 "Inactive" 1 "Active" ;
VAL_ 1560 ICC_Wakeup_Poweron 0 "Inactive" 1 "Active" ;
VAL_ 1560 ICC_Wakeup_NM 0 "Inactive" 1 "Active" ;
VAL_ 1560 ICC_Wakeup_Diag 0 "Inactive" 1 "Active" ;
VAL_ 1560 ICC_Wakeup_PowerComfortable 0 "Inactive" 1 "Active" ;
VAL_ 1560 ICC_Wakeup_HUD 0 "Inactive" 1 "Active" ;
VAL_ 1560 ICC_Wakeup_EAMP 0 "Inactive" 1 "Active" ;
VAL_ 1560 ICC_Awake_Poweron 0 "Inactive" 1 "Active" ;
VAL_ 1560 ICC_Awake_NM 0 "Inactive" 1 "Active" ;
VAL_ 1560 ICC_Awake_Diag 0 "Inactive" 1 "Active" ;
VAL_ 1560 ICC_Awake_PowerComfortable 0 "Inactive" 1 "Active" ;
VAL_ 1560 ICC_Awake_SentinelMode 0 "Inactive" 1 "Active" ;
VAL_ 1560 ICC_Awake_PetMode 0 "Inactive" 1 "Active" ;
VAL_ 1560 ICC_Awake_HUD 0 "Inactive" 1 "Active" ;
VAL_ 1560 ICC_Awake_EAMP 0 "Inactive" 1 "Active" ;
VAL_ 1560 ICC_Awake_FreezerFunction 0 "Inactive" 1 "Active" ;
VAL_ 1560 ICC_Awake_PowerOffDelay 0 "Inactive" 1 "Active" ;
VAL_ 1560 ICC_Awake_VehLockDwnLoad_618h 0 "Inactive" 1 "Active" ;
